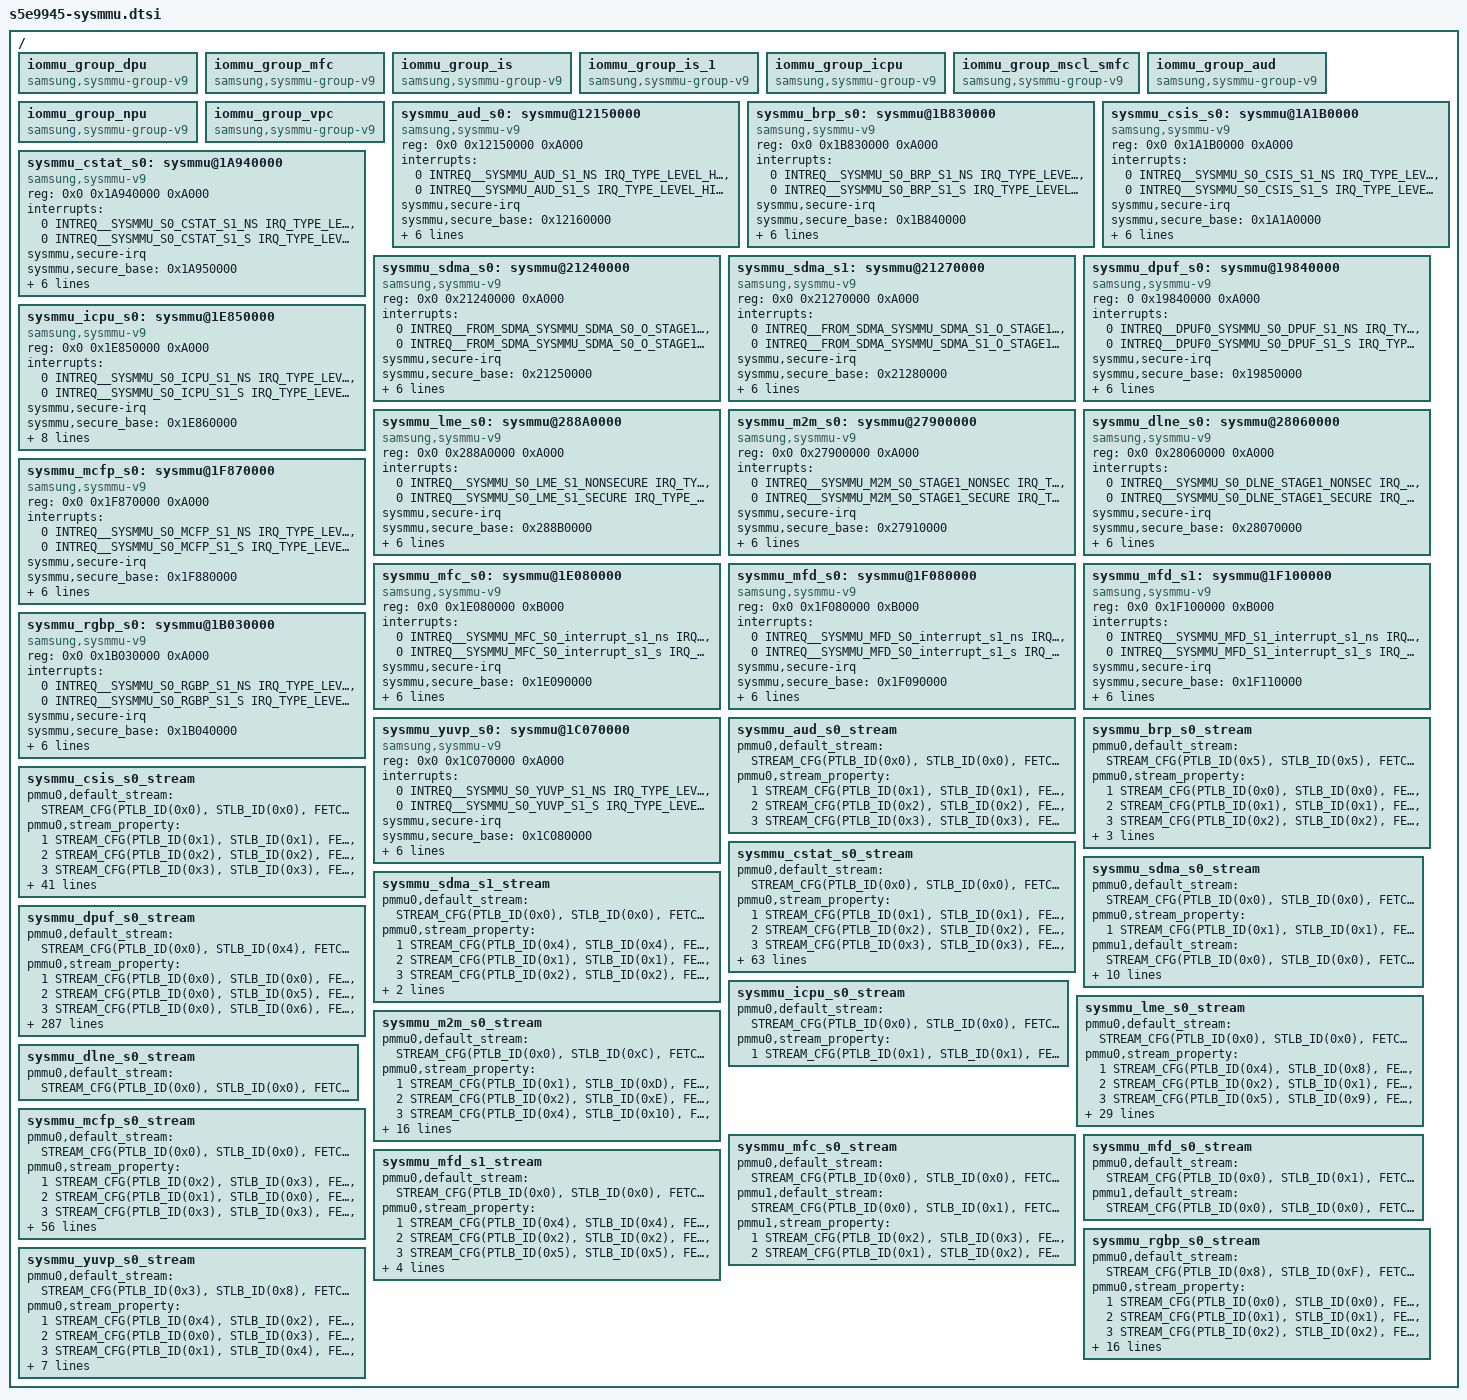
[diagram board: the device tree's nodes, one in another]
// SPDX-License-Identifier: GPL-2.0
/*
 * SAMSUNG S5E9945 SoC device tree source
 *
 * Copyright (c) 2022 Samsung Electronics Co., Ltd.
 *      http://www.samsung.com
 *
 * SAMSUNG S5E9945 SoC device nodes are listed in this file.
 * S5E9945 based board files can include this file and provide
 * values for board specific bindings.
 *
 * This program is free software; you can redistribute it and/or modify
 * it under the terms of the GNU General Public License version 2 as
 * published by the Free Software Foundation.
 */

#include <dt-bindings/interrupt-controller/arm-gic.h>
#include <dt-bindings/soc/samsung,sysmmu-v9.h>

/ {
	iommu_group_dpu: iommu_group_dpu {
		compatible = "samsung,sysmmu-group-v9";
	};

	iommu_group_mfc: iommu_group_mfc {
		compatible = "samsung,sysmmu-group-v9";
	};

	iommu_group_is: iommu_group_is {
		compatible = "samsung,sysmmu-group-v9";
	};

	iommu_group_is_1: iommu_group_is_1 {
		compatible = "samsung,sysmmu-group-v9";
	};

	iommu_group_icpu: iommu_group_icpu {
		compatible = "samsung,sysmmu-group-v9";
	};

	iommu_group_mscl_smfc: iommu_group_mscl_smfc {
		compatible = "samsung,sysmmu-group-v9";
	};

	iommu_group_aud: iommu_group_aud {
		compatible = "samsung,sysmmu-group-v9";
	};

	iommu_group_npu: iommu_group_npu {
		compatible = "samsung,sysmmu-group-v9";
	};

	iommu_group_vpc: iommu_group_vpc {
		compatible = "samsung,sysmmu-group-v9";
	};

	sysmmu_aud_s0: sysmmu@12150000 {
		compatible = "samsung,sysmmu-v9";
		reg = <0x0 0x12150000 0xA000>;
		interrupts = <0 INTREQ__SYSMMU_AUD_S1_NS IRQ_TYPE_LEVEL_HIGH>,
				<0 INTREQ__SYSMMU_AUD_S1_S IRQ_TYPE_LEVEL_HIGH>;
		sysmmu,secure-irq;
		sysmmu,secure_base = <0x12160000>;
		qos = <15>;
		#iommu-cells = <0>;
		stream-property = <&sysmmu_aud_s0_stream>;
		vmid_mask = <0x3>;
		sysmmu,feature-info = <0x1>;
		port-name = "ABOX (CA32_0) ABOX (CA32_1) ...";
		power-domains = <&pd_aud>;
	};

	sysmmu_brp_s0: sysmmu@1B830000 {
		compatible = "samsung,sysmmu-v9";
		reg = <0x0 0x1B830000 0xA000>;
		interrupts = <0 INTREQ__SYSMMU_S0_BRP_S1_NS IRQ_TYPE_LEVEL_HIGH>,
				<0 INTREQ__SYSMMU_S0_BRP_S1_S IRQ_TYPE_LEVEL_HIGH>;
		sysmmu,secure-irq;
		sysmmu,secure_base = <0x1B840000>;
		qos = <15>;
		#iommu-cells = <0>;
		stream-property = <&sysmmu_brp_s0_stream>;
		vmid_mask = <0x3>;
		sysmmu,feature-info = <0x1>;
		port-name = "BYRP (M0) BYRP (M0) BYRP (M ...";
		power-domains = <&pd_brp>;
	};

	sysmmu_csis_s0: sysmmu@1A1B0000 {
		compatible = "samsung,sysmmu-v9";
		reg = <0x0 0x1A1B0000 0xA000>;
		interrupts = <0 INTREQ__SYSMMU_S0_CSIS_S1_NS IRQ_TYPE_LEVEL_HIGH>,
				<0 INTREQ__SYSMMU_S0_CSIS_S1_S IRQ_TYPE_LEVEL_HIGH>;
		sysmmu,secure-irq;
		sysmmu,secure_base = <0x1A1A0000>;
		qos = <15>;
		#iommu-cells = <0>;
		stream-property = <&sysmmu_csis_s0_stream>;
		vmid_mask = <0x3>;
		sysmmu,feature-info = <0x1>;
		port-name = "CSISX7_V1.0 (CSIS DMA0) CSI ...";
		power-domains = <&pd_csis>;
	};

	sysmmu_cstat_s0: sysmmu@1A940000 {
		compatible = "samsung,sysmmu-v9";
		reg = <0x0 0x1A940000 0xA000>;
		interrupts = <0 INTREQ__SYSMMU_S0_CSTAT_S1_NS IRQ_TYPE_LEVEL_HIGH>,
				<0 INTREQ__SYSMMU_S0_CSTAT_S1_S IRQ_TYPE_LEVEL_HIGH>;
		sysmmu,secure-irq;
		sysmmu,secure_base = <0x1A950000>;
		qos = <15>;
		#iommu-cells = <0>;
		stream-property = <&sysmmu_cstat_s0_stream>;
		vmid_mask = <0x3>;
		sysmmu,feature-info = <0x1>;
		port-name = "CSTAT_RD0_RGBYHIST CSTAT_RD ...";
		power-domains = <&pd_cstat>;
	};

	sysmmu_sdma_s0: sysmmu@21240000 {
		compatible = "samsung,sysmmu-v9";
		reg = <0x0 0x21240000 0xA000>;
		interrupts = <0 INTREQ__FROM_SDMA_SYSMMU_SDMA_S0_O_STAGE1_NONSEC IRQ_TYPE_LEVEL_HIGH>,
				<0 INTREQ__FROM_SDMA_SYSMMU_SDMA_S0_O_STAGE1_SECURE IRQ_TYPE_LEVEL_HIGH>;
		sysmmu,secure-irq;
		sysmmu,secure_base = <0x21250000>;
		qos = <15>;
		#iommu-cells = <0>;
		stream-property = <&sysmmu_sdma_s0_stream>;
		vmid_mask = <0x3>;
		sysmmu,feature-info = <0x1>;
		port-name = "IP_SDMA (BUSD0) IP_SDMA (BU ...";
		power-domains = <&pd_sdma>;
	};

	sysmmu_sdma_s1: sysmmu@21270000 {
		compatible = "samsung,sysmmu-v9";
		reg = <0x0 0x21270000 0xA000>;
		interrupts = <0 INTREQ__FROM_SDMA_SYSMMU_SDMA_S1_O_STAGE1_NONSEC IRQ_TYPE_LEVEL_HIGH>,
				<0 INTREQ__FROM_SDMA_SYSMMU_SDMA_S1_O_STAGE1_SECURE IRQ_TYPE_LEVEL_HIGH>;
		sysmmu,secure-irq;
		sysmmu,secure_base = <0x21280000>;
		qos = <15>;
		#iommu-cells = <0>;
		stream-property = <&sysmmu_sdma_s1_stream>;
		vmid_mask = <0x3>;
		sysmmu,feature-info = <0x1>;
		port-name = "IP_DNC (DRAM)";
		power-domains = <&pd_sdma>;
	};

	sysmmu_dpuf_s0: sysmmu@19840000 {
		compatible = "samsung,sysmmu-v9";
		reg = <0 0x19840000 0xA000>;
		interrupts = <0 INTREQ__DPUF0_SYSMMU_S0_DPUF_S1_NS IRQ_TYPE_LEVEL_HIGH>,
				<0 INTREQ__DPUF0_SYSMMU_S0_DPUF_S1_S IRQ_TYPE_LEVEL_HIGH>;
		sysmmu,secure-irq;
		sysmmu,secure_base = <0x19850000>;
		qos = <15>;
		#iommu-cells = <0>;
		stream-property = <&sysmmu_dpuf_s0_stream>;
		vmid_mask = <0x3>;
		sysmmu,feature-info = <0x1>;
		port-name = "DPU_DMA_TOP";
		power-domains = <&pd_dpuf1>;
	};

	sysmmu_icpu_s0: sysmmu@1E850000 {
		compatible = "samsung,sysmmu-v9";
		reg = <0x0 0x1E850000 0xA000>;
		interrupts = <0 INTREQ__SYSMMU_S0_ICPU_S1_NS IRQ_TYPE_LEVEL_HIGH>,
				<0 INTREQ__SYSMMU_S0_ICPU_S1_S  IRQ_TYPE_LEVEL_HIGH>;
		sysmmu,secure-irq;
		sysmmu,secure_base = <0x1E860000>;
		sysmmu,async-fault;
		qos = <15>;
		#iommu-cells = <0>;
		stream-property = <&sysmmu_icpu_s0_stream>;
		vmid_mask = <0x3>;
		sysmmu,feature-info = <0x1>;
		sysmmu,cacheable-override;
		port-name = "ICPU (CA53)";
		power-domains = <&pd_icpu>;
	};

	sysmmu_lme_s0: sysmmu@288A0000 {
		compatible = "samsung,sysmmu-v9";
		reg = <0x0 0x288A0000 0xA000>;
		interrupts = <0 INTREQ__SYSMMU_S0_LME_S1_NONSECURE IRQ_TYPE_LEVEL_HIGH>,
				<0 INTREQ__SYSMMU_S0_LME_S1_SECURE IRQ_TYPE_LEVEL_HIGH>;
		sysmmu,secure-irq;
		sysmmu,secure_base = <0x288B0000>;
		qos = <15>;
		#iommu-cells = <0>;
		stream-property = <&sysmmu_lme_s0_stream>;
		vmid_mask = <0x3>;
		sysmmu,feature-info = <0x1>;
		port-name = "GDC_M (M0) GDC_M (M1) GDC_M ...";
		power-domains = <&pd_lme>;
	};

	sysmmu_m2m_s0: sysmmu@27900000 {
		compatible = "samsung,sysmmu-v9";
		reg = <0x0 0x27900000 0xA000>;
		interrupts = <0 INTREQ__SYSMMU_M2M_S0_STAGE1_NONSEC IRQ_TYPE_LEVEL_HIGH>,
				<0 INTREQ__SYSMMU_M2M_S0_STAGE1_SECURE IRQ_TYPE_LEVEL_HIGH>;
		sysmmu,secure-irq;
		sysmmu,secure_base = <0x27910000>;
		qos = <15>;
		#iommu-cells = <0>;
		stream-property = <&sysmmu_m2m_s0_stream>;
		vmid_mask = <0x3>;
		sysmmu,feature-info = <0x1>;
		port-name = "JPEG0 JPEG1 M2M(M2M_SCALER_ ...)";
		power-domains = <&pd_m2m>;
	};

	sysmmu_dlne_s0: sysmmu@28060000 {
		compatible = "samsung,sysmmu-v9";
		reg = <0x0 0x28060000 0xA000>;
		interrupts = <0 INTREQ__SYSMMU_S0_DLNE_STAGE1_NONSEC IRQ_TYPE_LEVEL_HIGH>,
				<0 INTREQ__SYSMMU_S0_DLNE_STAGE1_SECURE IRQ_TYPE_LEVEL_HIGH>;
		sysmmu,secure-irq;
		sysmmu,secure_base = <0x28070000>;
		qos = <15>;
		#iommu-cells = <0>;
		stream-property = <&sysmmu_dlne_s0_stream>;
		vmid_mask = <0x3>;
		sysmmu,feature-info = <0x1>;
		port-name = "DLNE_M0";
		power-domains = <&pd_dlne>;
	};

	sysmmu_mcfp_s0: sysmmu@1F870000 {
		compatible = "samsung,sysmmu-v9";
		reg = <0x0 0x1F870000 0xA000>;
		interrupts = <0 INTREQ__SYSMMU_S0_MCFP_S1_NS IRQ_TYPE_LEVEL_HIGH>,
				<0 INTREQ__SYSMMU_S0_MCFP_S1_S IRQ_TYPE_LEVEL_HIGH>;
		sysmmu,secure-irq;
		sysmmu,secure_base = <0x1F880000>;
		qos = <15>;
		#iommu-cells = <0>;
		stream-property = <&sysmmu_mcfp_s0_stream>;
		vmid_mask = <0x3>;
		sysmmu,feature-info = <0x1>;
		port-name = "MCFP_M0 MCFP_M1 MCSC_M1 MCS ...";
		power-domains = <&pd_mcsc>;
	};

	sysmmu_mfc_s0: sysmmu@1E080000 {
		compatible = "samsung,sysmmu-v9";
		reg = <0x0 0x1E080000 0xB000>;
		interrupts = <0 INTREQ__SYSMMU_MFC_S0_interrupt_s1_ns IRQ_TYPE_LEVEL_HIGH>,
				<0 INTREQ__SYSMMU_MFC_S0_interrupt_s1_s IRQ_TYPE_LEVEL_HIGH>;
		sysmmu,secure-irq;
		sysmmu,secure_base = <0x1E090000>;
		qos = <15>;
		#iommu-cells = <0>;
		stream-property = <&sysmmu_mfc_s0_stream>;
		vmid_mask = <0x7>;
		sysmmu,feature-info = <0x1>;
		port-name = "FIMV_MFC_V18.0 (M0) FIMV_MF ...";
		power-domains = <&pd_mfc>;
	};

	sysmmu_mfd_s0: sysmmu@1F080000 {
		compatible = "samsung,sysmmu-v9";
		reg = <0x0 0x1F080000 0xB000>;
		interrupts = <0 INTREQ__SYSMMU_MFD_S0_interrupt_s1_ns IRQ_TYPE_LEVEL_HIGH>,
				<0 INTREQ__SYSMMU_MFD_S0_interrupt_s1_s IRQ_TYPE_LEVEL_HIGH>;
		sysmmu,secure-irq;
		sysmmu,secure_base = <0x1F090000>;
		qos = <15>;
		#iommu-cells = <0>;
		stream-property = <&sysmmu_mfd_s0_stream>;
		vmid_mask = <0x7>;
		sysmmu,feature-info = <0x1>;
		port-name = "FIMV_MFD_V18.0 (M0) FIMV_MF ...";
		power-domains = <&pd_mfd>;
	};

	sysmmu_mfd_s1: sysmmu@1F100000 {
		compatible = "samsung,sysmmu-v9";
		reg = <0x0 0x1F100000 0xB000>;
		interrupts = <0 INTREQ__SYSMMU_MFD_S1_interrupt_s1_ns IRQ_TYPE_LEVEL_HIGH>,
				<0 INTREQ__SYSMMU_MFD_S1_interrupt_s1_s IRQ_TYPE_LEVEL_HIGH>;
		sysmmu,secure-irq;
		sysmmu,secure_base = <0x1F110000>;
		qos = <15>;
		#iommu-cells = <0>;
		stream-property = <&sysmmu_mfd_s1_stream>;
		vmid_mask = <0x7>;
		sysmmu,feature-info = <0x1>;
		port-name = "FIMV_MFD_V18.0 (M2) FIMV_MF ...";
		power-domains = <&pd_mfd>;
	};

	sysmmu_rgbp_s0: sysmmu@1B030000 {
		compatible = "samsung,sysmmu-v9";
		reg = <0x0 0x1B030000 0xA000>;
		interrupts = <0 INTREQ__SYSMMU_S0_RGBP_S1_NS IRQ_TYPE_LEVEL_HIGH>,
				<0 INTREQ__SYSMMU_S0_RGBP_S1_S IRQ_TYPE_LEVEL_HIGH>;
		sysmmu,secure-irq;
		sysmmu,secure_base = <0x1B040000>;
		qos = <15>;
		#iommu-cells = <0>;
		stream-property = <&sysmmu_rgbp_s0_stream>;
		vmid_mask = <0x3>;
		sysmmu,feature-info = <0x1>;
		port-name = "RGBP (M0) RGBP (M0) RGBP (M ...";
		power-domains = <&pd_rgbp>;
	};

	sysmmu_yuvp_s0: sysmmu@1C070000 {
		compatible = "samsung,sysmmu-v9";
		reg = <0x0 0x1C070000 0xA000>;
		interrupts = <0 INTREQ__SYSMMU_S0_YUVP_S1_NS IRQ_TYPE_LEVEL_HIGH>,
				<0 INTREQ__SYSMMU_S0_YUVP_S1_S IRQ_TYPE_LEVEL_HIGH>;
		sysmmu,secure-irq;
		sysmmu,secure_base = <0x1C080000>;
		qos = <15>;
		#iommu-cells = <0>;
		stream-property = <&sysmmu_yuvp_s0_stream>;
		vmid_mask = <0x3>;
		sysmmu,feature-info = <0x1>;
		port-name = "YUVP_M0_CL_VOTFR YUVP_M1_Y_ ...";
		power-domains = <&pd_yuvp>;
	};

	sysmmu_aud_s0_stream: sysmmu_aud_s0_stream {
		pmmu0,default_stream =
		<STREAM_CFG(PTLB_ID(0x0), STLB_ID(0x0), FETCH_SIZE(SIZE1), PTLB_DIS, STLB_DIS)>;
		pmmu0,stream_property =
		<1 STREAM_CFG(PTLB_ID(0x1), STLB_ID(0x1), FETCH_SIZE(SIZE1), PTLB_DIS, STLB_DIS)
		 STREAM_MATCH_CFG(DIR_RW)
		 STREAM_MATCH_SID_VALUE(0x3)
		 STREAM_MATCH_SID_MASK(0xF)>,
		<2 STREAM_CFG(PTLB_ID(0x2), STLB_ID(0x2), FETCH_SIZE(SIZE1), PTLB_DIS, STLB_DIS)
		 STREAM_MATCH_CFG(DIR_RW)
		 STREAM_MATCH_SID_VALUE(0x5)
		 STREAM_MATCH_SID_MASK(0xF)>,
		<3 STREAM_CFG(PTLB_ID(0x3), STLB_ID(0x3), FETCH_SIZE(SIZE1), PTLB_DIS, STLB_DIS)
		 STREAM_MATCH_CFG(DIR_RW)
		 STREAM_MATCH_SID_VALUE(0x6)
		 STREAM_MATCH_SID_MASK(0xF)>;
	};

	sysmmu_brp_s0_stream: sysmmu_brp_s0_stream {
		pmmu0,default_stream =
		<STREAM_CFG(PTLB_ID(0x5), STLB_ID(0x5), FETCH_SIZE(SIZE1), PTLB_DIS, STLB_DIS)>;
		pmmu0,stream_property =
		<1 STREAM_CFG(PTLB_ID(0x0), STLB_ID(0x0), FETCH_SIZE(SIZE1), PTLB_DIS, STLB_EN)
		 STREAM_MATCH_CFG(DIR_WRITE)
		 STREAM_MATCH_SID_VALUE(0x0)
		 STREAM_MATCH_SID_MASK(0xF)>,
		<2 STREAM_CFG(PTLB_ID(0x1), STLB_ID(0x1), FETCH_SIZE(SIZE1), PTLB_EN, STLB_EN)
		 STREAM_MATCH_CFG(DIR_READ)
		 STREAM_MATCH_SID_VALUE(0x1)
		 STREAM_MATCH_SID_MASK(0xF)>,
		<3 STREAM_CFG(PTLB_ID(0x2), STLB_ID(0x2), FETCH_SIZE(SIZE1), PTLB_EN, STLB_EN)
		 STREAM_MATCH_CFG(DIR_READ)
		 STREAM_MATCH_SID_VALUE(0x5)
		 STREAM_MATCH_SID_MASK(0xF)>,
		<4 STREAM_CFG(PTLB_ID(0x3), STLB_ID(0x3), FETCH_SIZE(SIZE1), PTLB_DIS, STLB_EN)
		 STREAM_MATCH_CFG(DIR_WRITE)
		 STREAM_MATCH_SID_VALUE(0x1)
		 STREAM_MATCH_SID_MASK(0xF)>,
		<5 STREAM_CFG(PTLB_ID(0x4), STLB_ID(0x4), FETCH_SIZE(SIZE1), PTLB_DIS, STLB_EN)
		 STREAM_MATCH_CFG(DIR_WRITE)
		 STREAM_MATCH_SID_VALUE(0x2)
		 STREAM_MATCH_SID_MASK(0xF)>,
		<6 STREAM_CFG(PTLB_ID(0x6), STLB_ID(0x6), FETCH_SIZE(SIZE1), PTLB_DIS, STLB_DIS)
		 STREAM_MATCH_CFG(DIR_WRITE)
		 STREAM_MATCH_SID_VALUE(0x3)
		 STREAM_MATCH_SID_MASK(0xF)>;
	};

	sysmmu_csis_s0_stream: sysmmu_csis_s0_stream {
		pmmu0,default_stream =
		<STREAM_CFG(PTLB_ID(0x0), STLB_ID(0x0), FETCH_SIZE(SIZE1), PTLB_DIS, STLB_EN)>;
		pmmu0,stream_property =
		<1 STREAM_CFG(PTLB_ID(0x1), STLB_ID(0x1), FETCH_SIZE(SIZE1), PTLB_DIS, STLB_EN)
		 STREAM_MATCH_CFG(DIR_WRITE)
		 STREAM_MATCH_SID_VALUE(0x2)
		 STREAM_MATCH_SID_MASK(0xF)>,
		<2 STREAM_CFG(PTLB_ID(0x2), STLB_ID(0x2), FETCH_SIZE(SIZE1), PTLB_DIS, STLB_EN)
		 STREAM_MATCH_CFG(DIR_WRITE)
		 STREAM_MATCH_SID_VALUE(0x4)
		 STREAM_MATCH_SID_MASK(0xF)>,
		<3 STREAM_CFG(PTLB_ID(0x3), STLB_ID(0x3), FETCH_SIZE(SIZE1), PTLB_DIS, STLB_EN)
		 STREAM_MATCH_CFG(DIR_WRITE)
		 STREAM_MATCH_SID_VALUE(0x8)
		 STREAM_MATCH_SID_MASK(0xF)>,
		<4 STREAM_CFG(PTLB_ID(0x4), STLB_ID(0x4), FETCH_SIZE(SIZE1), PTLB_DIS, STLB_EN)
		 STREAM_MATCH_CFG(DIR_WRITE)
		 STREAM_MATCH_SID_VALUE(0xC)
		 STREAM_MATCH_SID_MASK(0xF)>,
		<5 STREAM_CFG(PTLB_ID(0x5), STLB_ID(0x5), FETCH_SIZE(SIZE1), PTLB_DIS, STLB_EN)
		 STREAM_MATCH_CFG(DIR_WRITE)
		 STREAM_MATCH_SID_VALUE(0x1)
		 STREAM_MATCH_SID_MASK(0xF)>,
		<6 STREAM_CFG(PTLB_ID(0x6), STLB_ID(0x6), FETCH_SIZE(SIZE1), PTLB_DIS, STLB_EN)
		 STREAM_MATCH_CFG(DIR_WRITE)
		 STREAM_MATCH_SID_VALUE(0x3)
		 STREAM_MATCH_SID_MASK(0xF)>,
		<7 STREAM_CFG(PTLB_ID(0x7), STLB_ID(0x7), FETCH_SIZE(SIZE1), PTLB_DIS, STLB_EN)
		 STREAM_MATCH_CFG(DIR_WRITE)
		 STREAM_MATCH_SID_VALUE(0x5)
		 STREAM_MATCH_SID_MASK(0xF)>,
		<8 STREAM_CFG(PTLB_ID(0x8), STLB_ID(0x8), FETCH_SIZE(SIZE1), PTLB_DIS, STLB_EN)
		 STREAM_MATCH_CFG(DIR_WRITE)
		 STREAM_MATCH_SID_VALUE(0x9)
		 STREAM_MATCH_SID_MASK(0xF)>,
		<9 STREAM_CFG(PTLB_ID(0x9), STLB_ID(0x9), FETCH_SIZE(SIZE1), PTLB_DIS, STLB_EN)
		 STREAM_MATCH_CFG(DIR_WRITE)
		 STREAM_MATCH_SID_VALUE(0xD)
		 STREAM_MATCH_SID_MASK(0xF)>;
		pmmu1,default_stream =
		<STREAM_CFG(PTLB_ID(0x0), STLB_ID(0xA), FETCH_SIZE(SIZE1), PTLB_DIS, STLB_EN)>;
		pmmu1,stream_property =
		<1 STREAM_CFG(PTLB_ID(0x1), STLB_ID(0xB), FETCH_SIZE(SIZE1), PTLB_DIS, STLB_EN)
		 STREAM_MATCH_CFG(DIR_WRITE)
		 STREAM_MATCH_SID_VALUE(0x4)
		 STREAM_MATCH_SID_MASK(0x1F)>,
		<2 STREAM_CFG(PTLB_ID(0x2), STLB_ID(0xC), FETCH_SIZE(SIZE1), PTLB_DIS, STLB_EN)
		 STREAM_MATCH_CFG(DIR_WRITE)
		 STREAM_MATCH_SID_VALUE(0x8)
		 STREAM_MATCH_SID_MASK(0x1F)>,
		<3 STREAM_CFG(PTLB_ID(0x3), STLB_ID(0xD), FETCH_SIZE(SIZE1), PTLB_DIS, STLB_EN)
		 STREAM_MATCH_CFG(DIR_WRITE)
		 STREAM_MATCH_SID_VALUE(0x10)
		 STREAM_MATCH_SID_MASK(0x1F)>,
		<4 STREAM_CFG(PTLB_ID(0x4), STLB_ID(0xE), FETCH_SIZE(SIZE1), PTLB_DIS, STLB_EN)
		 STREAM_MATCH_CFG(DIR_WRITE)
		 STREAM_MATCH_SID_VALUE(0x18)
		 STREAM_MATCH_SID_MASK(0x1F)>,
		<5 STREAM_CFG(PTLB_ID(0x5), STLB_ID(0xF), FETCH_SIZE(SIZE1), PTLB_DIS, STLB_EN)
		 STREAM_MATCH_CFG(DIR_WRITE)
		 STREAM_MATCH_SID_VALUE(0x1)
		 STREAM_MATCH_SID_MASK(0x1F)>,
		<6 STREAM_CFG(PTLB_ID(0x6), STLB_ID(0x10), FETCH_SIZE(SIZE1), PTLB_DIS, STLB_EN)
		 STREAM_MATCH_CFG(DIR_WRITE)
		 STREAM_MATCH_SID_VALUE(0x5)
		 STREAM_MATCH_SID_MASK(0x1F)>,
		<7 STREAM_CFG(PTLB_ID(0x7), STLB_ID(0x11), FETCH_SIZE(SIZE1), PTLB_DIS, STLB_EN)
		 STREAM_MATCH_CFG(DIR_WRITE)
		 STREAM_MATCH_SID_VALUE(0x9)
		 STREAM_MATCH_SID_MASK(0x1F)>,
		<8 STREAM_CFG(PTLB_ID(0x8), STLB_ID(0x12), FETCH_SIZE(SIZE1), PTLB_DIS, STLB_EN)
		 STREAM_MATCH_CFG(DIR_WRITE)
		 STREAM_MATCH_SID_VALUE(0x11)
		 STREAM_MATCH_SID_MASK(0x1F)>,
		<9 STREAM_CFG(PTLB_ID(0x9), STLB_ID(0x13), FETCH_SIZE(SIZE1), PTLB_DIS, STLB_EN)
		 STREAM_MATCH_CFG(DIR_WRITE)
		 STREAM_MATCH_SID_VALUE(0x19)
		 STREAM_MATCH_SID_MASK(0x1F)>,
		<10 STREAM_CFG(PTLB_ID(0xA), STLB_ID(0x14), FETCH_SIZE(SIZE1), PTLB_DIS, STLB_EN)
		 STREAM_MATCH_CFG(DIR_WRITE)
		 STREAM_MATCH_SID_VALUE(0x2)
		 STREAM_MATCH_SID_MASK(0x1F)>,
		<11 STREAM_CFG(PTLB_ID(0xB), STLB_ID(0x15), FETCH_SIZE(SIZE1), PTLB_DIS, STLB_EN)
		 STREAM_MATCH_CFG(DIR_WRITE)
		 STREAM_MATCH_SID_VALUE(0x6)
		 STREAM_MATCH_SID_MASK(0x1F)>,
		<12 STREAM_CFG(PTLB_ID(0xC), STLB_ID(0x16), FETCH_SIZE(SIZE1), PTLB_DIS, STLB_EN)
		 STREAM_MATCH_CFG(DIR_WRITE)
		 STREAM_MATCH_SID_VALUE(0xA)
		 STREAM_MATCH_SID_MASK(0x1F)>,
		<13 STREAM_CFG(PTLB_ID(0xD), STLB_ID(0x17), FETCH_SIZE(SIZE1), PTLB_DIS, STLB_EN)
		 STREAM_MATCH_CFG(DIR_WRITE)
		 STREAM_MATCH_SID_VALUE(0x12)
		 STREAM_MATCH_SID_MASK(0x1F)>,
		<14 STREAM_CFG(PTLB_ID(0xE), STLB_ID(0x18), FETCH_SIZE(SIZE1), PTLB_DIS, STLB_EN)
		 STREAM_MATCH_CFG(DIR_WRITE)
		 STREAM_MATCH_SID_VALUE(0x1A)
		 STREAM_MATCH_SID_MASK(0x1F)>;
		pmmu2,default_stream =
		<STREAM_CFG(PTLB_ID(0xD), STLB_ID(0x26), FETCH_SIZE(SIZE1), PTLB_DIS, STLB_DIS)>;
		pmmu2,stream_property =
		<1 STREAM_CFG(PTLB_ID(0xE), STLB_ID(0x27), FETCH_SIZE(SIZE1), PTLB_DIS, STLB_DIS)
		 STREAM_MATCH_CFG(DIR_WRITE)
		 STREAM_MATCH_SID_VALUE(0x4)
		 STREAM_MATCH_SID_MASK(0x7)>,
		<2 STREAM_CFG(PTLB_ID(0x0), STLB_ID(0x19), FETCH_SIZE(SIZE1), PTLB_DIS, STLB_EN)
		 STREAM_MATCH_CFG(DIR_WRITE)
		 STREAM_MATCH_SID_VALUE(0x0)
		 STREAM_MATCH_SID_MASK(0xFF)>,
		<3 STREAM_CFG(PTLB_ID(0x1), STLB_ID(0x1A), FETCH_SIZE(SIZE1), PTLB_EN, STLB_EN)
		 STREAM_MATCH_CFG(DIR_READ)
		 STREAM_MATCH_SID_VALUE(0x0)
		 STREAM_MATCH_SID_MASK(0xFF)>,
		<4 STREAM_CFG(PTLB_ID(0x2), STLB_ID(0x1B), FETCH_SIZE(SIZE1), PTLB_DIS, STLB_EN)
		 STREAM_MATCH_CFG(DIR_WRITE)
		 STREAM_MATCH_SID_VALUE(0x40)
		 STREAM_MATCH_SID_MASK(0xFF)>,
		<5 STREAM_CFG(PTLB_ID(0x3), STLB_ID(0x1C), FETCH_SIZE(SIZE1), PTLB_DIS, STLB_EN)
		 STREAM_MATCH_CFG(DIR_WRITE)
		 STREAM_MATCH_SID_VALUE(0x80)
		 STREAM_MATCH_SID_MASK(0xFF)>,
		<6 STREAM_CFG(PTLB_ID(0x4), STLB_ID(0x1D), FETCH_SIZE(SIZE1), PTLB_DIS, STLB_EN)
		 STREAM_MATCH_CFG(DIR_WRITE)
		 STREAM_MATCH_SID_VALUE(0xC0)
		 STREAM_MATCH_SID_MASK(0xFF)>,
		<7 STREAM_CFG(PTLB_ID(0x5), STLB_ID(0x1E), FETCH_SIZE(SIZE1), PTLB_DIS, STLB_EN)
		 STREAM_MATCH_CFG(DIR_WRITE)
		 STREAM_MATCH_SID_VALUE(0x1)
		 STREAM_MATCH_SID_MASK(0xFF)>,
		<8 STREAM_CFG(PTLB_ID(0x6), STLB_ID(0x1F), FETCH_SIZE(SIZE1), PTLB_DIS, STLB_EN)
		 STREAM_MATCH_CFG(DIR_WRITE)
		 STREAM_MATCH_SID_VALUE(0x41)
		 STREAM_MATCH_SID_MASK(0xFF)>,
		<9 STREAM_CFG(PTLB_ID(0x7), STLB_ID(0x20), FETCH_SIZE(SIZE1), PTLB_DIS, STLB_EN)
		 STREAM_MATCH_CFG(DIR_WRITE)
		 STREAM_MATCH_SID_VALUE(0x81)
		 STREAM_MATCH_SID_MASK(0xFF)>,
		<10 STREAM_CFG(PTLB_ID(0x8), STLB_ID(0x21), FETCH_SIZE(SIZE1), PTLB_DIS, STLB_EN)
		 STREAM_MATCH_CFG(DIR_WRITE)
		 STREAM_MATCH_SID_VALUE(0xC1)
		 STREAM_MATCH_SID_MASK(0xFF)>,
		<11 STREAM_CFG(PTLB_ID(0x9), STLB_ID(0x22), FETCH_SIZE(SIZE1), PTLB_DIS, STLB_EN)
		 STREAM_MATCH_CFG(DIR_WRITE)
		 STREAM_MATCH_SID_VALUE(0x2)
		 STREAM_MATCH_SID_MASK(0xFF)>,
		<12 STREAM_CFG(PTLB_ID(0xA), STLB_ID(0x23), FETCH_SIZE(SIZE1), PTLB_DIS, STLB_EN)
		 STREAM_MATCH_CFG(DIR_WRITE)
		 STREAM_MATCH_SID_VALUE(0x42)
		 STREAM_MATCH_SID_MASK(0xFF)>,
		<13 STREAM_CFG(PTLB_ID(0xB), STLB_ID(0x24), FETCH_SIZE(SIZE1), PTLB_DIS, STLB_EN)
		 STREAM_MATCH_CFG(DIR_WRITE)
		 STREAM_MATCH_SID_VALUE(0x82)
		 STREAM_MATCH_SID_MASK(0xFF)>,
		<14 STREAM_CFG(PTLB_ID(0xC), STLB_ID(0x25), FETCH_SIZE(SIZE1), PTLB_DIS, STLB_EN)
		 STREAM_MATCH_CFG(DIR_WRITE)
		 STREAM_MATCH_SID_VALUE(0xC2)
		 STREAM_MATCH_SID_MASK(0xFF)>,
		<15 STREAM_CFG(PTLB_ID(0xF), STLB_ID(0x28), FETCH_SIZE(SIZE1), PTLB_DIS, STLB_DIS)
		 STREAM_MATCH_CFG(DIR_WRITE)
		 STREAM_MATCH_SID_VALUE(0x5)
		 STREAM_MATCH_SID_MASK(0x7)>;
	};

	sysmmu_cstat_s0_stream: sysmmu_cstat_s0_stream {
		pmmu0,default_stream =
		<STREAM_CFG(PTLB_ID(0x0), STLB_ID(0x0), FETCH_SIZE(SIZE1), PTLB_DIS, STLB_EN)>;
		pmmu0,stream_property =
		<1 STREAM_CFG(PTLB_ID(0x1), STLB_ID(0x1), FETCH_SIZE(SIZE1), PTLB_DIS, STLB_EN)
		 STREAM_MATCH_CFG(DIR_WRITE)
		 STREAM_MATCH_SID_VALUE(0x80)
		 STREAM_MATCH_SID_MASK(0x1FF)>,
		<2 STREAM_CFG(PTLB_ID(0x2), STLB_ID(0x2), FETCH_SIZE(SIZE1), PTLB_DIS, STLB_EN)
		 STREAM_MATCH_CFG(DIR_WRITE)
		 STREAM_MATCH_SID_VALUE(0x100)
		 STREAM_MATCH_SID_MASK(0x1FF)>,
		<3 STREAM_CFG(PTLB_ID(0x3), STLB_ID(0x3), FETCH_SIZE(SIZE1), PTLB_DIS, STLB_EN)
		 STREAM_MATCH_CFG(DIR_WRITE)
		 STREAM_MATCH_SID_VALUE(0x180)
		 STREAM_MATCH_SID_MASK(0x1FF)>,
		<4 STREAM_CFG(PTLB_ID(0x4), STLB_ID(0x4), FETCH_SIZE(SIZE1), PTLB_EN, STLB_EN)
		 STREAM_MATCH_CFG(DIR_READ)
		 STREAM_MATCH_SID_VALUE(0x0)
		 STREAM_MATCH_SID_MASK(0xF)>,
		<5 STREAM_CFG(PTLB_ID(0x15), STLB_ID(0x3C), FETCH_SIZE(SIZE1), PTLB_EN, STLB_EN)
		 STREAM_MATCH_CFG(DIR_READ)
		 STREAM_MATCH_SID_VALUE(0x10)
		 STREAM_MATCH_SID_MASK(0x1F)>,
		<6 STREAM_CFG(PTLB_ID(0x5), STLB_ID(0x5), FETCH_SIZE(SIZE1), PTLB_DIS, STLB_EN)
		 STREAM_MATCH_CFG(DIR_WRITE)
		 STREAM_MATCH_SID_VALUE(0x1)
		 STREAM_MATCH_SID_MASK(0xF)>,
		<7 STREAM_CFG(PTLB_ID(0x5), STLB_ID(0x7), FETCH_SIZE(SIZE1), PTLB_DIS, STLB_EN)
		 STREAM_MATCH_CFG(DIR_WRITE)
		 STREAM_MATCH_SID_VALUE(0x41)
		 STREAM_MATCH_SID_MASK(0x1FF)>,
		<8 STREAM_CFG(PTLB_ID(0x5), STLB_ID(0x8), FETCH_SIZE(SIZE1), PTLB_DIS, STLB_EN)
		 STREAM_MATCH_CFG(DIR_WRITE)
		 STREAM_MATCH_SID_VALUE(0x81)
		 STREAM_MATCH_SID_MASK(0x1FF)>,
		<9 STREAM_CFG(PTLB_ID(0x6), STLB_ID(0x9), FETCH_SIZE(SIZE1), PTLB_EN, STLB_EN)
		 STREAM_MATCH_CFG(DIR_READ)
		 STREAM_MATCH_SID_VALUE(0x1)
		 STREAM_MATCH_SID_MASK(0xF)>,
		<10 STREAM_CFG(PTLB_ID(0x7), STLB_ID(0xA), FETCH_SIZE(SIZE1), PTLB_DIS, STLB_EN)
		 STREAM_MATCH_CFG(DIR_WRITE)
		 STREAM_MATCH_SID_VALUE(0x2)
		 STREAM_MATCH_SID_MASK(0x1FF)>,
		<11 STREAM_CFG(PTLB_ID(0x7), STLB_ID(0xB), FETCH_SIZE(SIZE1), PTLB_DIS, STLB_EN)
		 STREAM_MATCH_CFG(DIR_WRITE)
		 STREAM_MATCH_SID_VALUE(0x82)
		 STREAM_MATCH_SID_MASK(0x1FF)>,
		<12 STREAM_CFG(PTLB_ID(0x7), STLB_ID(0xC), FETCH_SIZE(SIZE1), PTLB_DIS, STLB_EN)
		 STREAM_MATCH_CFG(DIR_WRITE)
		 STREAM_MATCH_SID_VALUE(0x102)
		 STREAM_MATCH_SID_MASK(0x1FF)>,
		<13 STREAM_CFG(PTLB_ID(0x7), STLB_ID(0xD), FETCH_SIZE(SIZE1), PTLB_DIS, STLB_EN)
		 STREAM_MATCH_CFG(DIR_WRITE)
		 STREAM_MATCH_SID_VALUE(0x182)
		 STREAM_MATCH_SID_MASK(0x1FF)>,
		<14 STREAM_CFG(PTLB_ID(0x8), STLB_ID(0xE), FETCH_SIZE(SIZE1), PTLB_EN, STLB_EN)
		 STREAM_MATCH_CFG(DIR_READ)
		 STREAM_MATCH_SID_VALUE(0x2)
		 STREAM_MATCH_SID_MASK(0xF)>,
		<15 STREAM_CFG(PTLB_ID(0x9), STLB_ID(0xF), FETCH_SIZE(SIZE1), PTLB_DIS, STLB_EN)
		 STREAM_MATCH_CFG(DIR_WRITE)
		 STREAM_MATCH_SID_VALUE(0x3)
		 STREAM_MATCH_SID_MASK(0x1FF)>,
		<16 STREAM_CFG(PTLB_ID(0x9), STLB_ID(0x10), FETCH_SIZE(SIZE1), PTLB_DIS, STLB_EN)
		 STREAM_MATCH_CFG(DIR_WRITE)
		 STREAM_MATCH_SID_VALUE(0x83)
		 STREAM_MATCH_SID_MASK(0x1FF)>,
		<17 STREAM_CFG(PTLB_ID(0x9), STLB_ID(0x11), FETCH_SIZE(SIZE1), PTLB_DIS, STLB_EN)
		 STREAM_MATCH_CFG(DIR_WRITE)
		 STREAM_MATCH_SID_VALUE(0x103)
		 STREAM_MATCH_SID_MASK(0x1FF)>,
		<18 STREAM_CFG(PTLB_ID(0x9), STLB_ID(0x12), FETCH_SIZE(SIZE1), PTLB_DIS, STLB_EN)
		 STREAM_MATCH_CFG(DIR_WRITE)
		 STREAM_MATCH_SID_VALUE(0x183)
		 STREAM_MATCH_SID_MASK(0x1FF)>,
		<19 STREAM_CFG(PTLB_ID(0xA), STLB_ID(0x13), FETCH_SIZE(SIZE1), PTLB_EN, STLB_EN)
		 STREAM_MATCH_CFG(DIR_READ)
		 STREAM_MATCH_SID_VALUE(0x3)
		 STREAM_MATCH_SID_MASK(0xF)>,
		<20 STREAM_CFG(PTLB_ID(0xB), STLB_ID(0x14), FETCH_SIZE(SIZE1), PTLB_DIS, STLB_EN)
		 STREAM_MATCH_CFG(DIR_WRITE)
		 STREAM_MATCH_SID_VALUE(0x4)
		 STREAM_MATCH_SID_MASK(0x1FF)>,
		<21 STREAM_CFG(PTLB_ID(0xB), STLB_ID(0x15), FETCH_SIZE(SIZE1), PTLB_DIS, STLB_EN)
		 STREAM_MATCH_CFG(DIR_WRITE)
		 STREAM_MATCH_SID_VALUE(0x84)
		 STREAM_MATCH_SID_MASK(0x1FF)>,
		<22 STREAM_CFG(PTLB_ID(0xB), STLB_ID(0x16), FETCH_SIZE(SIZE1), PTLB_DIS, STLB_EN)
		 STREAM_MATCH_CFG(DIR_WRITE)
		 STREAM_MATCH_SID_VALUE(0x104)
		 STREAM_MATCH_SID_MASK(0x1FF)>,
		<23 STREAM_CFG(PTLB_ID(0xB), STLB_ID(0x17), FETCH_SIZE(SIZE1), PTLB_DIS, STLB_EN)
		 STREAM_MATCH_CFG(DIR_WRITE)
		 STREAM_MATCH_SID_VALUE(0x184)
		 STREAM_MATCH_SID_MASK(0x1FF)>,
		<24 STREAM_CFG(PTLB_ID(0x16), STLB_ID(0x3D), FETCH_SIZE(SIZE1), PTLB_EN, STLB_DIS)
		 STREAM_MATCH_CFG(DIR_READ)
		 STREAM_MATCH_SID_VALUE(0x4)
		 STREAM_MATCH_SID_MASK(0xF)>,
		<25 STREAM_CFG(PTLB_ID(0xC), STLB_ID(0x18), FETCH_SIZE(SIZE1), PTLB_DIS, STLB_EN)
		 STREAM_MATCH_CFG(DIR_WRITE)
		 STREAM_MATCH_SID_VALUE(0x5)
		 STREAM_MATCH_SID_MASK(0x1FF)>,
		<26 STREAM_CFG(PTLB_ID(0xC), STLB_ID(0x19), FETCH_SIZE(SIZE1), PTLB_DIS, STLB_EN)
		 STREAM_MATCH_CFG(DIR_WRITE)
		 STREAM_MATCH_SID_VALUE(0x85)
		 STREAM_MATCH_SID_MASK(0x1FF)>,
		<27 STREAM_CFG(PTLB_ID(0xC), STLB_ID(0x1A), FETCH_SIZE(SIZE1), PTLB_DIS, STLB_EN)
		 STREAM_MATCH_CFG(DIR_WRITE)
		 STREAM_MATCH_SID_VALUE(0x105)
		 STREAM_MATCH_SID_MASK(0x1FF)>,
		<28 STREAM_CFG(PTLB_ID(0xC), STLB_ID(0x1B), FETCH_SIZE(SIZE1), PTLB_DIS, STLB_EN)
		 STREAM_MATCH_CFG(DIR_WRITE)
		 STREAM_MATCH_SID_VALUE(0x185)
		 STREAM_MATCH_SID_MASK(0x1FF)>,
		<29 STREAM_CFG(PTLB_ID(0x17), STLB_ID(0x3E), FETCH_SIZE(SIZE1), PTLB_EN, STLB_DIS)
		 STREAM_MATCH_CFG(DIR_READ)
		 STREAM_MATCH_SID_VALUE(0x5)
		 STREAM_MATCH_SID_MASK(0xF)>,
		<30 STREAM_CFG(PTLB_ID(0xD), STLB_ID(0x1C), FETCH_SIZE(SIZE1), PTLB_DIS, STLB_EN)
		 STREAM_MATCH_CFG(DIR_WRITE)
		 STREAM_MATCH_SID_VALUE(0x6)
		 STREAM_MATCH_SID_MASK(0x1FF)>,
		<31 STREAM_CFG(PTLB_ID(0xD), STLB_ID(0x1D), FETCH_SIZE(SIZE1), PTLB_DIS, STLB_EN)
		 STREAM_MATCH_CFG(DIR_WRITE)
		 STREAM_MATCH_SID_VALUE(0x86)
		 STREAM_MATCH_SID_MASK(0x1FF)>,
		<32 STREAM_CFG(PTLB_ID(0xD), STLB_ID(0x1E), FETCH_SIZE(SIZE1), PTLB_DIS, STLB_EN)
		 STREAM_MATCH_CFG(DIR_WRITE)
		 STREAM_MATCH_SID_VALUE(0x106)
		 STREAM_MATCH_SID_MASK(0x1FF)>,
		<33 STREAM_CFG(PTLB_ID(0xD), STLB_ID(0x1F), FETCH_SIZE(SIZE1), PTLB_DIS, STLB_EN)
		 STREAM_MATCH_CFG(DIR_WRITE)
		 STREAM_MATCH_SID_VALUE(0x186)
		 STREAM_MATCH_SID_MASK(0x1FF)>,
		<34 STREAM_CFG(PTLB_ID(0x18), STLB_ID(0x3F), FETCH_SIZE(SIZE1), PTLB_EN, STLB_DIS)
		 STREAM_MATCH_CFG(DIR_READ)
		 STREAM_MATCH_SID_VALUE(0x6)
		 STREAM_MATCH_SID_MASK(0xF)>,
		<35 STREAM_CFG(PTLB_ID(0xE), STLB_ID(0x20), FETCH_SIZE(SIZE1), PTLB_DIS, STLB_EN)
		 STREAM_MATCH_CFG(DIR_WRITE)
		 STREAM_MATCH_SID_VALUE(0x7)
		 STREAM_MATCH_SID_MASK(0x1FF)>,
		<36 STREAM_CFG(PTLB_ID(0xE), STLB_ID(0x21), FETCH_SIZE(SIZE1), PTLB_DIS, STLB_EN)
		 STREAM_MATCH_CFG(DIR_WRITE)
		 STREAM_MATCH_SID_VALUE(0x87)
		 STREAM_MATCH_SID_MASK(0x1FF)>,
		<37 STREAM_CFG(PTLB_ID(0xE), STLB_ID(0x22), FETCH_SIZE(SIZE1), PTLB_DIS, STLB_EN)
		 STREAM_MATCH_CFG(DIR_WRITE)
		 STREAM_MATCH_SID_VALUE(0x107)
		 STREAM_MATCH_SID_MASK(0x1FF)>,
		<38 STREAM_CFG(PTLB_ID(0xE), STLB_ID(0x23), FETCH_SIZE(SIZE1), PTLB_DIS, STLB_EN)
		 STREAM_MATCH_CFG(DIR_WRITE)
		 STREAM_MATCH_SID_VALUE(0x187)
		 STREAM_MATCH_SID_MASK(0x1FF)>,
		<39 STREAM_CFG(PTLB_ID(0x19), STLB_ID(0x40), FETCH_SIZE(SIZE1), PTLB_EN, STLB_DIS)
		 STREAM_MATCH_CFG(DIR_READ)
		 STREAM_MATCH_SID_VALUE(0x7)
		 STREAM_MATCH_SID_MASK(0xF)>,
		<40 STREAM_CFG(PTLB_ID(0xF), STLB_ID(0x24), FETCH_SIZE(SIZE1), PTLB_DIS, STLB_EN)
		 STREAM_MATCH_CFG(DIR_WRITE)
		 STREAM_MATCH_SID_VALUE(0x8)
		 STREAM_MATCH_SID_MASK(0x1FF)>,
		<41 STREAM_CFG(PTLB_ID(0xF), STLB_ID(0x25), FETCH_SIZE(SIZE1), PTLB_DIS, STLB_EN)
		 STREAM_MATCH_CFG(DIR_WRITE)
		 STREAM_MATCH_SID_VALUE(0x88)
		 STREAM_MATCH_SID_MASK(0x1FF)>,
		<42 STREAM_CFG(PTLB_ID(0xF), STLB_ID(0x26), FETCH_SIZE(SIZE1), PTLB_DIS, STLB_EN)
		 STREAM_MATCH_CFG(DIR_WRITE)
		 STREAM_MATCH_SID_VALUE(0x108)
		 STREAM_MATCH_SID_MASK(0x1FF)>,
		<43 STREAM_CFG(PTLB_ID(0xF), STLB_ID(0x27), FETCH_SIZE(SIZE1), PTLB_DIS, STLB_EN)
		 STREAM_MATCH_CFG(DIR_WRITE)
		 STREAM_MATCH_SID_VALUE(0x188)
		 STREAM_MATCH_SID_MASK(0x1FF)>,
		<44 STREAM_CFG(PTLB_ID(0x10), STLB_ID(0x28), FETCH_SIZE(SIZE1), PTLB_DIS, STLB_EN)
		 STREAM_MATCH_CFG(DIR_WRITE)
		 STREAM_MATCH_SID_VALUE(0x28)
		 STREAM_MATCH_SID_MASK(0x1FF)>,
		<45 STREAM_CFG(PTLB_ID(0x10), STLB_ID(0x29), FETCH_SIZE(SIZE1), PTLB_DIS, STLB_EN)
		 STREAM_MATCH_CFG(DIR_WRITE)
		 STREAM_MATCH_SID_VALUE(0xA8)
		 STREAM_MATCH_SID_MASK(0x1FF)>,
		<46 STREAM_CFG(PTLB_ID(0x10), STLB_ID(0x2A), FETCH_SIZE(SIZE1), PTLB_DIS, STLB_EN)
		 STREAM_MATCH_CFG(DIR_WRITE)
		 STREAM_MATCH_SID_VALUE(0x128)
		 STREAM_MATCH_SID_MASK(0x1FF)>,
		<47 STREAM_CFG(PTLB_ID(0x10), STLB_ID(0x2B), FETCH_SIZE(SIZE1), PTLB_DIS, STLB_EN)
		 STREAM_MATCH_CFG(DIR_WRITE)
		 STREAM_MATCH_SID_VALUE(0x1A8)
		 STREAM_MATCH_SID_MASK(0x1FF)>,
		<48 STREAM_CFG(PTLB_ID(0x11), STLB_ID(0x2C), FETCH_SIZE(SIZE1), PTLB_DIS, STLB_EN)
		 STREAM_MATCH_CFG(DIR_WRITE)
		 STREAM_MATCH_SID_VALUE(0x9)
		 STREAM_MATCH_SID_MASK(0x1FF)>,
		<49 STREAM_CFG(PTLB_ID(0x11), STLB_ID(0x2D), FETCH_SIZE(SIZE1), PTLB_DIS, STLB_EN)
		 STREAM_MATCH_CFG(DIR_WRITE)
		 STREAM_MATCH_SID_VALUE(0x89)
		 STREAM_MATCH_SID_MASK(0x1FF)>,
		<50 STREAM_CFG(PTLB_ID(0x11), STLB_ID(0x2E), FETCH_SIZE(SIZE1), PTLB_DIS, STLB_EN)
		 STREAM_MATCH_CFG(DIR_WRITE)
		 STREAM_MATCH_SID_VALUE(0x109)
		 STREAM_MATCH_SID_MASK(0x1FF)>,
		<51 STREAM_CFG(PTLB_ID(0x11), STLB_ID(0x2F), FETCH_SIZE(SIZE1), PTLB_DIS, STLB_EN)
		 STREAM_MATCH_CFG(DIR_WRITE)
		 STREAM_MATCH_SID_VALUE(0x189)
		 STREAM_MATCH_SID_MASK(0x1FF)>,
		<52 STREAM_CFG(PTLB_ID(0x12), STLB_ID(0x30), FETCH_SIZE(SIZE1), PTLB_DIS, STLB_EN)
		 STREAM_MATCH_CFG(DIR_WRITE)
		 STREAM_MATCH_SID_VALUE(0x29)
		 STREAM_MATCH_SID_MASK(0x1FF)>,
		<53 STREAM_CFG(PTLB_ID(0x12), STLB_ID(0x31), FETCH_SIZE(SIZE1), PTLB_DIS, STLB_EN)
		 STREAM_MATCH_CFG(DIR_WRITE)
		 STREAM_MATCH_SID_VALUE(0xA9)
		 STREAM_MATCH_SID_MASK(0x1FF)>,
		<54 STREAM_CFG(PTLB_ID(0x12), STLB_ID(0x32), FETCH_SIZE(SIZE1), PTLB_DIS, STLB_EN)
		 STREAM_MATCH_CFG(DIR_WRITE)
		 STREAM_MATCH_SID_VALUE(0x129)
		 STREAM_MATCH_SID_MASK(0x1FF)>,
		<55 STREAM_CFG(PTLB_ID(0x12), STLB_ID(0x33), FETCH_SIZE(SIZE1), PTLB_DIS, STLB_EN)
		 STREAM_MATCH_CFG(DIR_WRITE)
		 STREAM_MATCH_SID_VALUE(0x1A9)
		 STREAM_MATCH_SID_MASK(0x1FF)>,
		<56 STREAM_CFG(PTLB_ID(0x13), STLB_ID(0x34), FETCH_SIZE(SIZE1), PTLB_DIS, STLB_EN)
		 STREAM_MATCH_CFG(DIR_WRITE)
		 STREAM_MATCH_SID_VALUE(0xA)
		 STREAM_MATCH_SID_MASK(0x1FF)>,
		<57 STREAM_CFG(PTLB_ID(0x13), STLB_ID(0x35), FETCH_SIZE(SIZE1), PTLB_DIS, STLB_EN)
		 STREAM_MATCH_CFG(DIR_WRITE)
		 STREAM_MATCH_SID_VALUE(0x8A)
		 STREAM_MATCH_SID_MASK(0x1FF)>,
		<58 STREAM_CFG(PTLB_ID(0x13), STLB_ID(0x36), FETCH_SIZE(SIZE1), PTLB_DIS, STLB_EN)
		 STREAM_MATCH_CFG(DIR_WRITE)
		 STREAM_MATCH_SID_VALUE(0x10A)
		 STREAM_MATCH_SID_MASK(0x1FF)>,
		<59 STREAM_CFG(PTLB_ID(0x13), STLB_ID(0x37), FETCH_SIZE(SIZE1), PTLB_DIS, STLB_EN)
		 STREAM_MATCH_CFG(DIR_WRITE)
		 STREAM_MATCH_SID_VALUE(0x18A)
		 STREAM_MATCH_SID_MASK(0x1FF)>,
		<60 STREAM_CFG(PTLB_ID(0x14), STLB_ID(0x38), FETCH_SIZE(SIZE1), PTLB_DIS, STLB_EN)
		 STREAM_MATCH_CFG(DIR_WRITE)
		 STREAM_MATCH_SID_VALUE(0x2A)
		 STREAM_MATCH_SID_MASK(0x1FF)>,
		<61 STREAM_CFG(PTLB_ID(0x14), STLB_ID(0x39), FETCH_SIZE(SIZE1), PTLB_DIS, STLB_EN)
		 STREAM_MATCH_CFG(DIR_WRITE)
		 STREAM_MATCH_SID_VALUE(0xAA)
		 STREAM_MATCH_SID_MASK(0x1FF)>,
		<62 STREAM_CFG(PTLB_ID(0x14), STLB_ID(0x3A), FETCH_SIZE(SIZE1), PTLB_DIS, STLB_EN)
		 STREAM_MATCH_CFG(DIR_WRITE)
		 STREAM_MATCH_SID_VALUE(0x12A)
		 STREAM_MATCH_SID_MASK(0x1FF)>,
		<63 STREAM_CFG(PTLB_ID(0x14), STLB_ID(0x3B), FETCH_SIZE(SIZE1), PTLB_DIS, STLB_EN)
		 STREAM_MATCH_CFG(DIR_WRITE)
		 STREAM_MATCH_SID_VALUE(0x1AA)
		 STREAM_MATCH_SID_MASK(0x1FF)>,
		<64 STREAM_CFG(PTLB_ID(0x1A), STLB_ID(0x41), FETCH_SIZE(SIZE1), PTLB_DIS, STLB_DIS)
		 STREAM_MATCH_CFG(DIR_WRITE)
		 STREAM_MATCH_SID_VALUE(0xB)
		 STREAM_MATCH_SID_MASK(0x1FF)>,
		<65 STREAM_CFG(PTLB_ID(0x1B), STLB_ID(0x42), FETCH_SIZE(SIZE1), PTLB_DIS, STLB_DIS)
		 STREAM_MATCH_CFG(DIR_WRITE)
		 STREAM_MATCH_SID_VALUE(0xC)
		 STREAM_MATCH_SID_MASK(0x1FF)>,
		<66 STREAM_CFG(PTLB_ID(0x1C), STLB_ID(0x43), FETCH_SIZE(SIZE1), PTLB_DIS, STLB_DIS)
		 STREAM_MATCH_CFG(DIR_WRITE)
		 STREAM_MATCH_SID_VALUE(0xD)
		 STREAM_MATCH_SID_MASK(0x1FF)>;
	};

	sysmmu_sdma_s0_stream: sysmmu_sdma_s0_stream {
		pmmu0,default_stream =
		<STREAM_CFG(PTLB_ID(0x0), STLB_ID(0x0), FETCH_SIZE(SIZE8), PTLB_EN, STLB_EN)>;
		pmmu0,stream_property =
		<1 STREAM_CFG(PTLB_ID(0x1), STLB_ID(0x1), FETCH_SIZE(SIZE1), PTLB_DIS, STLB_DIS)
		 STREAM_MATCH_CFG(DIR_RW)
		 STREAM_MATCH_SID_VALUE(0x40)
		 STREAM_MATCH_SID_MASK(0x40)>;
		pmmu1,default_stream =
		<STREAM_CFG(PTLB_ID(0x0), STLB_ID(0x0), FETCH_SIZE(SIZE8), PTLB_EN, STLB_EN)>;
		pmmu1,stream_property =
		<1 STREAM_CFG(PTLB_ID(0x1), STLB_ID(0x1), FETCH_SIZE(SIZE1), PTLB_DIS, STLB_DIS)
		 STREAM_MATCH_CFG(DIR_RW)
		 STREAM_MATCH_SID_VALUE(0x40)
		 STREAM_MATCH_SID_MASK(0x40)>;
		pmmu2,default_stream =
		<STREAM_CFG(PTLB_ID(0x0), STLB_ID(0x0), FETCH_SIZE(SIZE8), PTLB_EN, STLB_EN)>;
		pmmu2,stream_property =
		<1 STREAM_CFG(PTLB_ID(0x1), STLB_ID(0x1), FETCH_SIZE(SIZE1), PTLB_DIS, STLB_DIS)
		 STREAM_MATCH_CFG(DIR_RW)
		 STREAM_MATCH_SID_VALUE(0x40)
		 STREAM_MATCH_SID_MASK(0x40)>;
		pmmu3,default_stream =
		<STREAM_CFG(PTLB_ID(0x0), STLB_ID(0x0), FETCH_SIZE(SIZE8), PTLB_EN, STLB_EN)>;
		pmmu3,stream_property =
		<1 STREAM_CFG(PTLB_ID(0x1), STLB_ID(0x1), FETCH_SIZE(SIZE1), PTLB_DIS, STLB_DIS)
		 STREAM_MATCH_CFG(DIR_RW)
		 STREAM_MATCH_SID_VALUE(0x40)
		 STREAM_MATCH_SID_MASK(0x40)>;
	};

	sysmmu_sdma_s1_stream: sysmmu_sdma_s1_stream {
		pmmu0,default_stream =
		<STREAM_CFG(PTLB_ID(0x0), STLB_ID(0x0), FETCH_SIZE(SIZE1), PTLB_DIS, STLB_DIS)>;
		pmmu0,stream_property =
		<1 STREAM_CFG(PTLB_ID(0x4), STLB_ID(0x4), FETCH_SIZE(SIZE1), PTLB_DIS, STLB_DIS)
		 STREAM_MATCH_CFG(DIR_READ)
		 STREAM_MATCH_SID_VALUE(0x1)
		 STREAM_MATCH_SID_MASK(0xF)>,
		<2 STREAM_CFG(PTLB_ID(0x1), STLB_ID(0x1), FETCH_SIZE(SIZE1), PTLB_DIS, STLB_EN)
		 STREAM_MATCH_CFG(DIR_READ)
		 STREAM_MATCH_SID_VALUE(0x9)
		 STREAM_MATCH_SID_MASK(0xF)>,
		<3 STREAM_CFG(PTLB_ID(0x2), STLB_ID(0x2), FETCH_SIZE(SIZE1), PTLB_EN, STLB_EN)
		 STREAM_MATCH_CFG(DIR_READ)
		 STREAM_MATCH_SID_VALUE(0x2)
		 STREAM_MATCH_SID_MASK(0xF)>,
		<4 STREAM_CFG(PTLB_ID(0x3), STLB_ID(0x3), FETCH_SIZE(SIZE1), PTLB_EN, STLB_EN)
		 STREAM_MATCH_CFG(DIR_READ)
		 STREAM_MATCH_SID_VALUE(0x3)
		 STREAM_MATCH_SID_MASK(0xF)>,
		<5 STREAM_CFG(PTLB_ID(0x5), STLB_ID(0x5), FETCH_SIZE(SIZE1), PTLB_DIS, STLB_DIS)
		 STREAM_MATCH_CFG(DIR_WRITE)
		 STREAM_MATCH_SID_VALUE(0x4)
		 STREAM_MATCH_SID_MASK(0xF)>;
	};

	sysmmu_dpuf_s0_stream: sysmmu_dpuf_s0_stream {
		pmmu0,default_stream =
		<STREAM_CFG(PTLB_ID(0x0), STLB_ID(0x4), FETCH_SIZE(SIZE16), PTLB_EN, STLB_EN)>;
		pmmu0,stream_property =
		<1 STREAM_CFG(PTLB_ID(0x0), STLB_ID(0x0), FETCH_SIZE(SIZE64), PTLB_DIS, STLB_DIS)
		 STREAM_MATCH_CFG(DIR_READ)
		 STREAM_MATCH_SID_VALUE(0x82)
		 STREAM_MATCH_SID_MASK(0x3FF)>,
		<2 STREAM_CFG(PTLB_ID(0x0), STLB_ID(0x5), FETCH_SIZE(SIZE16), PTLB_EN, STLB_EN)
		 STREAM_MATCH_CFG(DIR_READ)
		 STREAM_MATCH_SID_VALUE(0x102)
		 STREAM_MATCH_SID_MASK(0x3FF)>,
		<3 STREAM_CFG(PTLB_ID(0x0), STLB_ID(0x6), FETCH_SIZE(SIZE16), PTLB_EN, STLB_EN)
		 STREAM_MATCH_CFG(DIR_READ)
		 STREAM_MATCH_SID_VALUE(0x202)
		 STREAM_MATCH_SID_MASK(0x3FF)>,
		<4 STREAM_CFG(PTLB_ID(0x0), STLB_ID(0x7), FETCH_SIZE(SIZE16), PTLB_EN, STLB_EN)
		 STREAM_MATCH_CFG(DIR_READ)
		 STREAM_MATCH_SID_VALUE(0x302)
		 STREAM_MATCH_SID_MASK(0x3FF)>,
		<5 STREAM_CFG(PTLB_ID(0x0), STLB_ID(0xC), FETCH_SIZE(SIZE2), PTLB_EN, STLB_EN)
		 STREAM_MATCH_CFG(DIR_READ)
		 STREAM_MATCH_SID_VALUE(0x182)
		 STREAM_MATCH_SID_MASK(0x3FF)>,
		<6 STREAM_CFG(PTLB_ID(0x0), STLB_ID(0xD), FETCH_SIZE(SIZE2), PTLB_EN, STLB_EN)
		 STREAM_MATCH_CFG(DIR_READ)
		 STREAM_MATCH_SID_VALUE(0x282)
		 STREAM_MATCH_SID_MASK(0x3FF)>,
		<7 STREAM_CFG(PTLB_ID(0x0), STLB_ID(0xE), FETCH_SIZE(SIZE2), PTLB_EN, STLB_EN)
		 STREAM_MATCH_CFG(DIR_READ)
		 STREAM_MATCH_SID_VALUE(0x382)
		 STREAM_MATCH_SID_MASK(0x3FF)>,
		<8 STREAM_CFG(PTLB_ID(0x1), STLB_ID(0xF), FETCH_SIZE(SIZE2), PTLB_EN, STLB_EN)
		 STREAM_MATCH_CFG(DIR_READ)
		 STREAM_MATCH_SID_VALUE(0x40)
		 STREAM_MATCH_SID_MASK(0x3FF)>,
		<9 STREAM_CFG(PTLB_ID(0x1), STLB_ID(0x10), FETCH_SIZE(SIZE2), PTLB_EN, STLB_EN)
		 STREAM_MATCH_CFG(DIR_READ)
		 STREAM_MATCH_SID_VALUE(0x140)
		 STREAM_MATCH_SID_MASK(0x3FF)>,
		<10 STREAM_CFG(PTLB_ID(0x1), STLB_ID(0x11), FETCH_SIZE(SIZE2), PTLB_EN, STLB_EN)
		 STREAM_MATCH_CFG(DIR_READ)
		 STREAM_MATCH_SID_VALUE(0x240)
		 STREAM_MATCH_SID_MASK(0x3FF)>,
		<11 STREAM_CFG(PTLB_ID(0x1), STLB_ID(0x12), FETCH_SIZE(SIZE2), PTLB_EN, STLB_EN)
		 STREAM_MATCH_CFG(DIR_READ)
		 STREAM_MATCH_SID_VALUE(0x340)
		 STREAM_MATCH_SID_MASK(0x3FF)>,
		<12 STREAM_CFG(PTLB_ID(0x2), STLB_ID(0x4), FETCH_SIZE(SIZE16), PTLB_EN, STLB_EN)
		 STREAM_MATCH_CFG(DIR_READ)
		 STREAM_MATCH_SID_VALUE(0x6)
		 STREAM_MATCH_SID_MASK(0x3FF)>,
		<13 STREAM_CFG(PTLB_ID(0x2), STLB_ID(0x0), FETCH_SIZE(SIZE64), PTLB_DIS, STLB_DIS)
		 STREAM_MATCH_CFG(DIR_READ)
		 STREAM_MATCH_SID_VALUE(0x86)
		 STREAM_MATCH_SID_MASK(0x3FF)>,
		<14 STREAM_CFG(PTLB_ID(0x2), STLB_ID(0x5), FETCH_SIZE(SIZE16), PTLB_EN, STLB_EN)
		 STREAM_MATCH_CFG(DIR_READ)
		 STREAM_MATCH_SID_VALUE(0x106)
		 STREAM_MATCH_SID_MASK(0x3FF)>,
		<15 STREAM_CFG(PTLB_ID(0x2), STLB_ID(0x6), FETCH_SIZE(SIZE16), PTLB_EN, STLB_EN)
		 STREAM_MATCH_CFG(DIR_READ)
		 STREAM_MATCH_SID_VALUE(0x206)
		 STREAM_MATCH_SID_MASK(0x3FF)>,
		<16 STREAM_CFG(PTLB_ID(0x2), STLB_ID(0x7), FETCH_SIZE(SIZE16), PTLB_EN, STLB_EN)
		 STREAM_MATCH_CFG(DIR_READ)
		 STREAM_MATCH_SID_VALUE(0x306)
		 STREAM_MATCH_SID_MASK(0x3FF)>,
		<17 STREAM_CFG(PTLB_ID(0x2), STLB_ID(0xC), FETCH_SIZE(SIZE2), PTLB_EN, STLB_EN)
		 STREAM_MATCH_CFG(DIR_READ)
		 STREAM_MATCH_SID_VALUE(0x186)
		 STREAM_MATCH_SID_MASK(0x3FF)>,
		<18 STREAM_CFG(PTLB_ID(0x2), STLB_ID(0xD), FETCH_SIZE(SIZE2), PTLB_EN, STLB_EN)
		 STREAM_MATCH_CFG(DIR_READ)
		 STREAM_MATCH_SID_VALUE(0x286)
		 STREAM_MATCH_SID_MASK(0x3FF)>,
		<19 STREAM_CFG(PTLB_ID(0x2), STLB_ID(0xE), FETCH_SIZE(SIZE2), PTLB_EN, STLB_EN)
		 STREAM_MATCH_CFG(DIR_READ)
		 STREAM_MATCH_SID_VALUE(0x386)
		 STREAM_MATCH_SID_MASK(0x3FF)>,
		<20 STREAM_CFG(PTLB_ID(0x3), STLB_ID(0x1), FETCH_SIZE(SIZE64), PTLB_DIS, STLB_DIS)
		 STREAM_MATCH_CFG(DIR_READ)
		 STREAM_MATCH_SID_VALUE(0xA7)
		 STREAM_MATCH_SID_MASK(0x3FF)>,
		<21 STREAM_CFG(PTLB_ID(0x3), STLB_ID(0x13), FETCH_SIZE(SIZE2), PTLB_EN, STLB_EN)
		 STREAM_MATCH_CFG(DIR_READ)
		 STREAM_MATCH_SID_VALUE(0x1A7)
		 STREAM_MATCH_SID_MASK(0x3FF)>,
		<22 STREAM_CFG(PTLB_ID(0x3), STLB_ID(0x14), FETCH_SIZE(SIZE2), PTLB_EN, STLB_EN)
		 STREAM_MATCH_CFG(DIR_READ)
		 STREAM_MATCH_SID_VALUE(0x2A7)
		 STREAM_MATCH_SID_MASK(0x3FF)>,
		<23 STREAM_CFG(PTLB_ID(0x3), STLB_ID(0x15), FETCH_SIZE(SIZE2), PTLB_EN, STLB_EN)
		 STREAM_MATCH_CFG(DIR_READ)
		 STREAM_MATCH_SID_VALUE(0x3A7)
		 STREAM_MATCH_SID_MASK(0x3FF)>,
		<24 STREAM_CFG(PTLB_ID(0x4), STLB_ID(0xF), FETCH_SIZE(SIZE2), PTLB_EN, STLB_EN)
		 STREAM_MATCH_CFG(DIR_READ)
		 STREAM_MATCH_SID_VALUE(0x44)
		 STREAM_MATCH_SID_MASK(0x3FF)>,
		<25 STREAM_CFG(PTLB_ID(0x4), STLB_ID(0x10), FETCH_SIZE(SIZE2), PTLB_EN, STLB_EN)
		 STREAM_MATCH_CFG(DIR_READ)
		 STREAM_MATCH_SID_VALUE(0x144)
		 STREAM_MATCH_SID_MASK(0x3FF)>,
		<26 STREAM_CFG(PTLB_ID(0x4), STLB_ID(0x11), FETCH_SIZE(SIZE2), PTLB_EN, STLB_EN)
		 STREAM_MATCH_CFG(DIR_READ)
		 STREAM_MATCH_SID_VALUE(0x244)
		 STREAM_MATCH_SID_MASK(0x3FF)>,
		<27 STREAM_CFG(PTLB_ID(0x4), STLB_ID(0x12), FETCH_SIZE(SIZE2), PTLB_EN, STLB_EN)
		 STREAM_MATCH_CFG(DIR_READ)
		 STREAM_MATCH_SID_VALUE(0x344)
		 STREAM_MATCH_SID_MASK(0x3FF)>,
		<28 STREAM_CFG(PTLB_ID(0x4), STLB_ID(0x16), FETCH_SIZE(SIZE2), PTLB_EN, STLB_EN)
		 STREAM_MATCH_CFG(DIR_READ)
		 STREAM_MATCH_SID_VALUE(0xC4)
		 STREAM_MATCH_SID_MASK(0x3FF)>,
		<29 STREAM_CFG(PTLB_ID(0x4), STLB_ID(0x17), FETCH_SIZE(SIZE2), PTLB_EN, STLB_EN)
		 STREAM_MATCH_CFG(DIR_READ)
		 STREAM_MATCH_SID_VALUE(0x1C4)
		 STREAM_MATCH_SID_MASK(0x3FF)>,
		<30 STREAM_CFG(PTLB_ID(0x4), STLB_ID(0x2A), FETCH_SIZE(SIZE1), PTLB_EN, STLB_EN)
		 STREAM_MATCH_CFG(DIR_READ)
		 STREAM_MATCH_SID_VALUE(0x2C4)
		 STREAM_MATCH_SID_MASK(0x3FF)>,
		<31 STREAM_CFG(PTLB_ID(0x5), STLB_ID(0x18), FETCH_SIZE(SIZE2), PTLB_EN, STLB_EN)
		 STREAM_MATCH_CFG(DIR_READ)
		 STREAM_MATCH_SID_VALUE(0xE5)
		 STREAM_MATCH_SID_MASK(0x3FF)>,
		<32 STREAM_CFG(PTLB_ID(0x5), STLB_ID(0x2B), FETCH_SIZE(SIZE1), PTLB_EN, STLB_EN)
		 STREAM_MATCH_CFG(DIR_READ)
		 STREAM_MATCH_SID_VALUE(0x1E5)
		 STREAM_MATCH_SID_MASK(0x3FF)>,
		<33 STREAM_CFG(PTLB_ID(0x5), STLB_ID(0x2C), FETCH_SIZE(SIZE1), PTLB_EN, STLB_EN)
		 STREAM_MATCH_CFG(DIR_READ)
		 STREAM_MATCH_SID_VALUE(0x2E5)
		 STREAM_MATCH_SID_MASK(0x3FF)>,
		<34 STREAM_CFG(PTLB_ID(0x6), STLB_ID(0x4), FETCH_SIZE(SIZE16), PTLB_EN, STLB_EN)
		 STREAM_MATCH_CFG(DIR_READ)
		 STREAM_MATCH_SID_VALUE(0xA)
		 STREAM_MATCH_SID_MASK(0x3FF)>,
		<35 STREAM_CFG(PTLB_ID(0x6), STLB_ID(0x0), FETCH_SIZE(SIZE64), PTLB_DIS, STLB_DIS)
		 STREAM_MATCH_CFG(DIR_READ)
		 STREAM_MATCH_SID_VALUE(0x8A)
		 STREAM_MATCH_SID_MASK(0x3FF)>,
		<36 STREAM_CFG(PTLB_ID(0x6), STLB_ID(0x5), FETCH_SIZE(SIZE16), PTLB_EN, STLB_EN)
		 STREAM_MATCH_CFG(DIR_READ)
		 STREAM_MATCH_SID_VALUE(0x10A)
		 STREAM_MATCH_SID_MASK(0x3FF)>,
		<37 STREAM_CFG(PTLB_ID(0x6), STLB_ID(0x6), FETCH_SIZE(SIZE16), PTLB_EN, STLB_EN)
		 STREAM_MATCH_CFG(DIR_READ)
		 STREAM_MATCH_SID_VALUE(0x20A)
		 STREAM_MATCH_SID_MASK(0x3FF)>,
		<38 STREAM_CFG(PTLB_ID(0x6), STLB_ID(0x7), FETCH_SIZE(SIZE16), PTLB_EN, STLB_EN)
		 STREAM_MATCH_CFG(DIR_READ)
		 STREAM_MATCH_SID_VALUE(0x30A)
		 STREAM_MATCH_SID_MASK(0x3FF)>,
		<39 STREAM_CFG(PTLB_ID(0x6), STLB_ID(0xC), FETCH_SIZE(SIZE2), PTLB_EN, STLB_EN)
		 STREAM_MATCH_CFG(DIR_READ)
		 STREAM_MATCH_SID_VALUE(0x18A)
		 STREAM_MATCH_SID_MASK(0x3FF)>,
		<40 STREAM_CFG(PTLB_ID(0x6), STLB_ID(0xD), FETCH_SIZE(SIZE2), PTLB_EN, STLB_EN)
		 STREAM_MATCH_CFG(DIR_READ)
		 STREAM_MATCH_SID_VALUE(0x28A)
		 STREAM_MATCH_SID_MASK(0x3FF)>,
		<41 STREAM_CFG(PTLB_ID(0x6), STLB_ID(0xE), FETCH_SIZE(SIZE2), PTLB_EN, STLB_EN)
		 STREAM_MATCH_CFG(DIR_READ)
		 STREAM_MATCH_SID_VALUE(0x38A)
		 STREAM_MATCH_SID_MASK(0x3FF)>,
		<42 STREAM_CFG(PTLB_ID(0x7), STLB_ID(0xF), FETCH_SIZE(SIZE2), PTLB_EN, STLB_EN)
		 STREAM_MATCH_CFG(DIR_READ)
		 STREAM_MATCH_SID_VALUE(0x48)
		 STREAM_MATCH_SID_MASK(0x3FF)>,
		<43 STREAM_CFG(PTLB_ID(0x7), STLB_ID(0x10), FETCH_SIZE(SIZE2), PTLB_EN, STLB_EN)
		 STREAM_MATCH_CFG(DIR_READ)
		 STREAM_MATCH_SID_VALUE(0x148)
		 STREAM_MATCH_SID_MASK(0x3FF)>,
		<44 STREAM_CFG(PTLB_ID(0x7), STLB_ID(0x11), FETCH_SIZE(SIZE2), PTLB_EN, STLB_EN)
		 STREAM_MATCH_CFG(DIR_READ)
		 STREAM_MATCH_SID_VALUE(0x248)
		 STREAM_MATCH_SID_MASK(0x3FF)>,
		<45 STREAM_CFG(PTLB_ID(0x7), STLB_ID(0x12), FETCH_SIZE(SIZE2), PTLB_EN, STLB_EN)
		 STREAM_MATCH_CFG(DIR_READ)
		 STREAM_MATCH_SID_VALUE(0x348)
		 STREAM_MATCH_SID_MASK(0x3FF)>,
		<46 STREAM_CFG(PTLB_ID(0x8), STLB_ID(0x4), FETCH_SIZE(SIZE16), PTLB_EN, STLB_EN)
		 STREAM_MATCH_CFG(DIR_READ)
		 STREAM_MATCH_SID_VALUE(0xE)
		 STREAM_MATCH_SID_MASK(0x3FF)>,
		<47 STREAM_CFG(PTLB_ID(0x8), STLB_ID(0x0), FETCH_SIZE(SIZE64), PTLB_DIS, STLB_DIS)
		 STREAM_MATCH_CFG(DIR_READ)
		 STREAM_MATCH_SID_VALUE(0x8E)
		 STREAM_MATCH_SID_MASK(0x3FF)>,
		<48 STREAM_CFG(PTLB_ID(0x8), STLB_ID(0x5), FETCH_SIZE(SIZE16), PTLB_EN, STLB_EN)
		 STREAM_MATCH_CFG(DIR_READ)
		 STREAM_MATCH_SID_VALUE(0x10E)
		 STREAM_MATCH_SID_MASK(0x3FF)>,
		<49 STREAM_CFG(PTLB_ID(0x8), STLB_ID(0x6), FETCH_SIZE(SIZE16), PTLB_EN, STLB_EN)
		 STREAM_MATCH_CFG(DIR_READ)
		 STREAM_MATCH_SID_VALUE(0x20E)
		 STREAM_MATCH_SID_MASK(0x3FF)>,
		<50 STREAM_CFG(PTLB_ID(0x8), STLB_ID(0x7), FETCH_SIZE(SIZE16), PTLB_EN, STLB_EN)
		 STREAM_MATCH_CFG(DIR_READ)
		 STREAM_MATCH_SID_VALUE(0x30E)
		 STREAM_MATCH_SID_MASK(0x3FF)>,
		<51 STREAM_CFG(PTLB_ID(0x8), STLB_ID(0xC), FETCH_SIZE(SIZE2), PTLB_EN, STLB_EN)
		 STREAM_MATCH_CFG(DIR_READ)
		 STREAM_MATCH_SID_VALUE(0x18E)
		 STREAM_MATCH_SID_MASK(0x3FF)>,
		<52 STREAM_CFG(PTLB_ID(0x8), STLB_ID(0xD), FETCH_SIZE(SIZE2), PTLB_EN, STLB_EN)
		 STREAM_MATCH_CFG(DIR_READ)
		 STREAM_MATCH_SID_VALUE(0x28E)
		 STREAM_MATCH_SID_MASK(0x3FF)>,
		<53 STREAM_CFG(PTLB_ID(0x8), STLB_ID(0xE), FETCH_SIZE(SIZE2), PTLB_EN, STLB_EN)
		 STREAM_MATCH_CFG(DIR_READ)
		 STREAM_MATCH_SID_VALUE(0x38E)
		 STREAM_MATCH_SID_MASK(0x3FF)>,
		<54 STREAM_CFG(PTLB_ID(0x9), STLB_ID(0x1), FETCH_SIZE(SIZE64), PTLB_DIS, STLB_DIS)
		 STREAM_MATCH_CFG(DIR_READ)
		 STREAM_MATCH_SID_VALUE(0xAF)
		 STREAM_MATCH_SID_MASK(0x3FF)>,
		<55 STREAM_CFG(PTLB_ID(0x9), STLB_ID(0x13), FETCH_SIZE(SIZE2), PTLB_EN, STLB_EN)
		 STREAM_MATCH_CFG(DIR_READ)
		 STREAM_MATCH_SID_VALUE(0x1AF)
		 STREAM_MATCH_SID_MASK(0x3FF)>,
		<56 STREAM_CFG(PTLB_ID(0x9), STLB_ID(0x14), FETCH_SIZE(SIZE2), PTLB_EN, STLB_EN)
		 STREAM_MATCH_CFG(DIR_READ)
		 STREAM_MATCH_SID_VALUE(0x2AF)
		 STREAM_MATCH_SID_MASK(0x3FF)>,
		<57 STREAM_CFG(PTLB_ID(0x9), STLB_ID(0x15), FETCH_SIZE(SIZE2), PTLB_EN, STLB_EN)
		 STREAM_MATCH_CFG(DIR_READ)
		 STREAM_MATCH_SID_VALUE(0x3AF)
		 STREAM_MATCH_SID_MASK(0x3FF)>,
		<58 STREAM_CFG(PTLB_ID(0xA), STLB_ID(0xF), FETCH_SIZE(SIZE2), PTLB_EN, STLB_EN)
		 STREAM_MATCH_CFG(DIR_READ)
		 STREAM_MATCH_SID_VALUE(0x4C)
		 STREAM_MATCH_SID_MASK(0x3FF)>,
		<59 STREAM_CFG(PTLB_ID(0xA), STLB_ID(0x10), FETCH_SIZE(SIZE2), PTLB_EN, STLB_EN)
		 STREAM_MATCH_CFG(DIR_READ)
		 STREAM_MATCH_SID_VALUE(0x14C)
		 STREAM_MATCH_SID_MASK(0x3FF)>,
		<60 STREAM_CFG(PTLB_ID(0xA), STLB_ID(0x11), FETCH_SIZE(SIZE2), PTLB_EN, STLB_EN)
		 STREAM_MATCH_CFG(DIR_READ)
		 STREAM_MATCH_SID_VALUE(0x24C)
		 STREAM_MATCH_SID_MASK(0x3FF)>,
		<61 STREAM_CFG(PTLB_ID(0xA), STLB_ID(0x12), FETCH_SIZE(SIZE2), PTLB_EN, STLB_EN)
		 STREAM_MATCH_CFG(DIR_READ)
		 STREAM_MATCH_SID_VALUE(0x34C)
		 STREAM_MATCH_SID_MASK(0x3FF)>,
		<62 STREAM_CFG(PTLB_ID(0xA), STLB_ID(0x16), FETCH_SIZE(SIZE2), PTLB_EN, STLB_EN)
		 STREAM_MATCH_CFG(DIR_READ)
		 STREAM_MATCH_SID_VALUE(0xCC)
		 STREAM_MATCH_SID_MASK(0x3FF)>,
		<63 STREAM_CFG(PTLB_ID(0xA), STLB_ID(0x17), FETCH_SIZE(SIZE2), PTLB_EN, STLB_EN)
		 STREAM_MATCH_CFG(DIR_READ)
		 STREAM_MATCH_SID_VALUE(0x1CC)
		 STREAM_MATCH_SID_MASK(0x3FF)>,
		<64 STREAM_CFG(PTLB_ID(0xA), STLB_ID(0x2A), FETCH_SIZE(SIZE1), PTLB_EN, STLB_EN)
		 STREAM_MATCH_CFG(DIR_READ)
		 STREAM_MATCH_SID_VALUE(0x2CC)
		 STREAM_MATCH_SID_MASK(0x3FF)>,
		<65 STREAM_CFG(PTLB_ID(0xB), STLB_ID(0x18), FETCH_SIZE(SIZE2), PTLB_EN, STLB_EN)
		 STREAM_MATCH_CFG(DIR_READ)
		 STREAM_MATCH_SID_VALUE(0xED)
		 STREAM_MATCH_SID_MASK(0x3FF)>,
		<66 STREAM_CFG(PTLB_ID(0xB), STLB_ID(0x2B), FETCH_SIZE(SIZE1), PTLB_EN, STLB_EN)
		 STREAM_MATCH_CFG(DIR_READ)
		 STREAM_MATCH_SID_VALUE(0x1ED)
		 STREAM_MATCH_SID_MASK(0x3FF)>,
		<67 STREAM_CFG(PTLB_ID(0xB), STLB_ID(0x2C), FETCH_SIZE(SIZE1), PTLB_EN, STLB_EN)
		 STREAM_MATCH_CFG(DIR_READ)
		 STREAM_MATCH_SID_VALUE(0x2ED)
		 STREAM_MATCH_SID_MASK(0x3FF)>,
		<68 STREAM_CFG(PTLB_ID(0xC), STLB_ID(0x2D), FETCH_SIZE(SIZE1), PTLB_EN, STLB_EN)
		 STREAM_MATCH_CFG(DIR_READ)
		 STREAM_MATCH_SID_VALUE(0x10)
		 STREAM_MATCH_SID_MASK(0x3FF)>,
		<69 STREAM_CFG(PTLB_ID(0xD), STLB_ID(0x2E), FETCH_SIZE(SIZE1), PTLB_EN, STLB_EN)
		 STREAM_MATCH_CFG(DIR_READ)
		 STREAM_MATCH_SID_VALUE(0x14)
		 STREAM_MATCH_SID_MASK(0x3FF)>,
		<70 STREAM_CFG(PTLB_ID(0xE), STLB_ID(0x2F), FETCH_SIZE(SIZE1), PTLB_DIS, STLB_EN)
		 STREAM_MATCH_CFG(DIR_WRITE)
		 STREAM_MATCH_SID_VALUE(0x0)
		 STREAM_MATCH_SID_MASK(0x3FF)>,
		<71 STREAM_CFG(PTLB_ID(0xF), STLB_ID(0x30), FETCH_SIZE(SIZE1), PTLB_DIS, STLB_EN)
		 STREAM_MATCH_CFG(DIR_WRITE)
		 STREAM_MATCH_SID_VALUE(0x1)
		 STREAM_MATCH_SID_MASK(0x3FF)>;
		pmmu1,default_stream =
		<STREAM_CFG(PTLB_ID(0x0), STLB_ID(0x4), FETCH_SIZE(SIZE16), PTLB_EN, STLB_EN)>;
		pmmu1,stream_property =
		<1 STREAM_CFG(PTLB_ID(0x0), STLB_ID(0x0), FETCH_SIZE(SIZE64), PTLB_DIS, STLB_DIS)
		 STREAM_MATCH_CFG(DIR_READ)
		 STREAM_MATCH_SID_VALUE(0x82)
		 STREAM_MATCH_SID_MASK(0x3FF)>,
		<2 STREAM_CFG(PTLB_ID(0x0), STLB_ID(0x5), FETCH_SIZE(SIZE16), PTLB_EN, STLB_EN)
		 STREAM_MATCH_CFG(DIR_READ)
		 STREAM_MATCH_SID_VALUE(0x102)
		 STREAM_MATCH_SID_MASK(0x3FF)>,
		<3 STREAM_CFG(PTLB_ID(0x0), STLB_ID(0x6), FETCH_SIZE(SIZE16), PTLB_EN, STLB_EN)
		 STREAM_MATCH_CFG(DIR_READ)
		 STREAM_MATCH_SID_VALUE(0x202)
		 STREAM_MATCH_SID_MASK(0x3FF)>,
		<4 STREAM_CFG(PTLB_ID(0x0), STLB_ID(0x7), FETCH_SIZE(SIZE16), PTLB_EN, STLB_EN)
		 STREAM_MATCH_CFG(DIR_READ)
		 STREAM_MATCH_SID_VALUE(0x302)
		 STREAM_MATCH_SID_MASK(0x3FF)>,
		<5 STREAM_CFG(PTLB_ID(0x0), STLB_ID(0xC), FETCH_SIZE(SIZE2), PTLB_EN, STLB_EN)
		 STREAM_MATCH_CFG(DIR_READ)
		 STREAM_MATCH_SID_VALUE(0x182)
		 STREAM_MATCH_SID_MASK(0x3FF)>,
		<6 STREAM_CFG(PTLB_ID(0x0), STLB_ID(0xD), FETCH_SIZE(SIZE2), PTLB_EN, STLB_EN)
		 STREAM_MATCH_CFG(DIR_READ)
		 STREAM_MATCH_SID_VALUE(0x282)
		 STREAM_MATCH_SID_MASK(0x3FF)>,
		<7 STREAM_CFG(PTLB_ID(0x0), STLB_ID(0xE), FETCH_SIZE(SIZE2), PTLB_EN, STLB_EN)
		 STREAM_MATCH_CFG(DIR_READ)
		 STREAM_MATCH_SID_VALUE(0x382)
		 STREAM_MATCH_SID_MASK(0x3FF)>,
		<8 STREAM_CFG(PTLB_ID(0x1), STLB_ID(0xF), FETCH_SIZE(SIZE2), PTLB_EN, STLB_EN)
		 STREAM_MATCH_CFG(DIR_READ)
		 STREAM_MATCH_SID_VALUE(0x40)
		 STREAM_MATCH_SID_MASK(0x3FF)>,
		<9 STREAM_CFG(PTLB_ID(0x1), STLB_ID(0x10), FETCH_SIZE(SIZE2), PTLB_EN, STLB_EN)
		 STREAM_MATCH_CFG(DIR_READ)
		 STREAM_MATCH_SID_VALUE(0x140)
		 STREAM_MATCH_SID_MASK(0x3FF)>,
		<10 STREAM_CFG(PTLB_ID(0x1), STLB_ID(0x11), FETCH_SIZE(SIZE2), PTLB_EN, STLB_EN)
		 STREAM_MATCH_CFG(DIR_READ)
		 STREAM_MATCH_SID_VALUE(0x240)
		 STREAM_MATCH_SID_MASK(0x3FF)>,
		<11 STREAM_CFG(PTLB_ID(0x1), STLB_ID(0x12), FETCH_SIZE(SIZE2), PTLB_EN, STLB_EN)
		 STREAM_MATCH_CFG(DIR_READ)
		 STREAM_MATCH_SID_VALUE(0x340)
		 STREAM_MATCH_SID_MASK(0x3FF)>,
		<12 STREAM_CFG(PTLB_ID(0x2), STLB_ID(0x4), FETCH_SIZE(SIZE16), PTLB_EN, STLB_EN)
		 STREAM_MATCH_CFG(DIR_READ)
		 STREAM_MATCH_SID_VALUE(0x6)
		 STREAM_MATCH_SID_MASK(0x3FF)>,
		<13 STREAM_CFG(PTLB_ID(0x2), STLB_ID(0x0), FETCH_SIZE(SIZE64), PTLB_DIS, STLB_DIS)
		 STREAM_MATCH_CFG(DIR_READ)
		 STREAM_MATCH_SID_VALUE(0x86)
		 STREAM_MATCH_SID_MASK(0x3FF)>,
		<14 STREAM_CFG(PTLB_ID(0x2), STLB_ID(0x5), FETCH_SIZE(SIZE16), PTLB_EN, STLB_EN)
		 STREAM_MATCH_CFG(DIR_READ)
		 STREAM_MATCH_SID_VALUE(0x106)
		 STREAM_MATCH_SID_MASK(0x3FF)>,
		<15 STREAM_CFG(PTLB_ID(0x2), STLB_ID(0x6), FETCH_SIZE(SIZE16), PTLB_EN, STLB_EN)
		 STREAM_MATCH_CFG(DIR_READ)
		 STREAM_MATCH_SID_VALUE(0x206)
		 STREAM_MATCH_SID_MASK(0x3FF)>,
		<16 STREAM_CFG(PTLB_ID(0x2), STLB_ID(0x7), FETCH_SIZE(SIZE16), PTLB_EN, STLB_EN)
		 STREAM_MATCH_CFG(DIR_READ)
		 STREAM_MATCH_SID_VALUE(0x306)
		 STREAM_MATCH_SID_MASK(0x3FF)>,
		<17 STREAM_CFG(PTLB_ID(0x2), STLB_ID(0xC), FETCH_SIZE(SIZE2), PTLB_EN, STLB_EN)
		 STREAM_MATCH_CFG(DIR_READ)
		 STREAM_MATCH_SID_VALUE(0x186)
		 STREAM_MATCH_SID_MASK(0x3FF)>,
		<18 STREAM_CFG(PTLB_ID(0x2), STLB_ID(0xD), FETCH_SIZE(SIZE2), PTLB_EN, STLB_EN)
		 STREAM_MATCH_CFG(DIR_READ)
		 STREAM_MATCH_SID_VALUE(0x286)
		 STREAM_MATCH_SID_MASK(0x3FF)>,
		<19 STREAM_CFG(PTLB_ID(0x2), STLB_ID(0xE), FETCH_SIZE(SIZE2), PTLB_EN, STLB_EN)
		 STREAM_MATCH_CFG(DIR_READ)
		 STREAM_MATCH_SID_VALUE(0x386)
		 STREAM_MATCH_SID_MASK(0x3FF)>,
		<20 STREAM_CFG(PTLB_ID(0x3), STLB_ID(0x1), FETCH_SIZE(SIZE64), PTLB_DIS, STLB_DIS)
		 STREAM_MATCH_CFG(DIR_READ)
		 STREAM_MATCH_SID_VALUE(0xA7)
		 STREAM_MATCH_SID_MASK(0x3FF)>,
		<21 STREAM_CFG(PTLB_ID(0x3), STLB_ID(0x13), FETCH_SIZE(SIZE2), PTLB_EN, STLB_EN)
		 STREAM_MATCH_CFG(DIR_READ)
		 STREAM_MATCH_SID_VALUE(0x1A7)
		 STREAM_MATCH_SID_MASK(0x3FF)>,
		<22 STREAM_CFG(PTLB_ID(0x3), STLB_ID(0x14), FETCH_SIZE(SIZE2), PTLB_EN, STLB_EN)
		 STREAM_MATCH_CFG(DIR_READ)
		 STREAM_MATCH_SID_VALUE(0x2A7)
		 STREAM_MATCH_SID_MASK(0x3FF)>,
		<23 STREAM_CFG(PTLB_ID(0x3), STLB_ID(0x15), FETCH_SIZE(SIZE2), PTLB_EN, STLB_EN)
		 STREAM_MATCH_CFG(DIR_READ)
		 STREAM_MATCH_SID_VALUE(0x3A7)
		 STREAM_MATCH_SID_MASK(0x3FF)>,
		<24 STREAM_CFG(PTLB_ID(0x4), STLB_ID(0xF), FETCH_SIZE(SIZE2), PTLB_EN, STLB_EN)
		 STREAM_MATCH_CFG(DIR_READ)
		 STREAM_MATCH_SID_VALUE(0x44)
		 STREAM_MATCH_SID_MASK(0x3FF)>,
		<25 STREAM_CFG(PTLB_ID(0x4), STLB_ID(0x10), FETCH_SIZE(SIZE2), PTLB_EN, STLB_EN)
		 STREAM_MATCH_CFG(DIR_READ)
		 STREAM_MATCH_SID_VALUE(0x144)
		 STREAM_MATCH_SID_MASK(0x3FF)>,
		<26 STREAM_CFG(PTLB_ID(0x4), STLB_ID(0x11), FETCH_SIZE(SIZE2), PTLB_EN, STLB_EN)
		 STREAM_MATCH_CFG(DIR_READ)
		 STREAM_MATCH_SID_VALUE(0x244)
		 STREAM_MATCH_SID_MASK(0x3FF)>,
		<27 STREAM_CFG(PTLB_ID(0x4), STLB_ID(0x12), FETCH_SIZE(SIZE2), PTLB_EN, STLB_EN)
		 STREAM_MATCH_CFG(DIR_READ)
		 STREAM_MATCH_SID_VALUE(0x344)
		 STREAM_MATCH_SID_MASK(0x3FF)>,
		<28 STREAM_CFG(PTLB_ID(0x4), STLB_ID(0x16), FETCH_SIZE(SIZE2), PTLB_EN, STLB_EN)
		 STREAM_MATCH_CFG(DIR_READ)
		 STREAM_MATCH_SID_VALUE(0xC4)
		 STREAM_MATCH_SID_MASK(0x3FF)>,
		<29 STREAM_CFG(PTLB_ID(0x4), STLB_ID(0x17), FETCH_SIZE(SIZE2), PTLB_EN, STLB_EN)
		 STREAM_MATCH_CFG(DIR_READ)
		 STREAM_MATCH_SID_VALUE(0x1C4)
		 STREAM_MATCH_SID_MASK(0x3FF)>,
		<30 STREAM_CFG(PTLB_ID(0x4), STLB_ID(0x2A), FETCH_SIZE(SIZE1), PTLB_EN, STLB_EN)
		 STREAM_MATCH_CFG(DIR_READ)
		 STREAM_MATCH_SID_VALUE(0x2C4)
		 STREAM_MATCH_SID_MASK(0x3FF)>,
		<31 STREAM_CFG(PTLB_ID(0x5), STLB_ID(0x18), FETCH_SIZE(SIZE2), PTLB_EN, STLB_EN)
		 STREAM_MATCH_CFG(DIR_READ)
		 STREAM_MATCH_SID_VALUE(0xE5)
		 STREAM_MATCH_SID_MASK(0x3FF)>,
		<32 STREAM_CFG(PTLB_ID(0x5), STLB_ID(0x2B), FETCH_SIZE(SIZE1), PTLB_EN, STLB_EN)
		 STREAM_MATCH_CFG(DIR_READ)
		 STREAM_MATCH_SID_VALUE(0x1E5)
		 STREAM_MATCH_SID_MASK(0x3FF)>,
		<33 STREAM_CFG(PTLB_ID(0x5), STLB_ID(0x2C), FETCH_SIZE(SIZE1), PTLB_EN, STLB_EN)
		 STREAM_MATCH_CFG(DIR_READ)
		 STREAM_MATCH_SID_VALUE(0x2E5)
		 STREAM_MATCH_SID_MASK(0x3FF)>,
		<34 STREAM_CFG(PTLB_ID(0x6), STLB_ID(0x4), FETCH_SIZE(SIZE16), PTLB_EN, STLB_EN)
		 STREAM_MATCH_CFG(DIR_READ)
		 STREAM_MATCH_SID_VALUE(0xA)
		 STREAM_MATCH_SID_MASK(0x3FF)>,
		<35 STREAM_CFG(PTLB_ID(0x6), STLB_ID(0x0), FETCH_SIZE(SIZE64), PTLB_DIS, STLB_DIS)
		 STREAM_MATCH_CFG(DIR_READ)
		 STREAM_MATCH_SID_VALUE(0x8A)
		 STREAM_MATCH_SID_MASK(0x3FF)>,
		<36 STREAM_CFG(PTLB_ID(0x6), STLB_ID(0x5), FETCH_SIZE(SIZE16), PTLB_EN, STLB_EN)
		 STREAM_MATCH_CFG(DIR_READ)
		 STREAM_MATCH_SID_VALUE(0x10A)
		 STREAM_MATCH_SID_MASK(0x3FF)>,
		<37 STREAM_CFG(PTLB_ID(0x6), STLB_ID(0x6), FETCH_SIZE(SIZE16), PTLB_EN, STLB_EN)
		 STREAM_MATCH_CFG(DIR_READ)
		 STREAM_MATCH_SID_VALUE(0x20A)
		 STREAM_MATCH_SID_MASK(0x3FF)>,
		<38 STREAM_CFG(PTLB_ID(0x6), STLB_ID(0x7), FETCH_SIZE(SIZE16), PTLB_EN, STLB_EN)
		 STREAM_MATCH_CFG(DIR_READ)
		 STREAM_MATCH_SID_VALUE(0x30A)
		 STREAM_MATCH_SID_MASK(0x3FF)>,
		<39 STREAM_CFG(PTLB_ID(0x6), STLB_ID(0xC), FETCH_SIZE(SIZE2), PTLB_EN, STLB_EN)
		 STREAM_MATCH_CFG(DIR_READ)
		 STREAM_MATCH_SID_VALUE(0x18A)
		 STREAM_MATCH_SID_MASK(0x3FF)>,
		<40 STREAM_CFG(PTLB_ID(0x6), STLB_ID(0xD), FETCH_SIZE(SIZE2), PTLB_EN, STLB_EN)
		 STREAM_MATCH_CFG(DIR_READ)
		 STREAM_MATCH_SID_VALUE(0x28A)
		 STREAM_MATCH_SID_MASK(0x3FF)>,
		<41 STREAM_CFG(PTLB_ID(0x6), STLB_ID(0xE), FETCH_SIZE(SIZE2), PTLB_EN, STLB_EN)
		 STREAM_MATCH_CFG(DIR_READ)
		 STREAM_MATCH_SID_VALUE(0x38A)
		 STREAM_MATCH_SID_MASK(0x3FF)>,
		<42 STREAM_CFG(PTLB_ID(0x7), STLB_ID(0xF), FETCH_SIZE(SIZE2), PTLB_EN, STLB_EN)
		 STREAM_MATCH_CFG(DIR_READ)
		 STREAM_MATCH_SID_VALUE(0x48)
		 STREAM_MATCH_SID_MASK(0x3FF)>,
		<43 STREAM_CFG(PTLB_ID(0x7), STLB_ID(0x10), FETCH_SIZE(SIZE2), PTLB_EN, STLB_EN)
		 STREAM_MATCH_CFG(DIR_READ)
		 STREAM_MATCH_SID_VALUE(0x148)
		 STREAM_MATCH_SID_MASK(0x3FF)>,
		<44 STREAM_CFG(PTLB_ID(0x7), STLB_ID(0x11), FETCH_SIZE(SIZE2), PTLB_EN, STLB_EN)
		 STREAM_MATCH_CFG(DIR_READ)
		 STREAM_MATCH_SID_VALUE(0x248)
		 STREAM_MATCH_SID_MASK(0x3FF)>,
		<45 STREAM_CFG(PTLB_ID(0x7), STLB_ID(0x12), FETCH_SIZE(SIZE2), PTLB_EN, STLB_EN)
		 STREAM_MATCH_CFG(DIR_READ)
		 STREAM_MATCH_SID_VALUE(0x348)
		 STREAM_MATCH_SID_MASK(0x3FF)>,
		<46 STREAM_CFG(PTLB_ID(0x8), STLB_ID(0x4), FETCH_SIZE(SIZE16), PTLB_EN, STLB_EN)
		 STREAM_MATCH_CFG(DIR_READ)
		 STREAM_MATCH_SID_VALUE(0xE)
		 STREAM_MATCH_SID_MASK(0x3FF)>,
		<47 STREAM_CFG(PTLB_ID(0x8), STLB_ID(0x0), FETCH_SIZE(SIZE64), PTLB_DIS, STLB_DIS)
		 STREAM_MATCH_CFG(DIR_READ)
		 STREAM_MATCH_SID_VALUE(0x8E)
		 STREAM_MATCH_SID_MASK(0x3FF)>,
		<48 STREAM_CFG(PTLB_ID(0x8), STLB_ID(0x5), FETCH_SIZE(SIZE16), PTLB_EN, STLB_EN)
		 STREAM_MATCH_CFG(DIR_READ)
		 STREAM_MATCH_SID_VALUE(0x10E)
		 STREAM_MATCH_SID_MASK(0x3FF)>,
		<49 STREAM_CFG(PTLB_ID(0x8), STLB_ID(0x6), FETCH_SIZE(SIZE16), PTLB_EN, STLB_EN)
		 STREAM_MATCH_CFG(DIR_READ)
		 STREAM_MATCH_SID_VALUE(0x20E)
		 STREAM_MATCH_SID_MASK(0x3FF)>,
		<50 STREAM_CFG(PTLB_ID(0x8), STLB_ID(0x7), FETCH_SIZE(SIZE16), PTLB_EN, STLB_EN)
		 STREAM_MATCH_CFG(DIR_READ)
		 STREAM_MATCH_SID_VALUE(0x30E)
		 STREAM_MATCH_SID_MASK(0x3FF)>,
		<51 STREAM_CFG(PTLB_ID(0x8), STLB_ID(0xC), FETCH_SIZE(SIZE2), PTLB_EN, STLB_EN)
		 STREAM_MATCH_CFG(DIR_READ)
		 STREAM_MATCH_SID_VALUE(0x18E)
		 STREAM_MATCH_SID_MASK(0x3FF)>,
		<52 STREAM_CFG(PTLB_ID(0x8), STLB_ID(0xD), FETCH_SIZE(SIZE2), PTLB_EN, STLB_EN)
		 STREAM_MATCH_CFG(DIR_READ)
		 STREAM_MATCH_SID_VALUE(0x28E)
		 STREAM_MATCH_SID_MASK(0x3FF)>,
		<53 STREAM_CFG(PTLB_ID(0x8), STLB_ID(0xE), FETCH_SIZE(SIZE2), PTLB_EN, STLB_EN)
		 STREAM_MATCH_CFG(DIR_READ)
		 STREAM_MATCH_SID_VALUE(0x38E)
		 STREAM_MATCH_SID_MASK(0x3FF)>,
		<54 STREAM_CFG(PTLB_ID(0x9), STLB_ID(0x1), FETCH_SIZE(SIZE64), PTLB_DIS, STLB_DIS)
		 STREAM_MATCH_CFG(DIR_READ)
		 STREAM_MATCH_SID_VALUE(0xAF)
		 STREAM_MATCH_SID_MASK(0x3FF)>,
		<55 STREAM_CFG(PTLB_ID(0x9), STLB_ID(0x13), FETCH_SIZE(SIZE2), PTLB_EN, STLB_EN)
		 STREAM_MATCH_CFG(DIR_READ)
		 STREAM_MATCH_SID_VALUE(0x1AF)
		 STREAM_MATCH_SID_MASK(0x3FF)>,
		<56 STREAM_CFG(PTLB_ID(0x9), STLB_ID(0x14), FETCH_SIZE(SIZE2), PTLB_EN, STLB_EN)
		 STREAM_MATCH_CFG(DIR_READ)
		 STREAM_MATCH_SID_VALUE(0x2AF)
		 STREAM_MATCH_SID_MASK(0x3FF)>,
		<57 STREAM_CFG(PTLB_ID(0x9), STLB_ID(0x15), FETCH_SIZE(SIZE2), PTLB_EN, STLB_EN)
		 STREAM_MATCH_CFG(DIR_READ)
		 STREAM_MATCH_SID_VALUE(0x3AF)
		 STREAM_MATCH_SID_MASK(0x3FF)>,
		<58 STREAM_CFG(PTLB_ID(0xA), STLB_ID(0xF), FETCH_SIZE(SIZE2), PTLB_EN, STLB_EN)
		 STREAM_MATCH_CFG(DIR_READ)
		 STREAM_MATCH_SID_VALUE(0x4C)
		 STREAM_MATCH_SID_MASK(0x3FF)>,
		<59 STREAM_CFG(PTLB_ID(0xA), STLB_ID(0x10), FETCH_SIZE(SIZE2), PTLB_EN, STLB_EN)
		 STREAM_MATCH_CFG(DIR_READ)
		 STREAM_MATCH_SID_VALUE(0x14C)
		 STREAM_MATCH_SID_MASK(0x3FF)>,
		<60 STREAM_CFG(PTLB_ID(0xA), STLB_ID(0x11), FETCH_SIZE(SIZE2), PTLB_EN, STLB_EN)
		 STREAM_MATCH_CFG(DIR_READ)
		 STREAM_MATCH_SID_VALUE(0x24C)
		 STREAM_MATCH_SID_MASK(0x3FF)>,
		<61 STREAM_CFG(PTLB_ID(0xA), STLB_ID(0x12), FETCH_SIZE(SIZE2), PTLB_EN, STLB_EN)
		 STREAM_MATCH_CFG(DIR_READ)
		 STREAM_MATCH_SID_VALUE(0x34C)
		 STREAM_MATCH_SID_MASK(0x3FF)>,
		<62 STREAM_CFG(PTLB_ID(0xA), STLB_ID(0x16), FETCH_SIZE(SIZE2), PTLB_EN, STLB_EN)
		 STREAM_MATCH_CFG(DIR_READ)
		 STREAM_MATCH_SID_VALUE(0xCC)
		 STREAM_MATCH_SID_MASK(0x3FF)>,
		<63 STREAM_CFG(PTLB_ID(0xA), STLB_ID(0x17), FETCH_SIZE(SIZE2), PTLB_EN, STLB_EN)
		 STREAM_MATCH_CFG(DIR_READ)
		 STREAM_MATCH_SID_VALUE(0x1CC)
		 STREAM_MATCH_SID_MASK(0x3FF)>,
		<64 STREAM_CFG(PTLB_ID(0xA), STLB_ID(0x2A), FETCH_SIZE(SIZE1), PTLB_EN, STLB_EN)
		 STREAM_MATCH_CFG(DIR_READ)
		 STREAM_MATCH_SID_VALUE(0x2CC)
		 STREAM_MATCH_SID_MASK(0x3FF)>,
		<65 STREAM_CFG(PTLB_ID(0xB), STLB_ID(0x18), FETCH_SIZE(SIZE2), PTLB_EN, STLB_EN)
		 STREAM_MATCH_CFG(DIR_READ)
		 STREAM_MATCH_SID_VALUE(0xED)
		 STREAM_MATCH_SID_MASK(0x3FF)>,
		<66 STREAM_CFG(PTLB_ID(0xB), STLB_ID(0x2B), FETCH_SIZE(SIZE1), PTLB_EN, STLB_EN)
		 STREAM_MATCH_CFG(DIR_READ)
		 STREAM_MATCH_SID_VALUE(0x1ED)
		 STREAM_MATCH_SID_MASK(0x3FF)>,
		<67 STREAM_CFG(PTLB_ID(0xB), STLB_ID(0x2C), FETCH_SIZE(SIZE1), PTLB_EN, STLB_EN)
		 STREAM_MATCH_CFG(DIR_READ)
		 STREAM_MATCH_SID_VALUE(0x2ED)
		 STREAM_MATCH_SID_MASK(0x3FF)>,
		<68 STREAM_CFG(PTLB_ID(0xC), STLB_ID(0x31), FETCH_SIZE(SIZE1), PTLB_EN, STLB_EN)
		 STREAM_MATCH_CFG(DIR_READ)
		 STREAM_MATCH_SID_VALUE(0x11)
		 STREAM_MATCH_SID_MASK(0x3FF)>,
		<69 STREAM_CFG(PTLB_ID(0xD), STLB_ID(0x32), FETCH_SIZE(SIZE1), PTLB_EN, STLB_EN)
		 STREAM_MATCH_CFG(DIR_READ)
		 STREAM_MATCH_SID_VALUE(0x12)
		 STREAM_MATCH_SID_MASK(0x3FF)>,
		<70 STREAM_CFG(PTLB_ID(0xE), STLB_ID(0x3B), FETCH_SIZE(SIZE1), PTLB_DIS, STLB_DIS)
		 STREAM_MATCH_CFG(DIR_WRITE)
		 STREAM_MATCH_SID_VALUE(0x0)
		 STREAM_MATCH_SID_MASK(0x3FF)>;
		pmmu2,default_stream =
		<STREAM_CFG(PTLB_ID(0x0), STLB_ID(0x8), FETCH_SIZE(SIZE16), PTLB_EN, STLB_EN)>;
		pmmu2,stream_property =
		<1 STREAM_CFG(PTLB_ID(0x0), STLB_ID(0x2), FETCH_SIZE(SIZE64), PTLB_DIS, STLB_DIS)
		 STREAM_MATCH_CFG(DIR_READ)
		 STREAM_MATCH_SID_VALUE(0x82)
		 STREAM_MATCH_SID_MASK(0x3FF)>,
		<2 STREAM_CFG(PTLB_ID(0x0), STLB_ID(0x9), FETCH_SIZE(SIZE16), PTLB_EN, STLB_EN)
		 STREAM_MATCH_CFG(DIR_READ)
		 STREAM_MATCH_SID_VALUE(0x102)
		 STREAM_MATCH_SID_MASK(0x3FF)>,
		<3 STREAM_CFG(PTLB_ID(0x0), STLB_ID(0xA), FETCH_SIZE(SIZE16), PTLB_EN, STLB_EN)
		 STREAM_MATCH_CFG(DIR_READ)
		 STREAM_MATCH_SID_VALUE(0x202)
		 STREAM_MATCH_SID_MASK(0x3FF)>,
		<4 STREAM_CFG(PTLB_ID(0x0), STLB_ID(0xB), FETCH_SIZE(SIZE16), PTLB_EN, STLB_EN)
		 STREAM_MATCH_CFG(DIR_READ)
		 STREAM_MATCH_SID_VALUE(0x302)
		 STREAM_MATCH_SID_MASK(0x3FF)>,
		<5 STREAM_CFG(PTLB_ID(0x0), STLB_ID(0x19), FETCH_SIZE(SIZE2), PTLB_EN, STLB_EN)
		 STREAM_MATCH_CFG(DIR_READ)
		 STREAM_MATCH_SID_VALUE(0x182)
		 STREAM_MATCH_SID_MASK(0x3FF)>,
		<6 STREAM_CFG(PTLB_ID(0x0), STLB_ID(0x1A), FETCH_SIZE(SIZE2), PTLB_EN, STLB_EN)
		 STREAM_MATCH_CFG(DIR_READ)
		 STREAM_MATCH_SID_VALUE(0x282)
		 STREAM_MATCH_SID_MASK(0x3FF)>,
		<7 STREAM_CFG(PTLB_ID(0x0), STLB_ID(0x1B), FETCH_SIZE(SIZE2), PTLB_EN, STLB_EN)
		 STREAM_MATCH_CFG(DIR_READ)
		 STREAM_MATCH_SID_VALUE(0x382)
		 STREAM_MATCH_SID_MASK(0x3FF)>,
		<8 STREAM_CFG(PTLB_ID(0x1), STLB_ID(0x1C), FETCH_SIZE(SIZE2), PTLB_EN, STLB_EN)
		 STREAM_MATCH_CFG(DIR_READ)
		 STREAM_MATCH_SID_VALUE(0x40)
		 STREAM_MATCH_SID_MASK(0x3FF)>,
		<9 STREAM_CFG(PTLB_ID(0x1), STLB_ID(0x1D), FETCH_SIZE(SIZE2), PTLB_EN, STLB_EN)
		 STREAM_MATCH_CFG(DIR_READ)
		 STREAM_MATCH_SID_VALUE(0x140)
		 STREAM_MATCH_SID_MASK(0x3FF)>,
		<10 STREAM_CFG(PTLB_ID(0x1), STLB_ID(0x1E), FETCH_SIZE(SIZE2), PTLB_EN, STLB_EN)
		 STREAM_MATCH_CFG(DIR_READ)
		 STREAM_MATCH_SID_VALUE(0x240)
		 STREAM_MATCH_SID_MASK(0x3FF)>,
		<11 STREAM_CFG(PTLB_ID(0x1), STLB_ID(0x1F), FETCH_SIZE(SIZE2), PTLB_EN, STLB_EN)
		 STREAM_MATCH_CFG(DIR_READ)
		 STREAM_MATCH_SID_VALUE(0x340)
		 STREAM_MATCH_SID_MASK(0x3FF)>,
		<12 STREAM_CFG(PTLB_ID(0x2), STLB_ID(0x8), FETCH_SIZE(SIZE16), PTLB_EN, STLB_EN)
		 STREAM_MATCH_CFG(DIR_READ)
		 STREAM_MATCH_SID_VALUE(0x6)
		 STREAM_MATCH_SID_MASK(0x3FF)>,
		<13 STREAM_CFG(PTLB_ID(0x2), STLB_ID(0x2), FETCH_SIZE(SIZE64), PTLB_DIS, STLB_DIS)
		 STREAM_MATCH_CFG(DIR_READ)
		 STREAM_MATCH_SID_VALUE(0x86)
		 STREAM_MATCH_SID_MASK(0x3FF)>,
		<14 STREAM_CFG(PTLB_ID(0x2), STLB_ID(0x9), FETCH_SIZE(SIZE16), PTLB_EN, STLB_EN)
		 STREAM_MATCH_CFG(DIR_READ)
		 STREAM_MATCH_SID_VALUE(0x106)
		 STREAM_MATCH_SID_MASK(0x3FF)>,
		<15 STREAM_CFG(PTLB_ID(0x2), STLB_ID(0xA), FETCH_SIZE(SIZE16), PTLB_EN, STLB_EN)
		 STREAM_MATCH_CFG(DIR_READ)
		 STREAM_MATCH_SID_VALUE(0x206)
		 STREAM_MATCH_SID_MASK(0x3FF)>,
		<16 STREAM_CFG(PTLB_ID(0x2), STLB_ID(0xB), FETCH_SIZE(SIZE16), PTLB_EN, STLB_EN)
		 STREAM_MATCH_CFG(DIR_READ)
		 STREAM_MATCH_SID_VALUE(0x306)
		 STREAM_MATCH_SID_MASK(0x3FF)>,
		<17 STREAM_CFG(PTLB_ID(0x2), STLB_ID(0x19), FETCH_SIZE(SIZE2), PTLB_EN, STLB_EN)
		 STREAM_MATCH_CFG(DIR_READ)
		 STREAM_MATCH_SID_VALUE(0x186)
		 STREAM_MATCH_SID_MASK(0x3FF)>,
		<18 STREAM_CFG(PTLB_ID(0x2), STLB_ID(0x1A), FETCH_SIZE(SIZE2), PTLB_EN, STLB_EN)
		 STREAM_MATCH_CFG(DIR_READ)
		 STREAM_MATCH_SID_VALUE(0x286)
		 STREAM_MATCH_SID_MASK(0x3FF)>,
		<19 STREAM_CFG(PTLB_ID(0x2), STLB_ID(0x1B), FETCH_SIZE(SIZE2), PTLB_EN, STLB_EN)
		 STREAM_MATCH_CFG(DIR_READ)
		 STREAM_MATCH_SID_VALUE(0x386)
		 STREAM_MATCH_SID_MASK(0x3FF)>,
		<20 STREAM_CFG(PTLB_ID(0x3), STLB_ID(0x3), FETCH_SIZE(SIZE64), PTLB_DIS, STLB_DIS)
		 STREAM_MATCH_CFG(DIR_READ)
		 STREAM_MATCH_SID_VALUE(0xA7)
		 STREAM_MATCH_SID_MASK(0x3FF)>,
		<21 STREAM_CFG(PTLB_ID(0x3), STLB_ID(0x20), FETCH_SIZE(SIZE2), PTLB_EN, STLB_EN)
		 STREAM_MATCH_CFG(DIR_READ)
		 STREAM_MATCH_SID_VALUE(0x1A7)
		 STREAM_MATCH_SID_MASK(0x3FF)>,
		<22 STREAM_CFG(PTLB_ID(0x3), STLB_ID(0x21), FETCH_SIZE(SIZE2), PTLB_EN, STLB_EN)
		 STREAM_MATCH_CFG(DIR_READ)
		 STREAM_MATCH_SID_VALUE(0x2A7)
		 STREAM_MATCH_SID_MASK(0x3FF)>,
		<23 STREAM_CFG(PTLB_ID(0x3), STLB_ID(0x22), FETCH_SIZE(SIZE2), PTLB_EN, STLB_EN)
		 STREAM_MATCH_CFG(DIR_READ)
		 STREAM_MATCH_SID_VALUE(0x3A7)
		 STREAM_MATCH_SID_MASK(0x3FF)>,
		<24 STREAM_CFG(PTLB_ID(0x4), STLB_ID(0x1C), FETCH_SIZE(SIZE2), PTLB_EN, STLB_EN)
		 STREAM_MATCH_CFG(DIR_READ)
		 STREAM_MATCH_SID_VALUE(0x44)
		 STREAM_MATCH_SID_MASK(0x3FF)>,
		<25 STREAM_CFG(PTLB_ID(0x4), STLB_ID(0x1D), FETCH_SIZE(SIZE2), PTLB_EN, STLB_EN)
		 STREAM_MATCH_CFG(DIR_READ)
		 STREAM_MATCH_SID_VALUE(0x144)
		 STREAM_MATCH_SID_MASK(0x3FF)>,
		<26 STREAM_CFG(PTLB_ID(0x4), STLB_ID(0x1E), FETCH_SIZE(SIZE2), PTLB_EN, STLB_EN)
		 STREAM_MATCH_CFG(DIR_READ)
		 STREAM_MATCH_SID_VALUE(0x244)
		 STREAM_MATCH_SID_MASK(0x3FF)>,
		<27 STREAM_CFG(PTLB_ID(0x4), STLB_ID(0x1F), FETCH_SIZE(SIZE2), PTLB_EN, STLB_EN)
		 STREAM_MATCH_CFG(DIR_READ)
		 STREAM_MATCH_SID_VALUE(0x344)
		 STREAM_MATCH_SID_MASK(0x3FF)>,
		<28 STREAM_CFG(PTLB_ID(0x4), STLB_ID(0x23), FETCH_SIZE(SIZE2), PTLB_EN, STLB_EN)
		 STREAM_MATCH_CFG(DIR_READ)
		 STREAM_MATCH_SID_VALUE(0xC4)
		 STREAM_MATCH_SID_MASK(0x3FF)>,
		<29 STREAM_CFG(PTLB_ID(0x4), STLB_ID(0x24), FETCH_SIZE(SIZE2), PTLB_EN, STLB_EN)
		 STREAM_MATCH_CFG(DIR_READ)
		 STREAM_MATCH_SID_VALUE(0x1C4)
		 STREAM_MATCH_SID_MASK(0x3FF)>,
		<30 STREAM_CFG(PTLB_ID(0x4), STLB_ID(0x33), FETCH_SIZE(SIZE1), PTLB_EN, STLB_EN)
		 STREAM_MATCH_CFG(DIR_READ)
		 STREAM_MATCH_SID_VALUE(0x2C4)
		 STREAM_MATCH_SID_MASK(0x3FF)>,
		<31 STREAM_CFG(PTLB_ID(0x5), STLB_ID(0x25), FETCH_SIZE(SIZE2), PTLB_EN, STLB_EN)
		 STREAM_MATCH_CFG(DIR_READ)
		 STREAM_MATCH_SID_VALUE(0xE5)
		 STREAM_MATCH_SID_MASK(0x3FF)>,
		<32 STREAM_CFG(PTLB_ID(0x5), STLB_ID(0x34), FETCH_SIZE(SIZE1), PTLB_EN, STLB_EN)
		 STREAM_MATCH_CFG(DIR_READ)
		 STREAM_MATCH_SID_VALUE(0x1E5)
		 STREAM_MATCH_SID_MASK(0x3FF)>,
		<33 STREAM_CFG(PTLB_ID(0x5), STLB_ID(0x35), FETCH_SIZE(SIZE1), PTLB_EN, STLB_EN)
		 STREAM_MATCH_CFG(DIR_READ)
		 STREAM_MATCH_SID_VALUE(0x2E5)
		 STREAM_MATCH_SID_MASK(0x3FF)>,
		<34 STREAM_CFG(PTLB_ID(0x6), STLB_ID(0x8), FETCH_SIZE(SIZE16), PTLB_EN, STLB_EN)
		 STREAM_MATCH_CFG(DIR_READ)
		 STREAM_MATCH_SID_VALUE(0xA)
		 STREAM_MATCH_SID_MASK(0x3FF)>,
		<35 STREAM_CFG(PTLB_ID(0x6), STLB_ID(0x2), FETCH_SIZE(SIZE64), PTLB_DIS, STLB_DIS)
		 STREAM_MATCH_CFG(DIR_READ)
		 STREAM_MATCH_SID_VALUE(0x8A)
		 STREAM_MATCH_SID_MASK(0x3FF)>,
		<36 STREAM_CFG(PTLB_ID(0x6), STLB_ID(0x9), FETCH_SIZE(SIZE16), PTLB_EN, STLB_EN)
		 STREAM_MATCH_CFG(DIR_READ)
		 STREAM_MATCH_SID_VALUE(0x10A)
		 STREAM_MATCH_SID_MASK(0x3FF)>,
		<37 STREAM_CFG(PTLB_ID(0x6), STLB_ID(0xA), FETCH_SIZE(SIZE16), PTLB_EN, STLB_EN)
		 STREAM_MATCH_CFG(DIR_READ)
		 STREAM_MATCH_SID_VALUE(0x20A)
		 STREAM_MATCH_SID_MASK(0x3FF)>,
		<38 STREAM_CFG(PTLB_ID(0x6), STLB_ID(0xB), FETCH_SIZE(SIZE16), PTLB_EN, STLB_EN)
		 STREAM_MATCH_CFG(DIR_READ)
		 STREAM_MATCH_SID_VALUE(0x30A)
		 STREAM_MATCH_SID_MASK(0x3FF)>,
		<39 STREAM_CFG(PTLB_ID(0x6), STLB_ID(0x19), FETCH_SIZE(SIZE2), PTLB_EN, STLB_EN)
		 STREAM_MATCH_CFG(DIR_READ)
		 STREAM_MATCH_SID_VALUE(0x18A)
		 STREAM_MATCH_SID_MASK(0x3FF)>,
		<40 STREAM_CFG(PTLB_ID(0x6), STLB_ID(0x1A), FETCH_SIZE(SIZE2), PTLB_EN, STLB_EN)
		 STREAM_MATCH_CFG(DIR_READ)
		 STREAM_MATCH_SID_VALUE(0x28A)
		 STREAM_MATCH_SID_MASK(0x3FF)>,
		<41 STREAM_CFG(PTLB_ID(0x6), STLB_ID(0x1B), FETCH_SIZE(SIZE2), PTLB_EN, STLB_EN)
		 STREAM_MATCH_CFG(DIR_READ)
		 STREAM_MATCH_SID_VALUE(0x38A)
		 STREAM_MATCH_SID_MASK(0x3FF)>,
		<42 STREAM_CFG(PTLB_ID(0x7), STLB_ID(0x1C), FETCH_SIZE(SIZE2), PTLB_EN, STLB_EN)
		 STREAM_MATCH_CFG(DIR_READ)
		 STREAM_MATCH_SID_VALUE(0x48)
		 STREAM_MATCH_SID_MASK(0x3FF)>,
		<43 STREAM_CFG(PTLB_ID(0x7), STLB_ID(0x1D), FETCH_SIZE(SIZE2), PTLB_EN, STLB_EN)
		 STREAM_MATCH_CFG(DIR_READ)
		 STREAM_MATCH_SID_VALUE(0x148)
		 STREAM_MATCH_SID_MASK(0x3FF)>,
		<44 STREAM_CFG(PTLB_ID(0x7), STLB_ID(0x1E), FETCH_SIZE(SIZE2), PTLB_EN, STLB_EN)
		 STREAM_MATCH_CFG(DIR_READ)
		 STREAM_MATCH_SID_VALUE(0x248)
		 STREAM_MATCH_SID_MASK(0x3FF)>,
		<45 STREAM_CFG(PTLB_ID(0x7), STLB_ID(0x1F), FETCH_SIZE(SIZE2), PTLB_EN, STLB_EN)
		 STREAM_MATCH_CFG(DIR_READ)
		 STREAM_MATCH_SID_VALUE(0x348)
		 STREAM_MATCH_SID_MASK(0x3FF)>,
		<46 STREAM_CFG(PTLB_ID(0x8), STLB_ID(0x8), FETCH_SIZE(SIZE16), PTLB_EN, STLB_EN)
		 STREAM_MATCH_CFG(DIR_READ)
		 STREAM_MATCH_SID_VALUE(0xE)
		 STREAM_MATCH_SID_MASK(0x3FF)>,
		<47 STREAM_CFG(PTLB_ID(0x8), STLB_ID(0x2), FETCH_SIZE(SIZE64), PTLB_DIS, STLB_DIS)
		 STREAM_MATCH_CFG(DIR_READ)
		 STREAM_MATCH_SID_VALUE(0x8E)
		 STREAM_MATCH_SID_MASK(0x3FF)>,
		<48 STREAM_CFG(PTLB_ID(0x8), STLB_ID(0x9), FETCH_SIZE(SIZE16), PTLB_EN, STLB_EN)
		 STREAM_MATCH_CFG(DIR_READ)
		 STREAM_MATCH_SID_VALUE(0x10E)
		 STREAM_MATCH_SID_MASK(0x3FF)>,
		<49 STREAM_CFG(PTLB_ID(0x8), STLB_ID(0xA), FETCH_SIZE(SIZE16), PTLB_EN, STLB_EN)
		 STREAM_MATCH_CFG(DIR_READ)
		 STREAM_MATCH_SID_VALUE(0x20E)
		 STREAM_MATCH_SID_MASK(0x3FF)>,
		<50 STREAM_CFG(PTLB_ID(0x8), STLB_ID(0xB), FETCH_SIZE(SIZE16), PTLB_EN, STLB_EN)
		 STREAM_MATCH_CFG(DIR_READ)
		 STREAM_MATCH_SID_VALUE(0x30E)
		 STREAM_MATCH_SID_MASK(0x3FF)>,
		<51 STREAM_CFG(PTLB_ID(0x8), STLB_ID(0x19), FETCH_SIZE(SIZE2), PTLB_EN, STLB_EN)
		 STREAM_MATCH_CFG(DIR_READ)
		 STREAM_MATCH_SID_VALUE(0x18E)
		 STREAM_MATCH_SID_MASK(0x3FF)>,
		<52 STREAM_CFG(PTLB_ID(0x8), STLB_ID(0x1A), FETCH_SIZE(SIZE2), PTLB_EN, STLB_EN)
		 STREAM_MATCH_CFG(DIR_READ)
		 STREAM_MATCH_SID_VALUE(0x28E)
		 STREAM_MATCH_SID_MASK(0x3FF)>,
		<53 STREAM_CFG(PTLB_ID(0x8), STLB_ID(0x1B), FETCH_SIZE(SIZE2), PTLB_EN, STLB_EN)
		 STREAM_MATCH_CFG(DIR_READ)
		 STREAM_MATCH_SID_VALUE(0x38E)
		 STREAM_MATCH_SID_MASK(0x3FF)>,
		<54 STREAM_CFG(PTLB_ID(0x9), STLB_ID(0x3), FETCH_SIZE(SIZE64), PTLB_DIS, STLB_DIS)
		 STREAM_MATCH_CFG(DIR_READ)
		 STREAM_MATCH_SID_VALUE(0xAF)
		 STREAM_MATCH_SID_MASK(0x3FF)>,
		<55 STREAM_CFG(PTLB_ID(0x9), STLB_ID(0x20), FETCH_SIZE(SIZE2), PTLB_EN, STLB_EN)
		 STREAM_MATCH_CFG(DIR_READ)
		 STREAM_MATCH_SID_VALUE(0x1AF)
		 STREAM_MATCH_SID_MASK(0x3FF)>,
		<56 STREAM_CFG(PTLB_ID(0x9), STLB_ID(0x21), FETCH_SIZE(SIZE2), PTLB_EN, STLB_EN)
		 STREAM_MATCH_CFG(DIR_READ)
		 STREAM_MATCH_SID_VALUE(0x2AF)
		 STREAM_MATCH_SID_MASK(0x3FF)>,
		<57 STREAM_CFG(PTLB_ID(0x9), STLB_ID(0x22), FETCH_SIZE(SIZE2), PTLB_EN, STLB_EN)
		 STREAM_MATCH_CFG(DIR_READ)
		 STREAM_MATCH_SID_VALUE(0x3AF)
		 STREAM_MATCH_SID_MASK(0x3FF)>,
		<58 STREAM_CFG(PTLB_ID(0xA), STLB_ID(0x1C), FETCH_SIZE(SIZE2), PTLB_EN, STLB_EN)
		 STREAM_MATCH_CFG(DIR_READ)
		 STREAM_MATCH_SID_VALUE(0x4C)
		 STREAM_MATCH_SID_MASK(0x3FF)>,
		<59 STREAM_CFG(PTLB_ID(0xA), STLB_ID(0x1D), FETCH_SIZE(SIZE2), PTLB_EN, STLB_EN)
		 STREAM_MATCH_CFG(DIR_READ)
		 STREAM_MATCH_SID_VALUE(0x14C)
		 STREAM_MATCH_SID_MASK(0x3FF)>,
		<60 STREAM_CFG(PTLB_ID(0xA), STLB_ID(0x1E), FETCH_SIZE(SIZE2), PTLB_EN, STLB_EN)
		 STREAM_MATCH_CFG(DIR_READ)
		 STREAM_MATCH_SID_VALUE(0x24C)
		 STREAM_MATCH_SID_MASK(0x3FF)>,
		<61 STREAM_CFG(PTLB_ID(0xA), STLB_ID(0x1F), FETCH_SIZE(SIZE2), PTLB_EN, STLB_EN)
		 STREAM_MATCH_CFG(DIR_READ)
		 STREAM_MATCH_SID_VALUE(0x34C)
		 STREAM_MATCH_SID_MASK(0x3FF)>,
		<62 STREAM_CFG(PTLB_ID(0xA), STLB_ID(0x23), FETCH_SIZE(SIZE2), PTLB_EN, STLB_EN)
		 STREAM_MATCH_CFG(DIR_READ)
		 STREAM_MATCH_SID_VALUE(0xCC)
		 STREAM_MATCH_SID_MASK(0x3FF)>,
		<63 STREAM_CFG(PTLB_ID(0xA), STLB_ID(0x24), FETCH_SIZE(SIZE2), PTLB_EN, STLB_EN)
		 STREAM_MATCH_CFG(DIR_READ)
		 STREAM_MATCH_SID_VALUE(0x1CC)
		 STREAM_MATCH_SID_MASK(0x3FF)>,
		<64 STREAM_CFG(PTLB_ID(0xA), STLB_ID(0x33), FETCH_SIZE(SIZE1), PTLB_EN, STLB_EN)
		 STREAM_MATCH_CFG(DIR_READ)
		 STREAM_MATCH_SID_VALUE(0x2CC)
		 STREAM_MATCH_SID_MASK(0x3FF)>,
		<65 STREAM_CFG(PTLB_ID(0xB), STLB_ID(0x25), FETCH_SIZE(SIZE2), PTLB_EN, STLB_EN)
		 STREAM_MATCH_CFG(DIR_READ)
		 STREAM_MATCH_SID_VALUE(0xED)
		 STREAM_MATCH_SID_MASK(0x3FF)>,
		<66 STREAM_CFG(PTLB_ID(0xB), STLB_ID(0x34), FETCH_SIZE(SIZE1), PTLB_EN, STLB_EN)
		 STREAM_MATCH_CFG(DIR_READ)
		 STREAM_MATCH_SID_VALUE(0x1ED)
		 STREAM_MATCH_SID_MASK(0x3FF)>,
		<67 STREAM_CFG(PTLB_ID(0xB), STLB_ID(0x35), FETCH_SIZE(SIZE1), PTLB_EN, STLB_EN)
		 STREAM_MATCH_CFG(DIR_READ)
		 STREAM_MATCH_SID_VALUE(0x2ED)
		 STREAM_MATCH_SID_MASK(0x3FF)>,
		<68 STREAM_CFG(PTLB_ID(0xC), STLB_ID(0x36), FETCH_SIZE(SIZE1), PTLB_EN, STLB_EN)
		 STREAM_MATCH_CFG(DIR_READ)
		 STREAM_MATCH_SID_VALUE(0x10)
		 STREAM_MATCH_SID_MASK(0x3FF)>,
		<69 STREAM_CFG(PTLB_ID(0xD), STLB_ID(0x37), FETCH_SIZE(SIZE1), PTLB_EN, STLB_EN)
		 STREAM_MATCH_CFG(DIR_READ)
		 STREAM_MATCH_SID_VALUE(0x14)
		 STREAM_MATCH_SID_MASK(0x3FF)>,
		<70 STREAM_CFG(PTLB_ID(0xE), STLB_ID(0x38), FETCH_SIZE(SIZE1), PTLB_DIS, STLB_EN)
		 STREAM_MATCH_CFG(DIR_WRITE)
		 STREAM_MATCH_SID_VALUE(0x0)
		 STREAM_MATCH_SID_MASK(0x3FF)>,
		<71 STREAM_CFG(PTLB_ID(0xF), STLB_ID(0x39), FETCH_SIZE(SIZE1), PTLB_DIS, STLB_EN)
		 STREAM_MATCH_CFG(DIR_WRITE)
		 STREAM_MATCH_SID_VALUE(0x1)
		 STREAM_MATCH_SID_MASK(0x3FF)>;
		pmmu3,default_stream =
		<STREAM_CFG(PTLB_ID(0x0), STLB_ID(0x8), FETCH_SIZE(SIZE16), PTLB_EN, STLB_EN)>;
		pmmu3,stream_property =
		<1 STREAM_CFG(PTLB_ID(0x0), STLB_ID(0x2), FETCH_SIZE(SIZE64), PTLB_DIS, STLB_DIS)
		 STREAM_MATCH_CFG(DIR_READ)
		 STREAM_MATCH_SID_VALUE(0x82)
		 STREAM_MATCH_SID_MASK(0x3FF)>,
		<2 STREAM_CFG(PTLB_ID(0x0), STLB_ID(0x9), FETCH_SIZE(SIZE16), PTLB_EN, STLB_EN)
		 STREAM_MATCH_CFG(DIR_READ)
		 STREAM_MATCH_SID_VALUE(0x102)
		 STREAM_MATCH_SID_MASK(0x3FF)>,
		<3 STREAM_CFG(PTLB_ID(0x0), STLB_ID(0xA), FETCH_SIZE(SIZE16), PTLB_EN, STLB_EN)
		 STREAM_MATCH_CFG(DIR_READ)
		 STREAM_MATCH_SID_VALUE(0x202)
		 STREAM_MATCH_SID_MASK(0x3FF)>,
		<4 STREAM_CFG(PTLB_ID(0x0), STLB_ID(0xB), FETCH_SIZE(SIZE16), PTLB_EN, STLB_EN)
		 STREAM_MATCH_CFG(DIR_READ)
		 STREAM_MATCH_SID_VALUE(0x302)
		 STREAM_MATCH_SID_MASK(0x3FF)>,
		<5 STREAM_CFG(PTLB_ID(0x0), STLB_ID(0x19), FETCH_SIZE(SIZE2), PTLB_EN, STLB_EN)
		 STREAM_MATCH_CFG(DIR_READ)
		 STREAM_MATCH_SID_VALUE(0x182)
		 STREAM_MATCH_SID_MASK(0x3FF)>,
		<6 STREAM_CFG(PTLB_ID(0x0), STLB_ID(0x1A), FETCH_SIZE(SIZE2), PTLB_EN, STLB_EN)
		 STREAM_MATCH_CFG(DIR_READ)
		 STREAM_MATCH_SID_VALUE(0x282)
		 STREAM_MATCH_SID_MASK(0x3FF)>,
		<7 STREAM_CFG(PTLB_ID(0x0), STLB_ID(0x1B), FETCH_SIZE(SIZE2), PTLB_EN, STLB_EN)
		 STREAM_MATCH_CFG(DIR_READ)
		 STREAM_MATCH_SID_VALUE(0x382)
		 STREAM_MATCH_SID_MASK(0x3FF)>,
		<8 STREAM_CFG(PTLB_ID(0x1), STLB_ID(0x1C), FETCH_SIZE(SIZE2), PTLB_EN, STLB_EN)
		 STREAM_MATCH_CFG(DIR_READ)
		 STREAM_MATCH_SID_VALUE(0x40)
		 STREAM_MATCH_SID_MASK(0x3FF)>,
		<9 STREAM_CFG(PTLB_ID(0x1), STLB_ID(0x1D), FETCH_SIZE(SIZE2), PTLB_EN, STLB_EN)
		 STREAM_MATCH_CFG(DIR_READ)
		 STREAM_MATCH_SID_VALUE(0x140)
		 STREAM_MATCH_SID_MASK(0x3FF)>,
		<10 STREAM_CFG(PTLB_ID(0x1), STLB_ID(0x1E), FETCH_SIZE(SIZE2), PTLB_EN, STLB_EN)
		 STREAM_MATCH_CFG(DIR_READ)
		 STREAM_MATCH_SID_VALUE(0x240)
		 STREAM_MATCH_SID_MASK(0x3FF)>,
		<11 STREAM_CFG(PTLB_ID(0x1), STLB_ID(0x1F), FETCH_SIZE(SIZE2), PTLB_EN, STLB_EN)
		 STREAM_MATCH_CFG(DIR_READ)
		 STREAM_MATCH_SID_VALUE(0x340)
		 STREAM_MATCH_SID_MASK(0x3FF)>,
		<12 STREAM_CFG(PTLB_ID(0x2), STLB_ID(0x8), FETCH_SIZE(SIZE16), PTLB_EN, STLB_EN)
		 STREAM_MATCH_CFG(DIR_READ)
		 STREAM_MATCH_SID_VALUE(0x6)
		 STREAM_MATCH_SID_MASK(0x3FF)>,
		<13 STREAM_CFG(PTLB_ID(0x2), STLB_ID(0x2), FETCH_SIZE(SIZE64), PTLB_DIS, STLB_DIS)
		 STREAM_MATCH_CFG(DIR_READ)
		 STREAM_MATCH_SID_VALUE(0x86)
		 STREAM_MATCH_SID_MASK(0x3FF)>,
		<14 STREAM_CFG(PTLB_ID(0x2), STLB_ID(0x9), FETCH_SIZE(SIZE16), PTLB_EN, STLB_EN)
		 STREAM_MATCH_CFG(DIR_READ)
		 STREAM_MATCH_SID_VALUE(0x106)
		 STREAM_MATCH_SID_MASK(0x3FF)>,
		<15 STREAM_CFG(PTLB_ID(0x2), STLB_ID(0xA), FETCH_SIZE(SIZE16), PTLB_EN, STLB_EN)
		 STREAM_MATCH_CFG(DIR_READ)
		 STREAM_MATCH_SID_VALUE(0x206)
		 STREAM_MATCH_SID_MASK(0x3FF)>,
		<16 STREAM_CFG(PTLB_ID(0x2), STLB_ID(0xB), FETCH_SIZE(SIZE16), PTLB_EN, STLB_EN)
		 STREAM_MATCH_CFG(DIR_READ)
		 STREAM_MATCH_SID_VALUE(0x306)
		 STREAM_MATCH_SID_MASK(0x3FF)>,
		<17 STREAM_CFG(PTLB_ID(0x2), STLB_ID(0x19), FETCH_SIZE(SIZE2), PTLB_EN, STLB_EN)
		 STREAM_MATCH_CFG(DIR_READ)
		 STREAM_MATCH_SID_VALUE(0x186)
		 STREAM_MATCH_SID_MASK(0x3FF)>,
		<18 STREAM_CFG(PTLB_ID(0x2), STLB_ID(0x1A), FETCH_SIZE(SIZE2), PTLB_EN, STLB_EN)
		 STREAM_MATCH_CFG(DIR_READ)
		 STREAM_MATCH_SID_VALUE(0x286)
		 STREAM_MATCH_SID_MASK(0x3FF)>,
		<19 STREAM_CFG(PTLB_ID(0x2), STLB_ID(0x1B), FETCH_SIZE(SIZE2), PTLB_EN, STLB_EN)
		 STREAM_MATCH_CFG(DIR_READ)
		 STREAM_MATCH_SID_VALUE(0x386)
		 STREAM_MATCH_SID_MASK(0x3FF)>,
		<20 STREAM_CFG(PTLB_ID(0x3), STLB_ID(0x3), FETCH_SIZE(SIZE64), PTLB_DIS, STLB_DIS)
		 STREAM_MATCH_CFG(DIR_READ)
		 STREAM_MATCH_SID_VALUE(0xA7)
		 STREAM_MATCH_SID_MASK(0x3FF)>,
		<21 STREAM_CFG(PTLB_ID(0x3), STLB_ID(0x20), FETCH_SIZE(SIZE2), PTLB_EN, STLB_EN)
		 STREAM_MATCH_CFG(DIR_READ)
		 STREAM_MATCH_SID_VALUE(0x1A7)
		 STREAM_MATCH_SID_MASK(0x3FF)>,
		<22 STREAM_CFG(PTLB_ID(0x3), STLB_ID(0x21), FETCH_SIZE(SIZE2), PTLB_EN, STLB_EN)
		 STREAM_MATCH_CFG(DIR_READ)
		 STREAM_MATCH_SID_VALUE(0x2A7)
		 STREAM_MATCH_SID_MASK(0x3FF)>,
		<23 STREAM_CFG(PTLB_ID(0x3), STLB_ID(0x22), FETCH_SIZE(SIZE2), PTLB_EN, STLB_EN)
		 STREAM_MATCH_CFG(DIR_READ)
		 STREAM_MATCH_SID_VALUE(0x3A7)
		 STREAM_MATCH_SID_MASK(0x3FF)>,
		<24 STREAM_CFG(PTLB_ID(0x4), STLB_ID(0x1C), FETCH_SIZE(SIZE2), PTLB_EN, STLB_EN)
		 STREAM_MATCH_CFG(DIR_READ)
		 STREAM_MATCH_SID_VALUE(0x44)
		 STREAM_MATCH_SID_MASK(0x3FF)>,
		<25 STREAM_CFG(PTLB_ID(0x4), STLB_ID(0x1D), FETCH_SIZE(SIZE2), PTLB_EN, STLB_EN)
		 STREAM_MATCH_CFG(DIR_READ)
		 STREAM_MATCH_SID_VALUE(0x144)
		 STREAM_MATCH_SID_MASK(0x3FF)>,
		<26 STREAM_CFG(PTLB_ID(0x4), STLB_ID(0x1E), FETCH_SIZE(SIZE2), PTLB_EN, STLB_EN)
		 STREAM_MATCH_CFG(DIR_READ)
		 STREAM_MATCH_SID_VALUE(0x244)
		 STREAM_MATCH_SID_MASK(0x3FF)>,
		<27 STREAM_CFG(PTLB_ID(0x4), STLB_ID(0x1F), FETCH_SIZE(SIZE2), PTLB_EN, STLB_EN)
		 STREAM_MATCH_CFG(DIR_READ)
		 STREAM_MATCH_SID_VALUE(0x344)
		 STREAM_MATCH_SID_MASK(0x3FF)>,
		<28 STREAM_CFG(PTLB_ID(0x4), STLB_ID(0x23), FETCH_SIZE(SIZE2), PTLB_EN, STLB_EN)
		 STREAM_MATCH_CFG(DIR_READ)
		 STREAM_MATCH_SID_VALUE(0xC4)
		 STREAM_MATCH_SID_MASK(0x3FF)>,
		<29 STREAM_CFG(PTLB_ID(0x4), STLB_ID(0x24), FETCH_SIZE(SIZE2), PTLB_EN, STLB_EN)
		 STREAM_MATCH_CFG(DIR_READ)
		 STREAM_MATCH_SID_VALUE(0x1C4)
		 STREAM_MATCH_SID_MASK(0x3FF)>,
		<30 STREAM_CFG(PTLB_ID(0x4), STLB_ID(0x33), FETCH_SIZE(SIZE1), PTLB_EN, STLB_EN)
		 STREAM_MATCH_CFG(DIR_READ)
		 STREAM_MATCH_SID_VALUE(0x2C4)
		 STREAM_MATCH_SID_MASK(0x3FF)>,
		<31 STREAM_CFG(PTLB_ID(0x5), STLB_ID(0x25), FETCH_SIZE(SIZE2), PTLB_EN, STLB_EN)
		 STREAM_MATCH_CFG(DIR_READ)
		 STREAM_MATCH_SID_VALUE(0xE5)
		 STREAM_MATCH_SID_MASK(0x3FF)>,
		<32 STREAM_CFG(PTLB_ID(0x5), STLB_ID(0x34), FETCH_SIZE(SIZE1), PTLB_EN, STLB_EN)
		 STREAM_MATCH_CFG(DIR_READ)
		 STREAM_MATCH_SID_VALUE(0x1E5)
		 STREAM_MATCH_SID_MASK(0x3FF)>,
		<33 STREAM_CFG(PTLB_ID(0x5), STLB_ID(0x35), FETCH_SIZE(SIZE1), PTLB_EN, STLB_EN)
		 STREAM_MATCH_CFG(DIR_READ)
		 STREAM_MATCH_SID_VALUE(0x2E5)
		 STREAM_MATCH_SID_MASK(0x3FF)>,
		<34 STREAM_CFG(PTLB_ID(0x6), STLB_ID(0x8), FETCH_SIZE(SIZE16), PTLB_EN, STLB_EN)
		 STREAM_MATCH_CFG(DIR_READ)
		 STREAM_MATCH_SID_VALUE(0xA)
		 STREAM_MATCH_SID_MASK(0x3FF)>,
		<35 STREAM_CFG(PTLB_ID(0x6), STLB_ID(0x2), FETCH_SIZE(SIZE64), PTLB_DIS, STLB_DIS)
		 STREAM_MATCH_CFG(DIR_READ)
		 STREAM_MATCH_SID_VALUE(0x8A)
		 STREAM_MATCH_SID_MASK(0x3FF)>,
		<36 STREAM_CFG(PTLB_ID(0x6), STLB_ID(0x9), FETCH_SIZE(SIZE16), PTLB_EN, STLB_EN)
		 STREAM_MATCH_CFG(DIR_READ)
		 STREAM_MATCH_SID_VALUE(0x10A)
		 STREAM_MATCH_SID_MASK(0x3FF)>,
		<37 STREAM_CFG(PTLB_ID(0x6), STLB_ID(0xA), FETCH_SIZE(SIZE16), PTLB_EN, STLB_EN)
		 STREAM_MATCH_CFG(DIR_READ)
		 STREAM_MATCH_SID_VALUE(0x20A)
		 STREAM_MATCH_SID_MASK(0x3FF)>,
		<38 STREAM_CFG(PTLB_ID(0x6), STLB_ID(0xB), FETCH_SIZE(SIZE16), PTLB_EN, STLB_EN)
		 STREAM_MATCH_CFG(DIR_READ)
		 STREAM_MATCH_SID_VALUE(0x30A)
		 STREAM_MATCH_SID_MASK(0x3FF)>,
		<39 STREAM_CFG(PTLB_ID(0x6), STLB_ID(0x19), FETCH_SIZE(SIZE2), PTLB_EN, STLB_EN)
		 STREAM_MATCH_CFG(DIR_READ)
		 STREAM_MATCH_SID_VALUE(0x18A)
		 STREAM_MATCH_SID_MASK(0x3FF)>,
		<40 STREAM_CFG(PTLB_ID(0x6), STLB_ID(0x1A), FETCH_SIZE(SIZE2), PTLB_EN, STLB_EN)
		 STREAM_MATCH_CFG(DIR_READ)
		 STREAM_MATCH_SID_VALUE(0x28A)
		 STREAM_MATCH_SID_MASK(0x3FF)>,
		<41 STREAM_CFG(PTLB_ID(0x6), STLB_ID(0x1B), FETCH_SIZE(SIZE2), PTLB_EN, STLB_EN)
		 STREAM_MATCH_CFG(DIR_READ)
		 STREAM_MATCH_SID_VALUE(0x38A)
		 STREAM_MATCH_SID_MASK(0x3FF)>,
		<42 STREAM_CFG(PTLB_ID(0x7), STLB_ID(0x1C), FETCH_SIZE(SIZE2), PTLB_EN, STLB_EN)
		 STREAM_MATCH_CFG(DIR_READ)
		 STREAM_MATCH_SID_VALUE(0x48)
		 STREAM_MATCH_SID_MASK(0x3FF)>,
		<43 STREAM_CFG(PTLB_ID(0x7), STLB_ID(0x1D), FETCH_SIZE(SIZE2), PTLB_EN, STLB_EN)
		 STREAM_MATCH_CFG(DIR_READ)
		 STREAM_MATCH_SID_VALUE(0x148)
		 STREAM_MATCH_SID_MASK(0x3FF)>,
		<44 STREAM_CFG(PTLB_ID(0x7), STLB_ID(0x1E), FETCH_SIZE(SIZE2), PTLB_EN, STLB_EN)
		 STREAM_MATCH_CFG(DIR_READ)
		 STREAM_MATCH_SID_VALUE(0x248)
		 STREAM_MATCH_SID_MASK(0x3FF)>,
		<45 STREAM_CFG(PTLB_ID(0x7), STLB_ID(0x1F), FETCH_SIZE(SIZE2), PTLB_EN, STLB_EN)
		 STREAM_MATCH_CFG(DIR_READ)
		 STREAM_MATCH_SID_VALUE(0x348)
		 STREAM_MATCH_SID_MASK(0x3FF)>,
		<46 STREAM_CFG(PTLB_ID(0x8), STLB_ID(0x8), FETCH_SIZE(SIZE16), PTLB_EN, STLB_EN)
		 STREAM_MATCH_CFG(DIR_READ)
		 STREAM_MATCH_SID_VALUE(0xE)
		 STREAM_MATCH_SID_MASK(0x3FF)>,
		<47 STREAM_CFG(PTLB_ID(0x8), STLB_ID(0x2), FETCH_SIZE(SIZE64), PTLB_DIS, STLB_DIS)
		 STREAM_MATCH_CFG(DIR_READ)
		 STREAM_MATCH_SID_VALUE(0x8E)
		 STREAM_MATCH_SID_MASK(0x3FF)>,
		<48 STREAM_CFG(PTLB_ID(0x8), STLB_ID(0x9), FETCH_SIZE(SIZE16), PTLB_EN, STLB_EN)
		 STREAM_MATCH_CFG(DIR_READ)
		 STREAM_MATCH_SID_VALUE(0x10E)
		 STREAM_MATCH_SID_MASK(0x3FF)>,
		<49 STREAM_CFG(PTLB_ID(0x8), STLB_ID(0xA), FETCH_SIZE(SIZE16), PTLB_EN, STLB_EN)
		 STREAM_MATCH_CFG(DIR_READ)
		 STREAM_MATCH_SID_VALUE(0x20E)
		 STREAM_MATCH_SID_MASK(0x3FF)>,
		<50 STREAM_CFG(PTLB_ID(0x8), STLB_ID(0xB), FETCH_SIZE(SIZE16), PTLB_EN, STLB_EN)
		 STREAM_MATCH_CFG(DIR_READ)
		 STREAM_MATCH_SID_VALUE(0x30E)
		 STREAM_MATCH_SID_MASK(0x3FF)>,
		<51 STREAM_CFG(PTLB_ID(0x8), STLB_ID(0x19), FETCH_SIZE(SIZE2), PTLB_EN, STLB_EN)
		 STREAM_MATCH_CFG(DIR_READ)
		 STREAM_MATCH_SID_VALUE(0x18E)
		 STREAM_MATCH_SID_MASK(0x3FF)>,
		<52 STREAM_CFG(PTLB_ID(0x8), STLB_ID(0x1A), FETCH_SIZE(SIZE2), PTLB_EN, STLB_EN)
		 STREAM_MATCH_CFG(DIR_READ)
		 STREAM_MATCH_SID_VALUE(0x28E)
		 STREAM_MATCH_SID_MASK(0x3FF)>,
		<53 STREAM_CFG(PTLB_ID(0x8), STLB_ID(0x1B), FETCH_SIZE(SIZE2), PTLB_EN, STLB_EN)
		 STREAM_MATCH_CFG(DIR_READ)
		 STREAM_MATCH_SID_VALUE(0x38E)
		 STREAM_MATCH_SID_MASK(0x3FF)>,
		<54 STREAM_CFG(PTLB_ID(0x9), STLB_ID(0x3), FETCH_SIZE(SIZE64), PTLB_DIS, STLB_DIS)
		 STREAM_MATCH_CFG(DIR_READ)
		 STREAM_MATCH_SID_VALUE(0xAF)
		 STREAM_MATCH_SID_MASK(0x3FF)>,
		<55 STREAM_CFG(PTLB_ID(0x9), STLB_ID(0x20), FETCH_SIZE(SIZE2), PTLB_EN, STLB_EN)
		 STREAM_MATCH_CFG(DIR_READ)
		 STREAM_MATCH_SID_VALUE(0x1AF)
		 STREAM_MATCH_SID_MASK(0x3FF)>,
		<56 STREAM_CFG(PTLB_ID(0x9), STLB_ID(0x21), FETCH_SIZE(SIZE2), PTLB_EN, STLB_EN)
		 STREAM_MATCH_CFG(DIR_READ)
		 STREAM_MATCH_SID_VALUE(0x2AF)
		 STREAM_MATCH_SID_MASK(0x3FF)>,
		<57 STREAM_CFG(PTLB_ID(0x9), STLB_ID(0x22), FETCH_SIZE(SIZE2), PTLB_EN, STLB_EN)
		 STREAM_MATCH_CFG(DIR_READ)
		 STREAM_MATCH_SID_VALUE(0x3AF)
		 STREAM_MATCH_SID_MASK(0x3FF)>,
		<58 STREAM_CFG(PTLB_ID(0xA), STLB_ID(0x1C), FETCH_SIZE(SIZE2), PTLB_EN, STLB_EN)
		 STREAM_MATCH_CFG(DIR_READ)
		 STREAM_MATCH_SID_VALUE(0x4C)
		 STREAM_MATCH_SID_MASK(0x3FF)>,
		<59 STREAM_CFG(PTLB_ID(0xA), STLB_ID(0x1D), FETCH_SIZE(SIZE2), PTLB_EN, STLB_EN)
		 STREAM_MATCH_CFG(DIR_READ)
		 STREAM_MATCH_SID_VALUE(0x14C)
		 STREAM_MATCH_SID_MASK(0x3FF)>,
		<60 STREAM_CFG(PTLB_ID(0xA), STLB_ID(0x1E), FETCH_SIZE(SIZE2), PTLB_EN, STLB_EN)
		 STREAM_MATCH_CFG(DIR_READ)
		 STREAM_MATCH_SID_VALUE(0x24C)
		 STREAM_MATCH_SID_MASK(0x3FF)>,
		<61 STREAM_CFG(PTLB_ID(0xA), STLB_ID(0x1F), FETCH_SIZE(SIZE2), PTLB_EN, STLB_EN)
		 STREAM_MATCH_CFG(DIR_READ)
		 STREAM_MATCH_SID_VALUE(0x34C)
		 STREAM_MATCH_SID_MASK(0x3FF)>,
		<62 STREAM_CFG(PTLB_ID(0xA), STLB_ID(0x23), FETCH_SIZE(SIZE2), PTLB_EN, STLB_EN)
		 STREAM_MATCH_CFG(DIR_READ)
		 STREAM_MATCH_SID_VALUE(0xCC)
		 STREAM_MATCH_SID_MASK(0x3FF)>,
		<63 STREAM_CFG(PTLB_ID(0xA), STLB_ID(0x24), FETCH_SIZE(SIZE2), PTLB_EN, STLB_EN)
		 STREAM_MATCH_CFG(DIR_READ)
		 STREAM_MATCH_SID_VALUE(0x1CC)
		 STREAM_MATCH_SID_MASK(0x3FF)>,
		<64 STREAM_CFG(PTLB_ID(0xA), STLB_ID(0x33), FETCH_SIZE(SIZE1), PTLB_EN, STLB_EN)
		 STREAM_MATCH_CFG(DIR_READ)
		 STREAM_MATCH_SID_VALUE(0x2CC)
		 STREAM_MATCH_SID_MASK(0x3FF)>,
		<65 STREAM_CFG(PTLB_ID(0xB), STLB_ID(0x25), FETCH_SIZE(SIZE2), PTLB_EN, STLB_EN)
		 STREAM_MATCH_CFG(DIR_READ)
		 STREAM_MATCH_SID_VALUE(0xED)
		 STREAM_MATCH_SID_MASK(0x3FF)>,
		<66 STREAM_CFG(PTLB_ID(0xB), STLB_ID(0x34), FETCH_SIZE(SIZE1), PTLB_EN, STLB_EN)
		 STREAM_MATCH_CFG(DIR_READ)
		 STREAM_MATCH_SID_VALUE(0x1ED)
		 STREAM_MATCH_SID_MASK(0x3FF)>,
		<67 STREAM_CFG(PTLB_ID(0xB), STLB_ID(0x35), FETCH_SIZE(SIZE1), PTLB_EN, STLB_EN)
		 STREAM_MATCH_CFG(DIR_READ)
		 STREAM_MATCH_SID_VALUE(0x2ED)
		 STREAM_MATCH_SID_MASK(0x3FF)>,
		<68 STREAM_CFG(PTLB_ID(0xD), STLB_ID(0x3A), FETCH_SIZE(SIZE1), PTLB_EN, STLB_EN)
		 STREAM_MATCH_CFG(DIR_READ)
		 STREAM_MATCH_SID_VALUE(0x12)
		 STREAM_MATCH_SID_MASK(0x3FF)>,
		<69 STREAM_CFG(PTLB_ID(0xE), STLB_ID(0x3C), FETCH_SIZE(SIZE1), PTLB_DIS, STLB_DIS)
		 STREAM_MATCH_CFG(DIR_WRITE)
		 STREAM_MATCH_SID_VALUE(0x0)
		 STREAM_MATCH_SID_MASK(0x3FF)>;
	};

	sysmmu_icpu_s0_stream: sysmmu_icpu_s0_stream {
		pmmu0,default_stream =
		<STREAM_CFG(PTLB_ID(0x0), STLB_ID(0x0), FETCH_SIZE(SIZE1), PTLB_DIS, STLB_DIS)>;
		pmmu0,stream_property =
		<1 STREAM_CFG(PTLB_ID(0x1), STLB_ID(0x1), FETCH_SIZE(SIZE1), PTLB_EN, STLB_EN)
		 STREAM_MATCH_CFG(DIR_RW)
		 STREAM_MATCH_SID_VALUE(0x1)
		 STREAM_MATCH_SID_MASK(0x1)>;
	};

	sysmmu_lme_s0_stream: sysmmu_lme_s0_stream {
		pmmu0,default_stream =
		<STREAM_CFG(PTLB_ID(0x0), STLB_ID(0x0), FETCH_SIZE(SIZE8), PTLB_EN, STLB_EN)>;
		pmmu0,stream_property =
		<1 STREAM_CFG(PTLB_ID(0x4), STLB_ID(0x8), FETCH_SIZE(SIZE1), PTLB_EN, STLB_EN)
		 STREAM_MATCH_CFG(DIR_READ)
		 STREAM_MATCH_SID_VALUE(0x8)
		 STREAM_MATCH_SID_MASK(0x1F)>,
		<2 STREAM_CFG(PTLB_ID(0x2), STLB_ID(0x1), FETCH_SIZE(SIZE4), PTLB_EN, STLB_EN)
		 STREAM_MATCH_CFG(DIR_WRITE)
		 STREAM_MATCH_SID_VALUE(0x0)
		 STREAM_MATCH_SID_MASK(0x1F)>,
		<3 STREAM_CFG(PTLB_ID(0x5), STLB_ID(0x9), FETCH_SIZE(SIZE1), PTLB_EN, STLB_EN)
		 STREAM_MATCH_CFG(DIR_WRITE)
		 STREAM_MATCH_SID_VALUE(0x8)
		 STREAM_MATCH_SID_MASK(0x1F)>,
		<4 STREAM_CFG(PTLB_ID(0x3), STLB_ID(0x2), FETCH_SIZE(SIZE4), PTLB_EN, STLB_EN)
		 STREAM_MATCH_CFG(DIR_WRITE)
		 STREAM_MATCH_SID_VALUE(0x10)
		 STREAM_MATCH_SID_MASK(0x1F)>,
		<5 STREAM_CFG(PTLB_ID(0x6), STLB_ID(0xA), FETCH_SIZE(SIZE1), PTLB_EN, STLB_EN)
		 STREAM_MATCH_CFG(DIR_WRITE)
		 STREAM_MATCH_SID_VALUE(0x18)
		 STREAM_MATCH_SID_MASK(0x1F)>,
		<6 STREAM_CFG(PTLB_ID(0x1), STLB_ID(0x3), FETCH_SIZE(SIZE8), PTLB_EN, STLB_EN)
		 STREAM_MATCH_CFG(DIR_READ)
		 STREAM_MATCH_SID_VALUE(0x1)
		 STREAM_MATCH_SID_MASK(0x1F)>,
		<7 STREAM_CFG(PTLB_ID(0x7), STLB_ID(0xB), FETCH_SIZE(SIZE1), PTLB_EN, STLB_EN)
		 STREAM_MATCH_CFG(DIR_READ)
		 STREAM_MATCH_SID_VALUE(0x9)
		 STREAM_MATCH_SID_MASK(0x1F)>,
		<8 STREAM_CFG(PTLB_ID(0x8), STLB_ID(0x16), FETCH_SIZE(SIZE1), PTLB_DIS, STLB_DIS)
		 STREAM_MATCH_CFG(DIR_WRITE)
		 STREAM_MATCH_SID_VALUE(0x2)
		 STREAM_MATCH_SID_MASK(0x1F)>,
		<9 STREAM_CFG(PTLB_ID(0xA), STLB_ID(0x1B), FETCH_SIZE(SIZE1), PTLB_DIS, STLB_DIS)
		 STREAM_MATCH_CFG(DIR_WRITE)
		 STREAM_MATCH_SID_VALUE(0x3)
		 STREAM_MATCH_SID_MASK(0x1F)>,
		<10 STREAM_CFG(PTLB_ID(0x9), STLB_ID(0x18), FETCH_SIZE(SIZE1), PTLB_DIS, STLB_DIS)
		 STREAM_MATCH_CFG(DIR_READ)
		 STREAM_MATCH_SID_VALUE(0x4)
		 STREAM_MATCH_SID_MASK(0x1F)>;
		pmmu1,default_stream =
		<STREAM_CFG(PTLB_ID(0x0), STLB_ID(0x4), FETCH_SIZE(SIZE8), PTLB_EN, STLB_EN)>;
		pmmu1,stream_property =
		<1 STREAM_CFG(PTLB_ID(0x4), STLB_ID(0xC), FETCH_SIZE(SIZE1), PTLB_EN, STLB_EN)
		 STREAM_MATCH_CFG(DIR_READ)
		 STREAM_MATCH_SID_VALUE(0x8)
		 STREAM_MATCH_SID_MASK(0x1F)>,
		<2 STREAM_CFG(PTLB_ID(0x2), STLB_ID(0x5), FETCH_SIZE(SIZE4), PTLB_EN, STLB_EN)
		 STREAM_MATCH_CFG(DIR_WRITE)
		 STREAM_MATCH_SID_VALUE(0x0)
		 STREAM_MATCH_SID_MASK(0x1F)>,
		<3 STREAM_CFG(PTLB_ID(0x5), STLB_ID(0xD), FETCH_SIZE(SIZE1), PTLB_EN, STLB_EN)
		 STREAM_MATCH_CFG(DIR_WRITE)
		 STREAM_MATCH_SID_VALUE(0x8)
		 STREAM_MATCH_SID_MASK(0x1F)>,
		<4 STREAM_CFG(PTLB_ID(0x3), STLB_ID(0x6), FETCH_SIZE(SIZE4), PTLB_EN, STLB_EN)
		 STREAM_MATCH_CFG(DIR_WRITE)
		 STREAM_MATCH_SID_VALUE(0x10)
		 STREAM_MATCH_SID_MASK(0x1F)>,
		<5 STREAM_CFG(PTLB_ID(0x6), STLB_ID(0xE), FETCH_SIZE(SIZE1), PTLB_EN, STLB_EN)
		 STREAM_MATCH_CFG(DIR_WRITE)
		 STREAM_MATCH_SID_VALUE(0x18)
		 STREAM_MATCH_SID_MASK(0x1F)>,
		<6 STREAM_CFG(PTLB_ID(0x1), STLB_ID(0x7), FETCH_SIZE(SIZE8), PTLB_EN, STLB_EN)
		 STREAM_MATCH_CFG(DIR_READ)
		 STREAM_MATCH_SID_VALUE(0x1)
		 STREAM_MATCH_SID_MASK(0x1F)>,
		<7 STREAM_CFG(PTLB_ID(0x7), STLB_ID(0xF), FETCH_SIZE(SIZE1), PTLB_EN, STLB_EN)
		 STREAM_MATCH_CFG(DIR_READ)
		 STREAM_MATCH_SID_VALUE(0x9)
		 STREAM_MATCH_SID_MASK(0x1F)>,
		<8 STREAM_CFG(PTLB_ID(0x8), STLB_ID(0x17), FETCH_SIZE(SIZE1), PTLB_DIS, STLB_DIS)
		 STREAM_MATCH_CFG(DIR_WRITE)
		 STREAM_MATCH_SID_VALUE(0x2)
		 STREAM_MATCH_SID_MASK(0x1F)>,
		<9 STREAM_CFG(PTLB_ID(0xA), STLB_ID(0x1C), FETCH_SIZE(SIZE1), PTLB_DIS, STLB_DIS)
		 STREAM_MATCH_CFG(DIR_WRITE)
		 STREAM_MATCH_SID_VALUE(0x3)
		 STREAM_MATCH_SID_MASK(0x1F)>,
		<10 STREAM_CFG(PTLB_ID(0x9), STLB_ID(0x19), FETCH_SIZE(SIZE1), PTLB_DIS, STLB_DIS)
		 STREAM_MATCH_CFG(DIR_READ)
		 STREAM_MATCH_SID_VALUE(0x4)
		 STREAM_MATCH_SID_MASK(0x1F)>;
		pmmu2,default_stream =
		<STREAM_CFG(PTLB_ID(0x6), STLB_ID(0x1A), FETCH_SIZE(SIZE1), PTLB_DIS, STLB_DIS)>;
		pmmu2,stream_property =
		<1 STREAM_CFG(PTLB_ID(0x0), STLB_ID(0x15), FETCH_SIZE(SIZE1), PTLB_DIS, STLB_DIS)
		 STREAM_MATCH_CFG(DIR_READ)
		 STREAM_MATCH_SID_VALUE(0x1)
		 STREAM_MATCH_SID_MASK(0x7)>,
		<2 STREAM_CFG(PTLB_ID(0x1), STLB_ID(0x10), FETCH_SIZE(SIZE1), PTLB_EN, STLB_EN)
		 STREAM_MATCH_CFG(DIR_READ)
		 STREAM_MATCH_SID_VALUE(0x2)
		 STREAM_MATCH_SID_MASK(0x7)>,
		<3 STREAM_CFG(PTLB_ID(0x2), STLB_ID(0x11), FETCH_SIZE(SIZE1), PTLB_EN, STLB_EN)
		 STREAM_MATCH_CFG(DIR_WRITE)
		 STREAM_MATCH_SID_VALUE(0x3)
		 STREAM_MATCH_SID_MASK(0x7)>,
		<4 STREAM_CFG(PTLB_ID(0x3), STLB_ID(0x12), FETCH_SIZE(SIZE1), PTLB_EN, STLB_EN)
		 STREAM_MATCH_CFG(DIR_WRITE)
		 STREAM_MATCH_SID_VALUE(0x4)
		 STREAM_MATCH_SID_MASK(0x7)>,
		<5 STREAM_CFG(PTLB_ID(0x4), STLB_ID(0x13), FETCH_SIZE(SIZE1), PTLB_EN, STLB_EN)
		 STREAM_MATCH_CFG(DIR_WRITE)
		 STREAM_MATCH_SID_VALUE(0x5)
		 STREAM_MATCH_SID_MASK(0x7)>,
		<6 STREAM_CFG(PTLB_ID(0x5), STLB_ID(0x14), FETCH_SIZE(SIZE1), PTLB_EN, STLB_EN)
		 STREAM_MATCH_CFG(DIR_WRITE)
		 STREAM_MATCH_SID_VALUE(0x6)
		 STREAM_MATCH_SID_MASK(0x7)>;
	};

	sysmmu_m2m_s0_stream: sysmmu_m2m_s0_stream {
		pmmu0,default_stream =
		<STREAM_CFG(PTLB_ID(0x0), STLB_ID(0xC), FETCH_SIZE(SIZE1), PTLB_DIS, STLB_EN)>;
		pmmu0,stream_property =
		<1 STREAM_CFG(PTLB_ID(0x1), STLB_ID(0xD), FETCH_SIZE(SIZE8), PTLB_DIS, STLB_DIS)
		 STREAM_MATCH_CFG(DIR_RW)
		 STREAM_MATCH_SID_VALUE(0x0)
		 STREAM_MATCH_SID_MASK(0x7F)>,
		<2 STREAM_CFG(PTLB_ID(0x2), STLB_ID(0xE), FETCH_SIZE(SIZE8), PTLB_DIS, STLB_DIS)
		 STREAM_MATCH_CFG(DIR_RW)
		 STREAM_MATCH_SID_VALUE(0x1)
		 STREAM_MATCH_SID_MASK(0x7F)>,
		<3 STREAM_CFG(PTLB_ID(0x4), STLB_ID(0x10), FETCH_SIZE(SIZE1), PTLB_DIS, STLB_DIS)
		 STREAM_MATCH_CFG(DIR_READ)
		 STREAM_MATCH_SID_VALUE(0xA)
		 STREAM_MATCH_SID_MASK(0x7F)>,
		<4 STREAM_CFG(PTLB_ID(0x5), STLB_ID(0x7), FETCH_SIZE(SIZE1), PTLB_DIS, STLB_EN)
		 STREAM_MATCH_CFG(DIR_WRITE)
		 STREAM_MATCH_SID_VALUE(0x22)
		 STREAM_MATCH_SID_MASK(0x7F)>,
		<5 STREAM_CFG(PTLB_ID(0x6), STLB_ID(0x8), FETCH_SIZE(SIZE1), PTLB_DIS, STLB_EN)
		 STREAM_MATCH_CFG(DIR_WRITE)
		 STREAM_MATCH_SID_VALUE(0x32)
		 STREAM_MATCH_SID_MASK(0x7F)>,
		<6 STREAM_CFG(PTLB_ID(0xA), STLB_ID(0x11), FETCH_SIZE(SIZE1), PTLB_DIS, STLB_DIS)
		 STREAM_MATCH_CFG(DIR_WRITE)
		 STREAM_MATCH_SID_VALUE(0xA)
		 STREAM_MATCH_SID_MASK(0x7F)>,
		<7 STREAM_CFG(PTLB_ID(0x3), STLB_ID(0xF), FETCH_SIZE(SIZE8), PTLB_DIS, STLB_DIS)
		 STREAM_MATCH_CFG(DIR_RW)
		 STREAM_MATCH_SID_VALUE(0x3)
		 STREAM_MATCH_SID_MASK(0x7F)>,
		<8 STREAM_CFG(PTLB_ID(0xB), STLB_ID(0x0), FETCH_SIZE(SIZE8), PTLB_EN, STLB_EN)
		 STREAM_MATCH_CFG(DIR_READ)
		 STREAM_MATCH_SID_VALUE(0x4)
		 STREAM_MATCH_SID_MASK(0x1F)>,
		<9 STREAM_CFG(PTLB_ID(0xC), STLB_ID(0x3), FETCH_SIZE(SIZE4), PTLB_EN, STLB_EN)
		 STREAM_MATCH_CFG(DIR_READ)
		 STREAM_MATCH_SID_VALUE(0xC)
		 STREAM_MATCH_SID_MASK(0x1F)>,
		<10 STREAM_CFG(PTLB_ID(0xD), STLB_ID(0x1), FETCH_SIZE(SIZE8), PTLB_EN, STLB_EN)
		 STREAM_MATCH_CFG(DIR_READ)
		 STREAM_MATCH_SID_VALUE(0x14)
		 STREAM_MATCH_SID_MASK(0x7F)>,
		<11 STREAM_CFG(PTLB_ID(0xE), STLB_ID(0x4), FETCH_SIZE(SIZE4), PTLB_EN, STLB_EN)
		 STREAM_MATCH_CFG(DIR_READ)
		 STREAM_MATCH_SID_VALUE(0x1C)
		 STREAM_MATCH_SID_MASK(0x7F)>,
		<12 STREAM_CFG(PTLB_ID(0xF), STLB_ID(0x2), FETCH_SIZE(SIZE8), PTLB_EN, STLB_EN)
		 STREAM_MATCH_CFG(DIR_READ)
		 STREAM_MATCH_SID_VALUE(0x24)
		 STREAM_MATCH_SID_MASK(0x7F)>,
		<13 STREAM_CFG(PTLB_ID(0x7), STLB_ID(0x9), FETCH_SIZE(SIZE1), PTLB_EN, STLB_EN)
		 STREAM_MATCH_CFG(DIR_READ)
		 STREAM_MATCH_SID_VALUE(0x2C)
		 STREAM_MATCH_SID_MASK(0x7F)>,
		<14 STREAM_CFG(PTLB_ID(0x10), STLB_ID(0x5), FETCH_SIZE(SIZE4), PTLB_DIS, STLB_EN)
		 STREAM_MATCH_CFG(DIR_WRITE)
		 STREAM_MATCH_SID_VALUE(0x4)
		 STREAM_MATCH_SID_MASK(0x7F)>,
		<15 STREAM_CFG(PTLB_ID(0x11), STLB_ID(0x6), FETCH_SIZE(SIZE2), PTLB_DIS, STLB_EN)
		 STREAM_MATCH_CFG(DIR_WRITE)
		 STREAM_MATCH_SID_VALUE(0xC)
		 STREAM_MATCH_SID_MASK(0x7F)>,
		<16 STREAM_CFG(PTLB_ID(0x8), STLB_ID(0xA), FETCH_SIZE(SIZE1), PTLB_DIS, STLB_EN)
		 STREAM_MATCH_CFG(DIR_WRITE)
		 STREAM_MATCH_SID_VALUE(0x14)
		 STREAM_MATCH_SID_MASK(0x7F)>,
		<17 STREAM_CFG(PTLB_ID(0x9), STLB_ID(0xB), FETCH_SIZE(SIZE1), PTLB_DIS, STLB_EN)
		 STREAM_MATCH_CFG(DIR_WRITE)
		 STREAM_MATCH_SID_VALUE(0x1C)
		 STREAM_MATCH_SID_MASK(0x7F)>,
		<18 STREAM_CFG(PTLB_ID(0x11), STLB_ID(0x6), FETCH_SIZE(SIZE2), PTLB_DIS, STLB_EN)
		 STREAM_MATCH_CFG(DIR_WRITE)
		 STREAM_MATCH_SID_VALUE(0x24)
		 STREAM_MATCH_SID_MASK(0x7F)>,
		<19 STREAM_CFG(PTLB_ID(0x10), STLB_ID(0x5), FETCH_SIZE(SIZE1), PTLB_DIS, STLB_EN)
		 STREAM_MATCH_CFG(DIR_WRITE)
		 STREAM_MATCH_SID_VALUE(0x2C)
		 STREAM_MATCH_SID_MASK(0x7F)>;
	};

	sysmmu_dlne_s0_stream: sysmmu_dlne_s0_stream {
		pmmu0,default_stream =
		<STREAM_CFG(PTLB_ID(0x0), STLB_ID(0x0), FETCH_SIZE(SIZE1), PTLB_DIS, STLB_DIS)>;
	};

	sysmmu_mcfp_s0_stream: sysmmu_mcfp_s0_stream {
		pmmu0,default_stream =
		<STREAM_CFG(PTLB_ID(0x0), STLB_ID(0x0), FETCH_SIZE(SIZE32), PTLB_EN, STLB_EN)>;
		pmmu0,stream_property =
		<1 STREAM_CFG(PTLB_ID(0x2), STLB_ID(0x3), FETCH_SIZE(SIZE1), PTLB_EN, STLB_EN)
		 STREAM_MATCH_CFG(DIR_READ)
		 STREAM_MATCH_SID_VALUE(0x4)
		 STREAM_MATCH_SID_MASK(0x1F)>,
		<2 STREAM_CFG(PTLB_ID(0x1), STLB_ID(0x0), FETCH_SIZE(SIZE32), PTLB_EN, STLB_EN)
		 STREAM_MATCH_CFG(DIR_READ)
		 STREAM_MATCH_SID_VALUE(0x1)
		 STREAM_MATCH_SID_MASK(0x1F)>,
		<3 STREAM_CFG(PTLB_ID(0x3), STLB_ID(0x3), FETCH_SIZE(SIZE1), PTLB_EN, STLB_EN)
		 STREAM_MATCH_CFG(DIR_READ)
		 STREAM_MATCH_SID_VALUE(0x5)
		 STREAM_MATCH_SID_MASK(0x1F)>,
		<4 STREAM_CFG(PTLB_ID(0x4), STLB_ID(0x7), FETCH_SIZE(SIZE1), PTLB_DIS, STLB_EN)
		 STREAM_MATCH_CFG(DIR_WRITE)
		 STREAM_MATCH_SID_VALUE(0x2)
		 STREAM_MATCH_SID_MASK(0x1F)>,
		<5 STREAM_CFG(PTLB_ID(0x5), STLB_ID(0x8), FETCH_SIZE(SIZE1), PTLB_DIS, STLB_EN)
		 STREAM_MATCH_CFG(DIR_WRITE)
		 STREAM_MATCH_SID_VALUE(0x6)
		 STREAM_MATCH_SID_MASK(0x1F)>,
		<6 STREAM_CFG(PTLB_ID(0x6), STLB_ID(0x9), FETCH_SIZE(SIZE1), PTLB_DIS, STLB_EN)
		 STREAM_MATCH_CFG(DIR_WRITE)
		 STREAM_MATCH_SID_VALUE(0xA)
		 STREAM_MATCH_SID_MASK(0x1F)>,
		<7 STREAM_CFG(PTLB_ID(0x7), STLB_ID(0xA), FETCH_SIZE(SIZE1), PTLB_DIS, STLB_EN)
		 STREAM_MATCH_CFG(DIR_WRITE)
		 STREAM_MATCH_SID_VALUE(0xE)
		 STREAM_MATCH_SID_MASK(0x1F)>,
		<8 STREAM_CFG(PTLB_ID(0x8), STLB_ID(0xB), FETCH_SIZE(SIZE1), PTLB_DIS, STLB_EN)
		 STREAM_MATCH_CFG(DIR_WRITE)
		 STREAM_MATCH_SID_VALUE(0x12)
		 STREAM_MATCH_SID_MASK(0x1F)>,
		<9 STREAM_CFG(PTLB_ID(0x9), STLB_ID(0xC), FETCH_SIZE(SIZE1), PTLB_DIS, STLB_EN)
		 STREAM_MATCH_CFG(DIR_WRITE)
		 STREAM_MATCH_SID_VALUE(0x3)
		 STREAM_MATCH_SID_MASK(0x1F)>,
		<10 STREAM_CFG(PTLB_ID(0x0), STLB_ID(0xD), FETCH_SIZE(SIZE1), PTLB_DIS, STLB_EN)
		 STREAM_MATCH_CFG(DIR_WRITE)
		 STREAM_MATCH_SID_VALUE(0xB)
		 STREAM_MATCH_SID_MASK(0x1F)>,
		<11 STREAM_CFG(PTLB_ID(0xA), STLB_ID(0xE), FETCH_SIZE(SIZE1), PTLB_DIS, STLB_EN)
		 STREAM_MATCH_CFG(DIR_WRITE)
		 STREAM_MATCH_SID_VALUE(0x13)
		 STREAM_MATCH_SID_MASK(0x1F)>;
		pmmu1,default_stream =
		<STREAM_CFG(PTLB_ID(0x0), STLB_ID(0x2), FETCH_SIZE(SIZE16), PTLB_EN, STLB_EN)>;
		pmmu1,stream_property =
		<1 STREAM_CFG(PTLB_ID(0x1), STLB_ID(0x4), FETCH_SIZE(SIZE1), PTLB_DIS, STLB_EN)
		 STREAM_MATCH_CFG(DIR_WRITE)
		 STREAM_MATCH_SID_VALUE(0x0)
		 STREAM_MATCH_SID_MASK(0xF)>,
		<2 STREAM_CFG(PTLB_ID(0x2), STLB_ID(0xF), FETCH_SIZE(SIZE1), PTLB_EN, STLB_EN)
		 STREAM_MATCH_CFG(DIR_READ)
		 STREAM_MATCH_SID_VALUE(0x1)
		 STREAM_MATCH_SID_MASK(0xF)>,
		<3 STREAM_CFG(PTLB_ID(0x3), STLB_ID(0x10), FETCH_SIZE(SIZE1), PTLB_EN, STLB_EN)
		 STREAM_MATCH_CFG(DIR_READ)
		 STREAM_MATCH_SID_VALUE(0x5)
		 STREAM_MATCH_SID_MASK(0xF)>,
		<4 STREAM_CFG(PTLB_ID(0x4), STLB_ID(0x11), FETCH_SIZE(SIZE1), PTLB_DIS, STLB_EN)
		 STREAM_MATCH_CFG(DIR_WRITE)
		 STREAM_MATCH_SID_VALUE(0x1)
		 STREAM_MATCH_SID_MASK(0xF)>,
		<5 STREAM_CFG(PTLB_ID(0x5), STLB_ID(0x12), FETCH_SIZE(SIZE1), PTLB_DIS, STLB_EN)
		 STREAM_MATCH_CFG(DIR_WRITE)
		 STREAM_MATCH_SID_VALUE(0x5)
		 STREAM_MATCH_SID_MASK(0xF)>,
		<6 STREAM_CFG(PTLB_ID(0x6), STLB_ID(0x2C), FETCH_SIZE(SIZE1), PTLB_DIS, STLB_DIS)
		 STREAM_MATCH_CFG(DIR_READ)
		 STREAM_MATCH_SID_VALUE(0x2)
		 STREAM_MATCH_SID_MASK(0xF)>,
		<7 STREAM_CFG(PTLB_ID(0x7), STLB_ID(0x2D), FETCH_SIZE(SIZE1), PTLB_DIS, STLB_DIS)
		 STREAM_MATCH_CFG(DIR_READ)
		 STREAM_MATCH_SID_VALUE(0x3)
		 STREAM_MATCH_SID_MASK(0xF)>;
		pmmu2,default_stream =
		<STREAM_CFG(PTLB_ID(0x0), STLB_ID(0x13), FETCH_SIZE(SIZE1), PTLB_EN, STLB_EN)>;
		pmmu2,stream_property =
		<1 STREAM_CFG(PTLB_ID(0x1), STLB_ID(0x14), FETCH_SIZE(SIZE1), PTLB_EN, STLB_EN)
		 STREAM_MATCH_CFG(DIR_READ)
		 STREAM_MATCH_SID_VALUE(0x10)
		 STREAM_MATCH_SID_MASK(0x1F)>,
		<2 STREAM_CFG(PTLB_ID(0x2), STLB_ID(0x15), FETCH_SIZE(SIZE1), PTLB_DIS, STLB_EN)
		 STREAM_MATCH_CFG(DIR_WRITE)
		 STREAM_MATCH_SID_VALUE(0x0)
		 STREAM_MATCH_SID_MASK(0x1F)>,
		<3 STREAM_CFG(PTLB_ID(0x3), STLB_ID(0x16), FETCH_SIZE(SIZE1), PTLB_DIS, STLB_EN)
		 STREAM_MATCH_CFG(DIR_WRITE)
		 STREAM_MATCH_SID_VALUE(0x10)
		 STREAM_MATCH_SID_MASK(0x1F)>,
		<4 STREAM_CFG(PTLB_ID(0x4), STLB_ID(0x17), FETCH_SIZE(SIZE1), PTLB_EN, STLB_EN)
		 STREAM_MATCH_CFG(DIR_READ)
		 STREAM_MATCH_SID_VALUE(0x1)
		 STREAM_MATCH_SID_MASK(0x1F)>,
		<5 STREAM_CFG(PTLB_ID(0x5), STLB_ID(0x18), FETCH_SIZE(SIZE1), PTLB_EN, STLB_EN)
		 STREAM_MATCH_CFG(DIR_READ)
		 STREAM_MATCH_SID_VALUE(0x2)
		 STREAM_MATCH_SID_MASK(0x1F)>,
		<6 STREAM_CFG(PTLB_ID(0x6), STLB_ID(0x19), FETCH_SIZE(SIZE1), PTLB_EN, STLB_EN)
		 STREAM_MATCH_CFG(DIR_READ)
		 STREAM_MATCH_SID_VALUE(0x3)
		 STREAM_MATCH_SID_MASK(0x1F)>,
		<7 STREAM_CFG(PTLB_ID(0x7), STLB_ID(0x1A), FETCH_SIZE(SIZE1), PTLB_EN, STLB_EN)
		 STREAM_MATCH_CFG(DIR_READ)
		 STREAM_MATCH_SID_VALUE(0x4)
		 STREAM_MATCH_SID_MASK(0x1F)>,
		<8 STREAM_CFG(PTLB_ID(0x8), STLB_ID(0x1B), FETCH_SIZE(SIZE1), PTLB_EN, STLB_EN)
		 STREAM_MATCH_CFG(DIR_READ)
		 STREAM_MATCH_SID_VALUE(0x5)
		 STREAM_MATCH_SID_MASK(0x1F)>,
		<9 STREAM_CFG(PTLB_ID(0x9), STLB_ID(0x5), FETCH_SIZE(SIZE1), PTLB_EN, STLB_EN)
		 STREAM_MATCH_CFG(DIR_READ)
		 STREAM_MATCH_SID_VALUE(0x6)
		 STREAM_MATCH_SID_MASK(0x1F)>,
		<10 STREAM_CFG(PTLB_ID(0xA), STLB_ID(0x1C), FETCH_SIZE(SIZE1), PTLB_EN, STLB_EN)
		 STREAM_MATCH_CFG(DIR_READ)
		 STREAM_MATCH_SID_VALUE(0x7)
		 STREAM_MATCH_SID_MASK(0x1F)>,
		<11 STREAM_CFG(PTLB_ID(0xB), STLB_ID(0x2A), FETCH_SIZE(SIZE1), PTLB_DIS, STLB_DIS)
		 STREAM_MATCH_CFG(DIR_WRITE)
		 STREAM_MATCH_SID_VALUE(0x8)
		 STREAM_MATCH_SID_MASK(0x1F)>,
		<12 STREAM_CFG(PTLB_ID(0xC), STLB_ID(0x2E), FETCH_SIZE(SIZE1), PTLB_DIS, STLB_DIS)
		 STREAM_MATCH_CFG(DIR_READ)
		 STREAM_MATCH_SID_VALUE(0x9)
		 STREAM_MATCH_SID_MASK(0x1F)>,
		<13 STREAM_CFG(PTLB_ID(0xD), STLB_ID(0x2F), FETCH_SIZE(SIZE1), PTLB_DIS, STLB_DIS)
		 STREAM_MATCH_CFG(DIR_WRITE)
		 STREAM_MATCH_SID_VALUE(0x9)
		 STREAM_MATCH_SID_MASK(0x1F)>;
		pmmu3,default_stream =
		<STREAM_CFG(PTLB_ID(0x0), STLB_ID(0x1), FETCH_SIZE(SIZE32), PTLB_EN, STLB_EN)>;
		pmmu3,stream_property =
		<1 STREAM_CFG(PTLB_ID(0x1), STLB_ID(0x6), FETCH_SIZE(SIZE1), PTLB_EN, STLB_EN)
		 STREAM_MATCH_CFG(DIR_READ)
		 STREAM_MATCH_SID_VALUE(0x4)
		 STREAM_MATCH_SID_MASK(0x1F)>,
		<2 STREAM_CFG(PTLB_ID(0x2), STLB_ID(0x1D), FETCH_SIZE(SIZE1), PTLB_DIS, STLB_EN)
		 STREAM_MATCH_CFG(DIR_WRITE)
		 STREAM_MATCH_SID_VALUE(0x1)
		 STREAM_MATCH_SID_MASK(0x1F)>,
		<3 STREAM_CFG(PTLB_ID(0x3), STLB_ID(0x1E), FETCH_SIZE(SIZE1), PTLB_DIS, STLB_EN)
		 STREAM_MATCH_CFG(DIR_WRITE)
		 STREAM_MATCH_SID_VALUE(0x9)
		 STREAM_MATCH_SID_MASK(0x1F)>,
		<4 STREAM_CFG(PTLB_ID(0x4), STLB_ID(0x1F), FETCH_SIZE(SIZE1), PTLB_DIS, STLB_EN)
		 STREAM_MATCH_CFG(DIR_WRITE)
		 STREAM_MATCH_SID_VALUE(0x11)
		 STREAM_MATCH_SID_MASK(0x1F)>,
		<5 STREAM_CFG(PTLB_ID(0x5), STLB_ID(0x20), FETCH_SIZE(SIZE1), PTLB_DIS, STLB_EN)
		 STREAM_MATCH_CFG(DIR_WRITE)
		 STREAM_MATCH_SID_VALUE(0x2)
		 STREAM_MATCH_SID_MASK(0x1F)>,
		<6 STREAM_CFG(PTLB_ID(0x6), STLB_ID(0x21), FETCH_SIZE(SIZE1), PTLB_DIS, STLB_EN)
		 STREAM_MATCH_CFG(DIR_WRITE)
		 STREAM_MATCH_SID_VALUE(0xA)
		 STREAM_MATCH_SID_MASK(0x1F)>,
		<7 STREAM_CFG(PTLB_ID(0x7), STLB_ID(0x22), FETCH_SIZE(SIZE1), PTLB_DIS, STLB_EN)
		 STREAM_MATCH_CFG(DIR_WRITE)
		 STREAM_MATCH_SID_VALUE(0x12)
		 STREAM_MATCH_SID_MASK(0x1F)>,
		<8 STREAM_CFG(PTLB_ID(0x8), STLB_ID(0x24), FETCH_SIZE(SIZE1), PTLB_EN, STLB_EN)
		 STREAM_MATCH_CFG(DIR_READ)
		 STREAM_MATCH_SID_VALUE(0x3)
		 STREAM_MATCH_SID_MASK(0x1F)>;
		pmmu4,default_stream =
		<STREAM_CFG(PTLB_ID(0x0), STLB_ID(0x1), FETCH_SIZE(SIZE32), PTLB_EN, STLB_EN)>;
		pmmu4,stream_property =
		<1 STREAM_CFG(PTLB_ID(0x1), STLB_ID(0x6), FETCH_SIZE(SIZE1), PTLB_EN, STLB_EN)
		 STREAM_MATCH_CFG(DIR_READ)
		 STREAM_MATCH_SID_VALUE(0x2)
		 STREAM_MATCH_SID_MASK(0x1F)>,
		<2 STREAM_CFG(PTLB_ID(0x2), STLB_ID(0x25), FETCH_SIZE(SIZE1), PTLB_DIS, STLB_EN)
		 STREAM_MATCH_CFG(DIR_WRITE)
		 STREAM_MATCH_SID_VALUE(0x1)
		 STREAM_MATCH_SID_MASK(0x1F)>,
		<3 STREAM_CFG(PTLB_ID(0x3), STLB_ID(0x26), FETCH_SIZE(SIZE1), PTLB_DIS, STLB_EN)
		 STREAM_MATCH_CFG(DIR_WRITE)
		 STREAM_MATCH_SID_VALUE(0x5)
		 STREAM_MATCH_SID_MASK(0x1F)>,
		<4 STREAM_CFG(PTLB_ID(0x4), STLB_ID(0x27), FETCH_SIZE(SIZE1), PTLB_DIS, STLB_EN)
		 STREAM_MATCH_CFG(DIR_WRITE)
		 STREAM_MATCH_SID_VALUE(0x9)
		 STREAM_MATCH_SID_MASK(0x1F)>,
		<5 STREAM_CFG(PTLB_ID(0x5), STLB_ID(0x28), FETCH_SIZE(SIZE1), PTLB_DIS, STLB_EN)
		 STREAM_MATCH_CFG(DIR_WRITE)
		 STREAM_MATCH_SID_VALUE(0xD)
		 STREAM_MATCH_SID_MASK(0x1F)>,
		<6 STREAM_CFG(PTLB_ID(0x6), STLB_ID(0x29), FETCH_SIZE(SIZE1), PTLB_DIS, STLB_EN)
		 STREAM_MATCH_CFG(DIR_WRITE)
		 STREAM_MATCH_SID_VALUE(0x15)
		 STREAM_MATCH_SID_MASK(0x1F)>,
		<7 STREAM_CFG(PTLB_ID(0x7), STLB_ID(0x2A), FETCH_SIZE(SIZE1), PTLB_DIS, STLB_EN)
		 STREAM_MATCH_CFG(DIR_WRITE)
		 STREAM_MATCH_SID_VALUE(0x2)
		 STREAM_MATCH_SID_MASK(0x1F)>,
		<8 STREAM_CFG(PTLB_ID(0x8), STLB_ID(0x2B), FETCH_SIZE(SIZE1), PTLB_EN, STLB_EN)
		 STREAM_MATCH_CFG(DIR_READ)
		 STREAM_MATCH_SID_VALUE(0x6)
		 STREAM_MATCH_SID_MASK(0x1F)>;
	};

	sysmmu_mfc_s0_stream: sysmmu_mfc_s0_stream {
		pmmu0,default_stream =
		<STREAM_CFG(PTLB_ID(0x0), STLB_ID(0x0), FETCH_SIZE(SIZE4), PTLB_DIS, STLB_DIS)>;
		pmmu1,default_stream =
		<STREAM_CFG(PTLB_ID(0x0), STLB_ID(0x1), FETCH_SIZE(SIZE4), PTLB_EN, STLB_EN)>;
		pmmu1,stream_property =
		<1 STREAM_CFG(PTLB_ID(0x2), STLB_ID(0x3), FETCH_SIZE(SIZE1), PTLB_DIS, STLB_DIS)
		 STREAM_MATCH_CFG(DIR_WRITE)
		 STREAM_MATCH_SID_VALUE(0x1)
		 STREAM_MATCH_SID_MASK(0x3)>,
		<2 STREAM_CFG(PTLB_ID(0x1), STLB_ID(0x2), FETCH_SIZE(SIZE1), PTLB_DIS, STLB_DIS)
		 STREAM_MATCH_CFG(DIR_RW)
		 STREAM_MATCH_SID_VALUE(0x2)
		 STREAM_MATCH_SID_MASK(0x3)>;
	};

	sysmmu_mfd_s0_stream: sysmmu_mfd_s0_stream {
		pmmu0,default_stream =
		<STREAM_CFG(PTLB_ID(0x0), STLB_ID(0x1), FETCH_SIZE(SIZE4), PTLB_DIS, STLB_DIS)>;
		pmmu1,default_stream =
		<STREAM_CFG(PTLB_ID(0x0), STLB_ID(0x0), FETCH_SIZE(SIZE4), PTLB_DIS, STLB_EN)>;
	};

	sysmmu_mfd_s1_stream: sysmmu_mfd_s1_stream {
		pmmu0,default_stream =
		<STREAM_CFG(PTLB_ID(0x0), STLB_ID(0x0), FETCH_SIZE(SIZE32), PTLB_EN, STLB_EN)>;
		pmmu0,stream_property =
		<1 STREAM_CFG(PTLB_ID(0x4), STLB_ID(0x4), FETCH_SIZE(SIZE1), PTLB_EN, STLB_EN)
		 STREAM_MATCH_CFG(DIR_READ)
		 STREAM_MATCH_SID_VALUE(0x2)
		 STREAM_MATCH_SID_MASK(0x7)>,
		<2 STREAM_CFG(PTLB_ID(0x2), STLB_ID(0x2), FETCH_SIZE(SIZE16), PTLB_EN, STLB_EN)
		 STREAM_MATCH_CFG(DIR_READ)
		 STREAM_MATCH_SID_VALUE(0x4)
		 STREAM_MATCH_SID_MASK(0x7)>,
		<3 STREAM_CFG(PTLB_ID(0x5), STLB_ID(0x5), FETCH_SIZE(SIZE1), PTLB_EN, STLB_EN)
		 STREAM_MATCH_CFG(DIR_READ)
		 STREAM_MATCH_SID_VALUE(0x6)
		 STREAM_MATCH_SID_MASK(0x7)>,
		<4 STREAM_CFG(PTLB_ID(0x3), STLB_ID(0x3), FETCH_SIZE(SIZE16), PTLB_DIS, STLB_EN)
		 STREAM_MATCH_CFG(DIR_WRITE)
		 STREAM_MATCH_SID_VALUE(0x0)
		 STREAM_MATCH_SID_MASK(0x7)>,
		<5 STREAM_CFG(PTLB_ID(0x6), STLB_ID(0x6), FETCH_SIZE(SIZE1), PTLB_DIS, STLB_EN)
		 STREAM_MATCH_CFG(DIR_WRITE)
		 STREAM_MATCH_SID_VALUE(0x2)
		 STREAM_MATCH_SID_MASK(0x7)>,
		<6 STREAM_CFG(PTLB_ID(0x1), STLB_ID(0x1), FETCH_SIZE(SIZE32), PTLB_DIS, STLB_EN)
		 STREAM_MATCH_CFG(DIR_WRITE)
		 STREAM_MATCH_SID_VALUE(0x1)
		 STREAM_MATCH_SID_MASK(0x7)>,
		<7 STREAM_CFG(PTLB_ID(0x7), STLB_ID(0x7), FETCH_SIZE(SIZE1), PTLB_DIS, STLB_EN)
		 STREAM_MATCH_CFG(DIR_WRITE)
		 STREAM_MATCH_SID_VALUE(0x3)
		 STREAM_MATCH_SID_MASK(0x7)>;
	};

	sysmmu_rgbp_s0_stream: sysmmu_rgbp_s0_stream {
		pmmu0,default_stream =
		<STREAM_CFG(PTLB_ID(0x8), STLB_ID(0xF), FETCH_SIZE(SIZE1), PTLB_DIS, STLB_DIS)>;
		pmmu0,stream_property =
		<1 STREAM_CFG(PTLB_ID(0x0), STLB_ID(0x0), FETCH_SIZE(SIZE1), PTLB_DIS, STLB_EN)
		 STREAM_MATCH_CFG(DIR_WRITE)
		 STREAM_MATCH_SID_VALUE(0x0)
		 STREAM_MATCH_SID_MASK(0xF)>,
		<2 STREAM_CFG(PTLB_ID(0x1), STLB_ID(0x1), FETCH_SIZE(SIZE1), PTLB_DIS, STLB_EN)
		 STREAM_MATCH_CFG(DIR_WRITE)
		 STREAM_MATCH_SID_VALUE(0x8)
		 STREAM_MATCH_SID_MASK(0xF)>,
		<3 STREAM_CFG(PTLB_ID(0x2), STLB_ID(0x2), FETCH_SIZE(SIZE1), PTLB_EN, STLB_EN)
		 STREAM_MATCH_CFG(DIR_READ)
		 STREAM_MATCH_SID_VALUE(0x1)
		 STREAM_MATCH_SID_MASK(0xF)>,
		<4 STREAM_CFG(PTLB_ID(0x3), STLB_ID(0x3), FETCH_SIZE(SIZE1), PTLB_DIS, STLB_EN)
		 STREAM_MATCH_CFG(DIR_WRITE)
		 STREAM_MATCH_SID_VALUE(0x1)
		 STREAM_MATCH_SID_MASK(0xF)>,
		<5 STREAM_CFG(PTLB_ID(0x4), STLB_ID(0x4), FETCH_SIZE(SIZE1), PTLB_DIS, STLB_EN)
		 STREAM_MATCH_CFG(DIR_WRITE)
		 STREAM_MATCH_SID_VALUE(0x9)
		 STREAM_MATCH_SID_MASK(0xF)>,
		<6 STREAM_CFG(PTLB_ID(0x5), STLB_ID(0x5), FETCH_SIZE(SIZE1), PTLB_DIS, STLB_EN)
		 STREAM_MATCH_CFG(DIR_WRITE)
		 STREAM_MATCH_SID_VALUE(0x2)
		 STREAM_MATCH_SID_MASK(0xF)>,
		<7 STREAM_CFG(PTLB_ID(0x9), STLB_ID(0x10), FETCH_SIZE(SIZE1), PTLB_DIS, STLB_DIS)
		 STREAM_MATCH_CFG(DIR_WRITE)
		 STREAM_MATCH_SID_VALUE(0x3)
		 STREAM_MATCH_SID_MASK(0xF)>,
		<8 STREAM_CFG(PTLB_ID(0x6), STLB_ID(0x6), FETCH_SIZE(SIZE1), PTLB_EN, STLB_EN)
		 STREAM_MATCH_CFG(DIR_READ)
		 STREAM_MATCH_SID_VALUE(0x4)
		 STREAM_MATCH_SID_MASK(0xF)>,
		<9 STREAM_CFG(PTLB_ID(0x7), STLB_ID(0x7), FETCH_SIZE(SIZE1), PTLB_EN, STLB_EN)
		 STREAM_MATCH_CFG(DIR_READ)
		 STREAM_MATCH_SID_VALUE(0xC)
		 STREAM_MATCH_SID_MASK(0xF)>;
		pmmu1,default_stream =
		<STREAM_CFG(PTLB_ID(0x0), STLB_ID(0x8), FETCH_SIZE(SIZE1), PTLB_EN, STLB_EN)>;
		pmmu1,stream_property =
		<1 STREAM_CFG(PTLB_ID(0x1), STLB_ID(0x9), FETCH_SIZE(SIZE1), PTLB_DIS, STLB_EN)
		 STREAM_MATCH_CFG(DIR_WRITE)
		 STREAM_MATCH_SID_VALUE(0x0)
		 STREAM_MATCH_SID_MASK(0xF)>,
		<2 STREAM_CFG(PTLB_ID(0x2), STLB_ID(0xA), FETCH_SIZE(SIZE1), PTLB_EN, STLB_EN)
		 STREAM_MATCH_CFG(DIR_READ)
		 STREAM_MATCH_SID_VALUE(0x1)
		 STREAM_MATCH_SID_MASK(0xF)>,
		<3 STREAM_CFG(PTLB_ID(0x3), STLB_ID(0xB), FETCH_SIZE(SIZE1), PTLB_DIS, STLB_EN)
		 STREAM_MATCH_CFG(DIR_WRITE)
		 STREAM_MATCH_SID_VALUE(0x1)
		 STREAM_MATCH_SID_MASK(0xF)>,
		<4 STREAM_CFG(PTLB_ID(0x4), STLB_ID(0xC), FETCH_SIZE(SIZE1), PTLB_DIS, STLB_EN)
		 STREAM_MATCH_CFG(DIR_WRITE)
		 STREAM_MATCH_SID_VALUE(0x5)
		 STREAM_MATCH_SID_MASK(0xF)>,
		<5 STREAM_CFG(PTLB_ID(0x5), STLB_ID(0xD), FETCH_SIZE(SIZE1), PTLB_EN, STLB_EN)
		 STREAM_MATCH_CFG(DIR_READ)
		 STREAM_MATCH_SID_VALUE(0x3)
		 STREAM_MATCH_SID_MASK(0xF)>,
		<6 STREAM_CFG(PTLB_ID(0x6), STLB_ID(0xE), FETCH_SIZE(SIZE1), PTLB_EN, STLB_EN)
		 STREAM_MATCH_CFG(DIR_READ)
		 STREAM_MATCH_SID_VALUE(0x7)
		 STREAM_MATCH_SID_MASK(0xF)>,
		<7 STREAM_CFG(PTLB_ID(0x7), STLB_ID(0x11), FETCH_SIZE(SIZE1), PTLB_DIS, STLB_DIS)
		 STREAM_MATCH_CFG(DIR_WRITE)
		 STREAM_MATCH_SID_VALUE(0x2)
		 STREAM_MATCH_SID_MASK(0xF)>;
	};

	sysmmu_yuvp_s0_stream: sysmmu_yuvp_s0_stream {
		pmmu0,default_stream =
		<STREAM_CFG(PTLB_ID(0x3), STLB_ID(0x8), FETCH_SIZE(SIZE1), PTLB_DIS, STLB_DIS)>;
		pmmu0,stream_property =
		<1 STREAM_CFG(PTLB_ID(0x4), STLB_ID(0x2), FETCH_SIZE(SIZE1), PTLB_DIS, STLB_DIS)
		 STREAM_MATCH_CFG(DIR_WRITE)
		 STREAM_MATCH_SID_VALUE(0x0)
		 STREAM_MATCH_SID_MASK(0x3)>,
		<2 STREAM_CFG(PTLB_ID(0x0), STLB_ID(0x3), FETCH_SIZE(SIZE1), PTLB_EN, STLB_EN)
		 STREAM_MATCH_CFG(DIR_READ)
		 STREAM_MATCH_SID_VALUE(0x1)
		 STREAM_MATCH_SID_MASK(0x3)>,
		<3 STREAM_CFG(PTLB_ID(0x1), STLB_ID(0x4), FETCH_SIZE(SIZE1), PTLB_EN, STLB_EN)
		 STREAM_MATCH_CFG(DIR_READ)
		 STREAM_MATCH_SID_VALUE(0x2)
		 STREAM_MATCH_SID_MASK(0x3)>,
		<4 STREAM_CFG(PTLB_ID(0x2), STLB_ID(0x5), FETCH_SIZE(SIZE1), PTLB_EN, STLB_EN)
		 STREAM_MATCH_CFG(DIR_READ)
		 STREAM_MATCH_SID_VALUE(0x3)
		 STREAM_MATCH_SID_MASK(0x3)>;
		pmmu1,default_stream =
		<STREAM_CFG(PTLB_ID(0x0), STLB_ID(0x6), FETCH_SIZE(SIZE1), PTLB_EN, STLB_EN)>;
		pmmu1,stream_property =
		<1 STREAM_CFG(PTLB_ID(0x1), STLB_ID(0x7), FETCH_SIZE(SIZE1), PTLB_EN, STLB_EN)
		 STREAM_MATCH_CFG(DIR_READ)
		 STREAM_MATCH_SID_VALUE(0x1)
		 STREAM_MATCH_SID_MASK(0x3)>,
		<2 STREAM_CFG(PTLB_ID(0x2), STLB_ID(0x0), FETCH_SIZE(SIZE16), PTLB_DIS, STLB_DIS)
		 STREAM_MATCH_CFG(DIR_READ)
		 STREAM_MATCH_SID_VALUE(0x2)
		 STREAM_MATCH_SID_MASK(0x3)>,
		<3 STREAM_CFG(PTLB_ID(0x3), STLB_ID(0x1), FETCH_SIZE(SIZE16), PTLB_DIS, STLB_DIS)
		 STREAM_MATCH_CFG(DIR_WRITE)
		 STREAM_MATCH_SID_VALUE(0x2)
		 STREAM_MATCH_SID_MASK(0x3)>;
	};
};
